VERSION ""

NS_ :

BS_:

BU_: VCM SCIM IC CCM

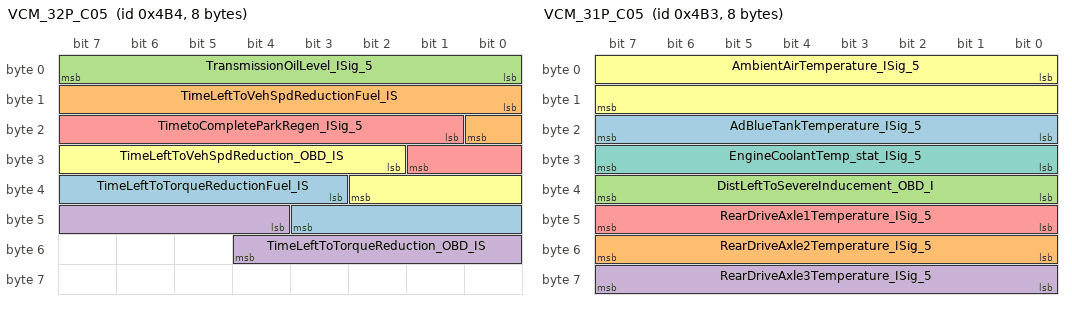
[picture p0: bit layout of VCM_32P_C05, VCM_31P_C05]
BO_ 1204 VCM_32P_C05: 8 VCM
 SG_ TimeLeftToTorqueReductionFuel_IS : 35|9@1+ (12,0) [0|6132] "min"  IC
 SG_ TimeLeftToVehSpdReductionFuel_IS : 8|9@1+ (15,0) [0|7665] "min"  IC
 SG_ TransmissionOilLevel_ISig_5 : 0|8@1+ (0.4,0) [0|102] "Percent"  IC
 SG_ TimeLeftToTorqueReduction_OBD_IS : 44|9@1+ (12,0) [0|6132] "min"  IC
 SG_ TimetoCompleteParkRegen_ISig_5 : 17|9@1+ (15,0) [0|7665] "min"  IC
 SG_ TimeLeftToVehSpdReduction_OBD_IS : 26|9@1+ (15,0) [0|7665] "min"  IC

BO_ 1203 VCM_31P_C05: 8 VCM
 SG_ AdBlueTankTemperature_ISig_5 : 16|8@1+ (1,-50) [-50|205] "DegreeC"  IC
 SG_ RearDriveAxle2Temperature_ISig_5 : 48|8@1+ (1,0) [0|255] "DegreeC"  IC
 SG_ DistLeftToSevereInducement_OBD_I : 32|8@1+ (5,0) [0|1275] "km"  IC
 SG_ RearDriveAxle3Temperature_ISig_5 : 56|8@1+ (1,0) [0|255] "DegreeC"  IC
 SG_ RearDriveAxle1Temperature_ISig_5 : 40|8@1+ (1,0) [0|255] "DegreeC"  IC
 SG_ AmbientAirTemperature_ISig_5 : 0|16@1+ (0.03125,-273) [-273|1774.96875] "DegreeC"  CCM,IC
 SG_ EngineCoolantTemp_stat_ISig_5 : 24|8@1+ (1,-40) [-40|215] "DegreeC"  CCM

BO_ 1202 VCM_30P_C05: 8 VCM
 SG_ FasUsrDefinedDampingSetting_ISig : 42|5@1+ (1,-10) [-10|21] ""  IC
 SG_ SCROperatorInducementSeverity_IS : 12|3@1+ (1,0) [0|0] ""  IC
 SG_ CatalystTankLevelLow_ISig_5 : 57|2@1+ (1,0) [0|0] ""  IC
 SG_ MIStatusExtEMS_ISig_5 : 61|2@1+ (1,0) [0|0] ""  IC
 SG_ FuelOperatorDeratingReason_ISig_ : 4|2@1+ (1,0) [0|0] ""  IC
 SG_ ActualFasPersSettingsButton_ISig : 18|3@1+ (1,0) [0|0] ""  IC
 SG_ BatteryEndOfCharge_ISig_5 : 0|2@1+ (1,0) [0|0] ""  IC
 SG_ FasUsrDefStiffStraightSetting_IS : 32|5@1+ (1,-10) [-10|21] ""  IC
 SG_ LiningWearWarning_ISig_5 : 2|2@1+ (1,0) [0|0] ""  IC
 SG_ TorqueReductionStatus_OBD_ISig_5 : 21|3@1+ (1,0) [0|0] ""  IC
 SG_ LoadCalibrationFeedback_ISig_5 : 9|3@1+ (1,0) [0|0] ""  IC
 SG_ FasUsrDefLowSpeedReturnSetting_I : 47|5@1+ (1,-10) [-10|21] ""  IC
 SG_ FuelOperatorDeratingSeverity_ISi : 6|3@1+ (1,0) [0|0] ""  IC
 SG_ FasUsrDefStiffnessCurveSetting_I : 37|5@1+ (1,-10) [-10|21] ""  IC
 SG_ SCROperatorInducementReason_ISig : 15|3@1+ (1,0) [0|0] ""  IC
 SG_ ActualFasManualOffsetSetting_ISi : 52|5@1+ (1,-10) [-10|21] ""  IC
 SG_ MIDistinctWarningExtEMS_ISig_5 : 24|4@1+ (1,0) [0|0] ""  IC
 SG_ FasDriver_ISig_5 : 28|4@1+ (1,0) [0|0] ""  IC
 SG_ MIDistinctWarning_ISig_5 : 59|2@1+ (1,0) [0|0] ""  IC

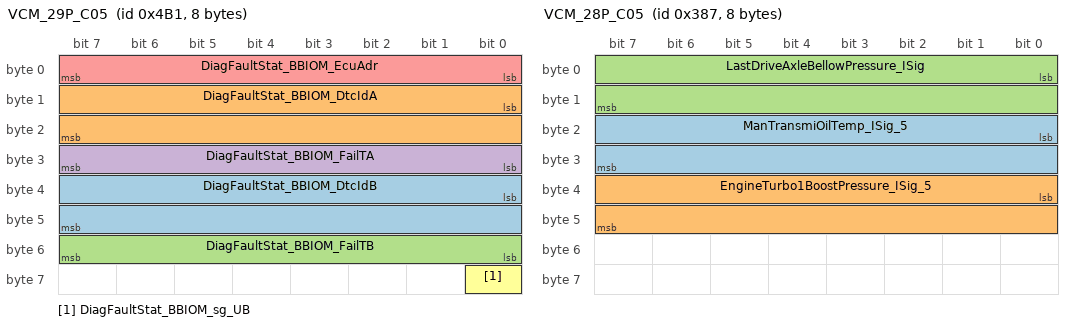
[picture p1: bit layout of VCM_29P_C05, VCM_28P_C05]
BO_ 1201 VCM_29P_C05: 8 VCM
 SG_ DiagFaultStat_BBIOM_DtcIdB : 32|16@1+ (1,0) [0|65535] ""  IC
 SG_ DiagFaultStat_BBIOM_DtcIdA : 8|16@1+ (1,0) [0|65535] ""  IC
 SG_ DiagFaultStat_BBIOM_FailTB : 48|8@1+ (1,0) [0|255] ""  IC
 SG_ DiagFaultStat_BBIOM_FailTA : 24|8@1+ (1,0) [0|255] ""  IC
 SG_ DiagFaultStat_BBIOM_EcuAdr : 0|8@1+ (1,0) [0|255] ""  IC
 SG_ DiagFaultStat_BBIOM_sg_UB : 56|1@1+ (1,0) [0|0] ""  IC

BO_ 903 VCM_28P_C05: 8 VCM
 SG_ ManTransmiOilTemp_ISig_5 : 16|16@1+ (0.03125,-273) [-273|1774.96875] "DegreeC"  IC
 SG_ EngineTurbo1BoostPressure_ISig_5 : 32|16@1+ (0.125,0) [0|8191.875] "kPa"  IC
 SG_ LastDriveAxleBellowPressure_ISig : 0|16@1+ (0.1,0) [0|6553.5] "kPa"  IC

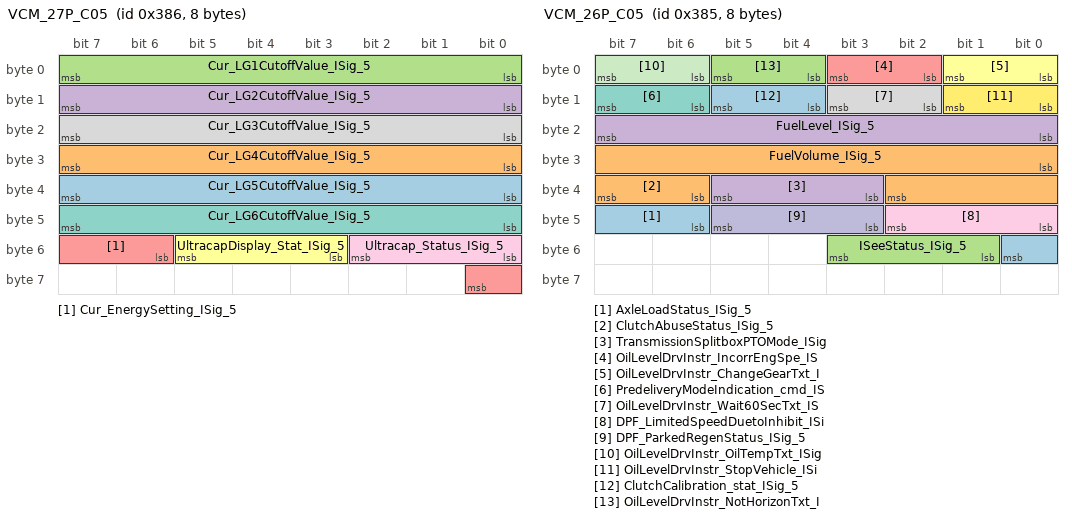
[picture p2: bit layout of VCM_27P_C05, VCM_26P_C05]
BO_ 902 VCM_27P_C05: 8 VCM
 SG_ Cur_LG5CutoffValue_ISig_5 : 32|8@1+ (1,0) [0|255] "Percent"  IC
 SG_ Cur_LG4CutoffValue_ISig_5 : 24|8@1+ (1,0) [0|255] "Percent"  IC
 SG_ Cur_LG1CutoffValue_ISig_5 : 0|8@1+ (1,0) [0|255] "Percent"  IC
 SG_ Cur_LG2CutoffValue_ISig_5 : 8|8@1+ (1,0) [0|255] "Percent"  IC
 SG_ Cur_EnergySetting_ISig_5 : 54|3@1+ (1,0) [0|0] ""  IC
 SG_ UltracapDisplay_Stat_ISig_5 : 51|3@1+ (1,0) [0|0] ""  IC
 SG_ Cur_LG6CutoffValue_ISig_5 : 40|8@1+ (1,0) [0|255] "Percent"  IC
 SG_ Cur_LG3CutoffValue_ISig_5 : 16|8@1+ (1,0) [0|255] "Percent"  IC
 SG_ Ultracap_Status_ISig_5 : 48|3@1+ (1,0) [0|0] ""  IC

BO_ 901 VCM_26P_C05: 8 VCM
 SG_ AxleLoadStatus_ISig_5 : 46|3@1+ (1,0) [0|0] ""  IC
 SG_ ClutchAbuseStatus_ISig_5 : 38|2@1+ (1,0) [0|0] ""  IC
 SG_ ISeeStatus_ISig_5 : 49|3@1+ (1,0) [0|0] ""  IC
 SG_ TransmissionSplitboxPTOMode_ISig : 35|3@1+ (1,0) [0|0] ""  IC
 SG_ OilLevelDrvInstr_IncorrEngSpe_IS : 2|2@1+ (1,0) [0|0] ""  IC
 SG_ OilLevelDrvInstr_ChangeGearTxt_I : 0|2@1+ (1,0) [0|0] ""  IC
 SG_ PredeliveryModeIndication_cmd_IS : 14|2@1+ (1,0) [0|0] ""  IC
 SG_ OilLevelDrvInstr_Wait60SecTxt_IS : 10|2@1+ (1,0) [0|0] ""  IC
 SG_ DPF_LimitedSpeedDuetoInhibit_ISi : 40|3@1+ (1,0) [0|0] ""  IC
 SG_ DPF_ParkedRegenStatus_ISig_5 : 43|3@1+ (1,0) [0|0] ""  IC
 SG_ OilLevelDrvInstr_OilTempTxt_ISig : 6|2@1+ (1,0) [0|0] ""  IC
 SG_ OilLevelDrvInstr_StopVehicle_ISi : 8|2@1+ (1,0) [0|0] ""  IC
 SG_ ClutchCalibration_stat_ISig_5 : 12|2@1+ (1,0) [0|0] ""  IC
 SG_ FuelVolume_ISig_5 : 24|11@1+ (1,0) [0|2047] "l"  CCM,IC
 SG_ OilLevelDrvInstr_NotHorizonTxt_I : 4|2@1+ (1,0) [0|0] ""  IC
 SG_ FuelLevel_ISig_5 : 16|8@1+ (0.4,0) [0|102] "Percent"  IC,CCM

BO_ 868 VCM_25P_C05: 8 VCM
 SG_ DrainPrimingStatus_ISig_5 : 60|3@1+ (1,0) [0|0] ""  IC
 SG_ FrontConspicLamp_stat_HiRight_IS : 0|3@1+ (1,0) [0|0] ""  IC
 SG_ FrontConspicLamp_stat_LoRight_IS : 3|3@1+ (1,0) [0|0] ""  IC
 SG_ CoolantTempHigh_ISig_5 : 54|3@1+ (1,0) [0|0] ""  IC
 SG_ AutoWheelBrakesStatus_ISig_5 : 32|3@1+ (1,0) [0|0] ""  IC
 SG_ OilLevelLow_ISig_5 : 51|3@1+ (1,0) [0|0] ""  IC
 SG_ InletAirHeaterStatus1_ISig_5 : 40|2@1+ (1,0) [0|0] ""  IC
 SG_ DeicingFunction_Stat_ISig_5 : 45|3@1+ (1,0) [0|0] ""  IC
 SG_ SelfStartAssist_stat_ISig_5 : 14|2@1+ (1,0) [0|0] ""  IC
 SG_ TrailerDirIndLeftOutputStat_ISig : 19|3@1+ (1,0) [0|0] ""  IC
 SG_ TrailerPosLightLeftOutputStat_IS : 24|3@1+ (1,0) [0|0] ""  IC
 SG_ TrailerBrakeLightOutputStat_ISig : 16|3@1+ (1,0) [0|0] ""  IC
 SG_ StartBatteryDisplay_stat_ISig_5 : 35|3@1+ (1,0) [0|0] ""  IC
 SG_ DeicingBulb_Stat_ISig_5 : 42|3@1+ (1,0) [0|0] ""  IC
 SG_ LivBatDisconnectDetectStat_ISig_ : 30|2@1+ (1,0) [0|0] ""  IC
 SG_ FrontConspicLamp_stat_LoLeft_ISi : 9|3@1+ (1,0) [0|0] ""  IC
 SG_ FuelFilterClogged_ISig_5 : 57|3@1+ (1,0) [0|0] ""  IC
 SG_ EngineFanOverspeed_ISig_5 : 22|2@1+ (1,0) [0|0] ""  IC
 SG_ JumpChargeInterface_stat_ISig_5 : 38|2@1+ (1,0) [0|0] ""  IC
 SG_ OilPressureLow_ISig_5 : 48|3@1+ (1,0) [0|0] ""  IC
 SG_ FrontConspicLamp_stat_HiLeft_ISi : 6|3@1+ (1,0) [0|0] ""  IC
 SG_ GChargerStatus_ISig_5 : 27|3@1+ (1,0) [0|0] ""  IC
 SG_ TrailerRevAndFogOutput_stat_ISig : 12|2@1+ (1,0) [0|0] ""  IC

BO_ 867 VCM_24P_C05: 8 VCM
 SG_ DirIndSideLamp_stat : 54|3@1+ (1,0) [0|0] ""  IC
 SG_ DirInd_Front_Status_ISig_5 : 27|3@1+ (1,0) [0|0] ""  IC
 SG_ FogLightFrontLamp_stat_ISig_5 : 3|3@1+ (1,0) [0|0] ""  IC
 SG_ MainBeamLEDStatusRight_ISig_5 : 33|3@1+ (1,0) [0|0] ""  IC
 SG_ RevLightLamp_stat_ISig_5 : 0|3@1+ (1,0) [0|0] ""  IC
 SG_ ExtraMainBeamLamp_stat_ISig_5 : 24|3@1+ (1,0) [0|0] ""  IC
 SG_ MainBeamLEDStatusLeft_ISig_5 : 18|3@1+ (1,0) [0|0] ""  IC
 SG_ PositionLightRearLamp_stat_ISig_ : 36|3@1+ (1,0) [0|0] ""  IC
 SG_ TrailerPosLightRightOutputStat_I : 12|3@1+ (1,0) [0|0] ""  IC
 SG_ DirIndRearLamp_Stat_ISig_5 : 51|3@1+ (1,0) [0|0] ""  IC
 SG_ FogLightRearLamp_stat_ISig_5 : 48|3@1+ (1,0) [0|0] ""  IC
 SG_ BrakeLightLamp_stat_ISig_5 : 45|3@1+ (1,0) [0|0] ""  IC
 SG_ DippedBeamLamp_stat_ISig_5 : 15|3@1+ (1,0) [0|0] ""  IC
 SG_ ChassiInstepLightsLamp_stat_ISig : 30|3@1+ (1,0) [0|0] ""  IC
 SG_ DRLLamp_stat_ISig_5 : 42|3@1+ (1,0) [0|0] ""  IC
 SG_ TrailerDirIndRightOutputStat_ISi : 6|3@1+ (1,0) [0|0] ""  IC
 SG_ HeadlampFan_stat_ISig_5 : 60|3@1+ (1,0) [0|0] ""  IC
 SG_ MainBeamLamp_stat_ISig_5 : 21|3@1+ (1,0) [0|0] ""  IC
 SG_ StaticCornerLightLamp_stat_ISig_ : 57|3@1+ (1,0) [0|0] ""  IC
 SG_ AuxFogLightLamp_stat_ISig_5 : 9|3@1+ (1,0) [0|0] ""  IC
 SG_ PositionLightLamp_stat_ISig_5 : 39|3@1+ (1,0) [0|0] ""  IC

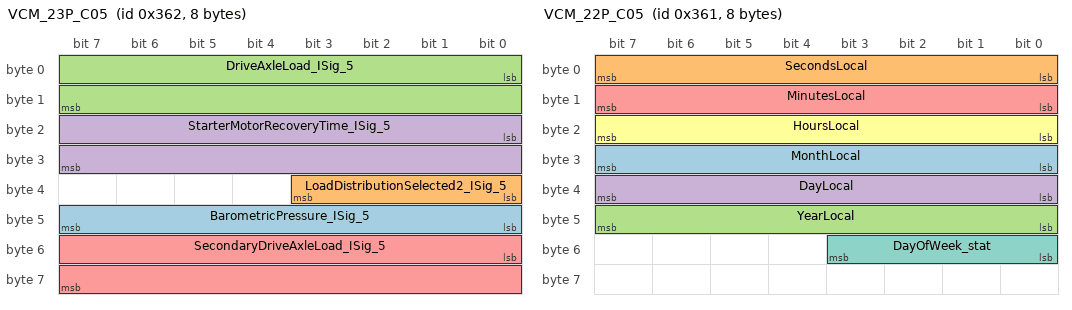
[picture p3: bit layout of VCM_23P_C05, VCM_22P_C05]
BO_ 866 VCM_23P_C05: 8 VCM
 SG_ BarometricPressure_ISig_5 : 40|8@1+ (0.5,0) [0|127.5] "kPa"  CCM
 SG_ LoadDistributionSelected2_ISig_5 : 32|4@1+ (1,0) [0|0] ""  IC
 SG_ DriveAxleLoad_ISig_5 : 0|16@1+ (0.5,0) [0|32767.5] "kg"  IC
 SG_ StarterMotorRecoveryTime_ISig_5 : 16|16@1+ (1,0) [0|65535] "s"  IC
 SG_ SecondaryDriveAxleLoad_ISig_5 : 48|16@1+ (0.5,0) [0|32767.5] "kg"  IC

BO_ 865 VCM_22P_C05: 8 VCM
 SG_ MonthLocal : 24|8@1+ (1,0) [0|255] "Months"  CCM
 SG_ SecondsLocal : 0|8@1+ (0.25,0) [0|63.75] "s"  CCM
 SG_ YearLocal : 40|8@1+ (1,1985) [1985|2240] "Years"  CCM
 SG_ DayLocal : 32|8@1+ (0.25,0) [0|63.75] "Days"  CCM
 SG_ MinutesLocal : 8|8@1+ (1,0) [0|255] "min"  CCM
 SG_ HoursLocal : 16|8@1+ (1,0) [0|255] "h"  CCM
 SG_ DayOfWeek_stat : 48|4@1+ (1,0) [0|0] ""  CCM,IC

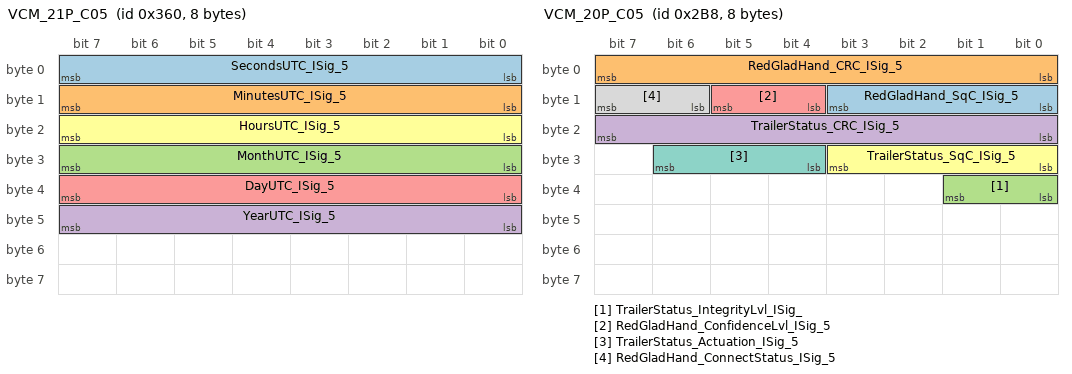
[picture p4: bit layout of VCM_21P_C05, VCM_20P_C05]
BO_ 864 VCM_21P_C05: 8 VCM
 SG_ SecondsUTC_ISig_5 : 0|8@1+ (0.25,0) [0|63.75] "s"  CCM
 SG_ MinutesUTC_ISig_5 : 8|8@1+ (1,0) [0|255] "min"  CCM
 SG_ MonthUTC_ISig_5 : 24|8@1+ (1,0) [0|255] "Months"  CCM
 SG_ YearUTC_ISig_5 : 40|8@1+ (1,1985) [1985|2240] "Years"  CCM
 SG_ DayUTC_ISig_5 : 32|8@1+ (0.25,0) [0|63.75] "Days"  CCM
 SG_ HoursUTC_ISig_5 : 16|8@1+ (1,0) [0|255] "h"  CCM

BO_ 696 VCM_20P_C05: 8 VCM
 SG_ RedGladHand_SqC_ISig_5 : 8|4@1+ (1,0) [0|14] "NotApplicable"  IC
 SG_ RedGladHand_CRC_ISig_5 : 0|8@1+ (1,0) [0|255] ""  IC
 SG_ TrailerStatus_IntegrityLvl_ISig_ : 32|2@1+ (1,0) [0|0] ""  IC
 SG_ TrailerStatus_CRC_ISig_5 : 16|8@1+ (1,0) [0|255] ""  IC
 SG_ RedGladHand_ConfidenceLvl_ISig_5 : 12|2@1+ (1,0) [0|0] ""  IC
 SG_ TrailerStatus_SqC_ISig_5 : 24|4@1+ (1,0) [0|14] "NotApplicable"  IC
 SG_ TrailerStatus_Actuation_ISig_5 : 28|3@1+ (1,0) [0|0] ""  IC
 SG_ RedGladHand_ConnectStatus_ISig_5 : 14|2@1+ (1,0) [0|0] ""  IC

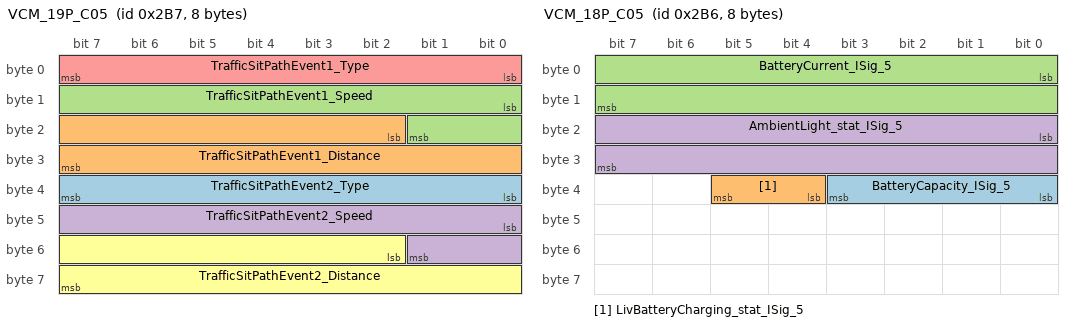
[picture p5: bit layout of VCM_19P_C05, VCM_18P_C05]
BO_ 695 VCM_19P_C05: 8 VCM
 SG_ TrafficSitPathEvent2_Type : 32|8@1+ (1,0) [0|0] ""  IC
 SG_ TrafficSitPathEvent1_Distance : 18|14@1+ (1,0) [0|16383] "m"  IC
 SG_ TrafficSitPathEvent1_Speed : 8|10@1+ (0.25,0) [0|255.75] "Km_per_h"  IC
 SG_ TrafficSitPathEvent2_Speed : 40|10@1+ (0.25,0) [0|255.75] "Km_per_h"  IC
 SG_ TrafficSitPathEvent1_Type : 0|8@1+ (1,0) [0|0] ""  IC
 SG_ TrafficSitPathEvent2_Distance : 50|14@1+ (1,0) [0|16383] "m"  IC

BO_ 694 VCM_18P_C05: 8 VCM
 SG_ BatteryCapacity_ISig_5 : 32|4@1+ (1,0) [0|0] ""  IC
 SG_ LivBatteryCharging_stat_ISig_5 : 36|2@1+ (1,0) [0|0] ""  CCM
 SG_ BatteryCurrent_ISig_5 : 0|16@1+ (0.05,-1600) [-1600|1676.75] "A"  IC
 SG_ AmbientLight_stat_ISig_5 : 16|16@1+ (1,0) [0|65535] "lx"  IC

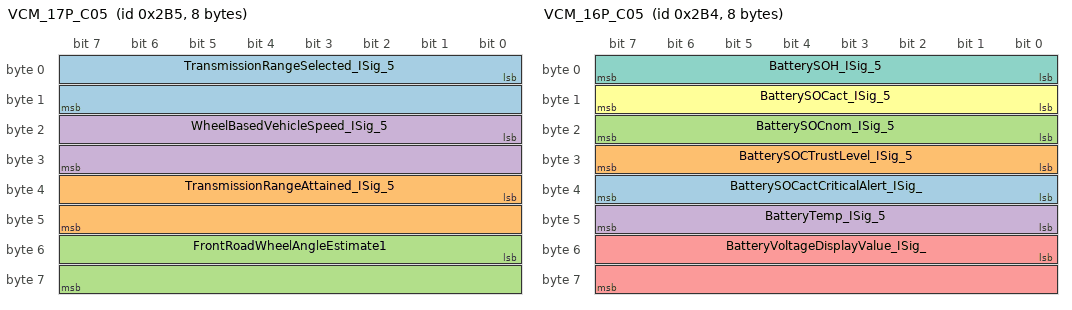
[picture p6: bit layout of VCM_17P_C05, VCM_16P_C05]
BO_ 693 VCM_17P_C05: 8 VCM
 SG_ TransmissionRangeSelected_ISig_5 : 0|16@1+ (1,0) [0|0] ""  IC
 SG_ TransmissionRangeAttained_ISig_5 : 32|16@1+ (1,0) [0|0] ""  IC
 SG_ FrontRoadWheelAngleEstimate1 : 48|16@1+ (5E-005,-1.6) [-1.6|1.67675] "rad"  IC
 SG_ WheelBasedVehicleSpeed_ISig_5 : 16|16@1+ (0.00390625,0) [0|255.99609375] "Km_per_h"  IC,CCM

BO_ 692 VCM_16P_C05: 8 VCM
 SG_ BatterySOCactCriticalAlert_ISig_ : 32|8@1+ (0.5,0) [0|127.5] "Percent"  IC
 SG_ BatterySOCTrustLevel_ISig_5 : 24|8@1+ (0.5,0) [0|127.5] "Percent"  IC
 SG_ BatterySOCnom_ISig_5 : 16|8@1+ (0.5,0) [0|127.5] "Percent"  IC
 SG_ BatteryTemp_ISig_5 : 40|8@1+ (1,-45) [-45|210] "DegreeC"  IC
 SG_ BatteryVoltageDisplayValue_ISig_ : 48|16@1+ (0.05,0) [0|3276.75] "V"  IC
 SG_ BatterySOCact_ISig_5 : 8|8@1+ (0.5,0) [0|127.5] "Percent"  IC
 SG_ BatterySOH_ISig_5 : 0|8@1+ (0.5,0) [0|127.5] "Percent"  IC

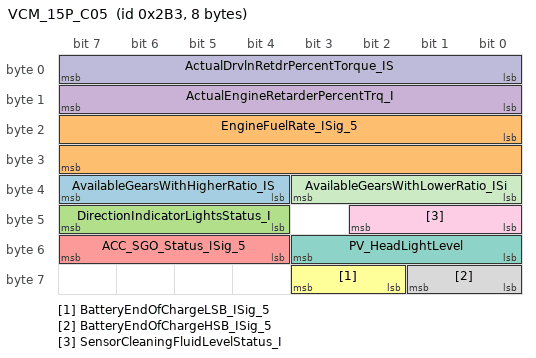
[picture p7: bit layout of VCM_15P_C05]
BO_ 691 VCM_15P_C05: 8 VCM
 SG_ AvailableGearsWithHigherRatio_IS : 36|4@1+ (1,0) [0|15] "Count"  IC
 SG_ EngineFuelRate_ISig_5 : 16|16@1+ (0.05,0) [0|3276.75] "l_per_h"  IC
 SG_ DirectionIndicatorLightsStatus_I : 44|4@1+ (1,0) [0|0] ""  IC
 SG_ ActualEngineRetarderPercentTrq_I : 8|8@1+ (1,-125) [-125|130] "Percent"  IC
 SG_ ACC_SGO_Status_ISig_5 : 52|4@1+ (1,0) [0|0] ""  IC
 SG_ BatteryEndOfChargeLSB_ISig_5 : 58|2@1+ (1,0) [0|0] ""  IC
 SG_ PV_HeadLightLevel : 48|4@1+ (1,-7) [-7|8] "NotApplicable"  IC
 SG_ BatteryEndOfChargeHSB_ISig_5 : 56|2@1+ (1,0) [0|0] ""  IC
 SG_ SensorCleaningFluidLevelStatus_I : 40|3@1+ (1,0) [0|0] ""  IC
 SG_ ActualDrvlnRetdrPercentTorque_IS : 0|8@1+ (1,-125) [-125|130] "Percent"  IC
 SG_ AvailableGearsWithLowerRatio_ISi : 32|4@1+ (1,0) [0|15] "Count"  IC

BO_ 690 VCM_14P_C05: 8 VCM
 SG_ SetHSAOperation_ISig_5 : 49|3@1+ (1,0) [0|0] ""  IC
 SG_ PS_FogLightFront : 12|2@1+ (1,0) [0|0] ""  IC
 SG_ CACCStatus_ISig_5 : 43|3@1+ (1,0) [0|0] ""  IC
 SG_ Cab12VSupplyStatus_ISig_5 : 6|2@1+ (1,0) [0|0] ""  IC
 SG_ TransmissionDrivingMode_ISig_5 : 22|3@1+ (1,0) [0|0] ""  IC,CCM
 SG_ LowAirPressureAlert_ISig_5 : 10|2@1+ (1,0) [0|0] ""  IC
 SG_ TemporaryRSLSwitchStatus : 4|2@1+ (1,0) [0|0] ""  IC
 SG_ BatterySOCAlertRawData_rqst_ISig : 37|3@1+ (1,0) [0|0] ""  IC,CCM
 SG_ BatteryTempAlertRawData_rqst_ISi : 25|3@1+ (1,0) [0|0] ""  IC
 SG_ BrakeTemperatureWarning_ISig_5 : 14|2@1+ (1,0) [0|0] ""  IC
 SG_ WheelSlipControllerMode_ISig_5 : 16|3@1+ (1,0) [0|0] ""  IC
 SG_ Rainsensor_Indication_ISig_5 : 0|2@1+ (1,0) [0|0] ""  IC
 SG_ ESCHealthStatus_ISig_5 : 2|2@1+ (1,0) [0|0] ""  IC
 SG_ TLInflationAcceptance_stat_ISig_ : 31|3@1+ (1,0) [0|0] ""  IC
 SG_ AutoLoadCutOffState_ISig_5 : 34|3@1+ (1,0) [0|0] ""  IC
 SG_ TransmissionOilTempHigh_ISig_5 : 55|3@1+ (1,0) [0|0] ""  IC
 SG_ ECSLimpHomeNotification_ISig_5 : 28|3@1+ (1,0) [0|0] ""  IC
 SG_ EqualizerUnbalance_ISig_5 : 19|3@1+ (1,0) [0|0] ""  IC
 SG_ AutGearSplitPosition_ISig_5 : 52|3@1+ (1,0) [0|0] ""  IC
 SG_ BatterySOCAlert_rqst_ISig_5 : 46|3@1+ (1,0) [0|0] ""  IC
 SG_ DriveModeSwitchUserOverride_ISig : 58|3@1+ (1,0) [0|0] ""  IC
 SG_ BatteryTempAlert_rqst_ISig_5 : 40|3@1+ (1,0) [0|0] ""  IC
 SG_ TrailerEBSFault_ISig_5 : 8|2@1+ (1,0) [0|0] ""  IC

BA_DEF_ BO_  "GenMsgStartDelayTime" INT 0 0;
BA_DEF_ BO_  "GenMsgDelayTime" INT 0 0;
BA_DEF_ BO_  "GenMsgCycleTime" INT 0 0;
BA_DEF_ BO_  "GenMsgSendType" ENUM  "Cyclic","NotUsed","NotUsed","NotUsed","NotUsed","NotUsed","NotUsed","IfActive","NoMsgSendType","NotUsed";
BA_DEF_ SG_  "GenSigStartValue" INT 0 0;
BA_DEF_ SG_  "GenSigCycleTimeActive" INT 0 0;
BA_DEF_ SG_  "GenSigCycleTime" INT 0 0;
BA_DEF_ SG_  "GenSigSendType" ENUM  "Cyclic","OnWrite","OnWriteWithRepetition","OnChange","OnChangeWithRepetition","IfActive","IfActiveWithRepetition","NoSigSendType","NotUsed","NotUsed","NotUsed","NotUsed","NotUsed";
BA_DEF_ BO_  "VFrameFormat" ENUM  "StandardCAN","ExtendedCAN","reserved","J1939PG","reserved","reserved","reserved","reserved","reserved","reserved","reserved","reserved","reserved","reserved","StandardCAN_FD","ExtendedCAN_FD";
BA_DEF_ SG_  "SigType" ENUM  "Default","Range","RangeSigned","ASCII","Discrete","Control","ReferencePGN","DTC","StringDelimiter","StringLength","StringLengthControl";
BA_DEF_ BO_  "NmAsrMessage" ENUM  "No","Yes";
BA_DEF_ SG_  "NeedsUpdateBit" ENUM  "No","Yes";
BA_DEF_ SG_  "MmAnSignal" ENUM  "No","Yes";
BA_DEF_ SG_  "GenSigMaxLatency" INT 0 65535;
BA_DEF_ SG_  "GenSigILSupport" ENUM  "Yes","No";
BA_DEF_ BO_  "GenMsgILSupport" ENUM  "No","Yes";
BA_DEF_ SG_  "E2EProfile" STRING ;
BA_DEF_ SG_  "E2EDataLength" INT 0 65535;
BA_DEF_ SG_  "E2EDataId" INT 0 65535;
BA_DEF_ BO_  "DiagUUDTResponse" ENUM  "No","Yes";
BA_DEF_ BO_  "DiagState" ENUM  "No","Yes";
BA_DEF_ BO_  "DiagResponse" ENUM  "No","Yes";
BA_DEF_ BO_  "DiagRequest" ENUM  "No","Yes";
BA_DEF_ BO_  "DiagConnection" HEX 0 65535;
BA_DEF_ BO_  "CanTpFcFrameId" HEX 0 2147483647;
BA_DEF_ BO_  "CanTpBs" INT 0 255;
BA_DEF_ SG_  "SystemSignalLongSymbol" STRING ;
BA_DEF_REL_ BU_SG_REL_  "GenSigTimeoutTime" INT 0 65535;
BA_DEF_REL_ BU_SG_REL_  "GenSigFirstTimeoutTime" INT 0 65535;
BA_DEF_DEF_  "GenMsgStartDelayTime" 0;
BA_DEF_DEF_  "GenMsgDelayTime" 0;
BA_DEF_DEF_  "GenMsgCycleTime" 0;
BA_DEF_DEF_  "GenMsgSendType" "Cyclic";
BA_DEF_DEF_  "GenSigStartValue" 0;
BA_DEF_DEF_  "GenSigCycleTimeActive" 0;
BA_DEF_DEF_  "GenSigCycleTime" 0;
BA_DEF_DEF_  "GenSigSendType" "Cyclic";
BA_DEF_DEF_  "VFrameFormat" "ExtendedCAN";
BA_DEF_DEF_  "SigType" "Default";
BA_DEF_DEF_  "NmAsrMessage" "No";
BA_DEF_DEF_  "NeedsUpdateBit" "No";
BA_DEF_DEF_  "MmAnSignal" "No";
BA_DEF_DEF_  "GenSigMaxLatency" 0;
BA_DEF_DEF_  "GenSigILSupport" "Yes";
BA_DEF_DEF_  "GenMsgILSupport" "Yes";
BA_DEF_DEF_  "E2EProfile" "none";
BA_DEF_DEF_  "E2EDataLength" 0;
BA_DEF_DEF_  "E2EDataId" 0;
BA_DEF_DEF_  "DiagUUDTResponse" "No";
BA_DEF_DEF_  "DiagState" "No";
BA_DEF_DEF_  "DiagResponse" "No";
BA_DEF_DEF_  "DiagRequest" "No";
BA_DEF_DEF_  "DiagConnection" 0;
BA_DEF_DEF_  "CanTpFcFrameId" 2147483647;
BA_DEF_DEF_  "CanTpBs" 255;
BA_DEF_DEF_REL_ "GenSigTimeoutTime" 0;
BA_DEF_DEF_REL_ "GenSigFirstTimeoutTime" 0;
BA_DEF_DEF_  "SystemSignalLongSymbol" "";
BA_ "VFrameFormat" BO_ 1204 0;
BA_ "GenMsgCycleTime" BO_ 1204 1000;
BA_ "GenMsgStartDelayTime" BO_ 1204 155;
BA_ "VFrameFormat" BO_ 1203 0;
BA_ "GenMsgCycleTime" BO_ 1203 1000;
BA_ "GenMsgStartDelayTime" BO_ 1203 110;
BA_ "VFrameFormat" BO_ 1202 0;
BA_ "GenMsgCycleTime" BO_ 1202 1000;
BA_ "GenMsgStartDelayTime" BO_ 1202 85;
BA_ "VFrameFormat" BO_ 1201 0;
BA_ "GenMsgCycleTime" BO_ 1201 1000;
BA_ "GenMsgStartDelayTime" BO_ 1201 30;
BA_ "VFrameFormat" BO_ 903 0;
BA_ "GenMsgCycleTime" BO_ 903 500;
BA_ "GenMsgStartDelayTime" BO_ 903 120;
BA_ "VFrameFormat" BO_ 902 0;
BA_ "GenMsgCycleTime" BO_ 902 500;
BA_ "GenMsgStartDelayTime" BO_ 902 75;
BA_ "VFrameFormat" BO_ 901 0;
BA_ "GenMsgCycleTime" BO_ 901 500;
BA_ "GenMsgStartDelayTime" BO_ 901 5;
BA_ "VFrameFormat" BO_ 868 0;
BA_ "GenMsgCycleTime" BO_ 868 250;
BA_ "GenMsgStartDelayTime" BO_ 868 120;
BA_ "VFrameFormat" BO_ 867 0;
BA_ "GenMsgCycleTime" BO_ 867 250;
BA_ "GenMsgStartDelayTime" BO_ 867 100;
BA_ "VFrameFormat" BO_ 866 0;
BA_ "GenMsgCycleTime" BO_ 866 250;
BA_ "GenMsgStartDelayTime" BO_ 866 75;
BA_ "VFrameFormat" BO_ 865 0;
BA_ "GenMsgCycleTime" BO_ 865 250;
BA_ "GenMsgStartDelayTime" BO_ 865 40;
BA_ "VFrameFormat" BO_ 864 0;
BA_ "GenMsgCycleTime" BO_ 864 250;
BA_ "GenMsgStartDelayTime" BO_ 864 15;
BA_ "VFrameFormat" BO_ 696 0;
BA_ "GenMsgCycleTime" BO_ 696 100;
BA_ "GenMsgStartDelayTime" BO_ 696 75;
BA_ "VFrameFormat" BO_ 695 0;
BA_ "GenMsgCycleTime" BO_ 695 100;
BA_ "GenMsgStartDelayTime" BO_ 695 60;
BA_ "VFrameFormat" BO_ 694 0;
BA_ "GenMsgCycleTime" BO_ 694 100;
BA_ "GenMsgStartDelayTime" BO_ 694 50;
BA_ "VFrameFormat" BO_ 693 0;
BA_ "GenMsgCycleTime" BO_ 693 100;
BA_ "GenMsgStartDelayTime" BO_ 693 45;
BA_ "VFrameFormat" BO_ 692 0;
BA_ "GenMsgCycleTime" BO_ 692 100;
BA_ "GenMsgStartDelayTime" BO_ 692 40;
BA_ "VFrameFormat" BO_ 691 0;
BA_ "GenMsgCycleTime" BO_ 691 100;
BA_ "GenMsgStartDelayTime" BO_ 691 30;
BA_ "VFrameFormat" BO_ 690 0;
BA_ "GenMsgCycleTime" BO_ 690 100;
BA_ "GenMsgStartDelayTime" BO_ 690 20;
BA_ "GenSigCycleTime" SG_ 1204 TimeLeftToTorqueReductionFuel_IS 100;
BA_ "GenSigCycleTimeActive" SG_ 1204 TimeLeftToTorqueReductionFuel_IS 100;
BA_ "GenSigStartValue" SG_ 1204 TimeLeftToTorqueReductionFuel_IS 511;
BA_ "GenSigMaxLatency" SG_ 1204 TimeLeftToTorqueReductionFuel_IS 1000;
BA_ "SystemSignalLongSymbol" SG_ 1204 TimeLeftToTorqueReductionFuel_IS "TimeLeftToTorqueReductionFuel_ISig_5";
BA_ "GenSigCycleTime" SG_ 1204 TimeLeftToVehSpdReductionFuel_IS 100;
BA_ "GenSigCycleTimeActive" SG_ 1204 TimeLeftToVehSpdReductionFuel_IS 100;
BA_ "GenSigStartValue" SG_ 1204 TimeLeftToVehSpdReductionFuel_IS 511;
BA_ "GenSigMaxLatency" SG_ 1204 TimeLeftToVehSpdReductionFuel_IS 1000;
BA_ "SystemSignalLongSymbol" SG_ 1204 TimeLeftToVehSpdReductionFuel_IS "TimeLeftToVehSpdReductionFuel_ISig_5";
BA_ "GenSigCycleTime" SG_ 1204 TransmissionOilLevel_ISig_5 100;
BA_ "GenSigCycleTimeActive" SG_ 1204 TransmissionOilLevel_ISig_5 100;
BA_ "GenSigStartValue" SG_ 1204 TransmissionOilLevel_ISig_5 255;
BA_ "GenSigMaxLatency" SG_ 1204 TransmissionOilLevel_ISig_5 1000;
BA_ "GenSigCycleTime" SG_ 1204 TimeLeftToTorqueReduction_OBD_IS 100;
BA_ "GenSigCycleTimeActive" SG_ 1204 TimeLeftToTorqueReduction_OBD_IS 100;
BA_ "GenSigStartValue" SG_ 1204 TimeLeftToTorqueReduction_OBD_IS 511;
BA_ "GenSigMaxLatency" SG_ 1204 TimeLeftToTorqueReduction_OBD_IS 1000;
BA_ "SystemSignalLongSymbol" SG_ 1204 TimeLeftToTorqueReduction_OBD_IS "TimeLeftToTorqueReduction_OBD_ISig_5";
BA_ "GenSigCycleTime" SG_ 1204 TimetoCompleteParkRegen_ISig_5 100;
BA_ "GenSigCycleTimeActive" SG_ 1204 TimetoCompleteParkRegen_ISig_5 100;
BA_ "GenSigStartValue" SG_ 1204 TimetoCompleteParkRegen_ISig_5 511;
BA_ "GenSigMaxLatency" SG_ 1204 TimetoCompleteParkRegen_ISig_5 1000;
BA_ "GenSigCycleTime" SG_ 1204 TimeLeftToVehSpdReduction_OBD_IS 100;
BA_ "GenSigCycleTimeActive" SG_ 1204 TimeLeftToVehSpdReduction_OBD_IS 100;
BA_ "GenSigStartValue" SG_ 1204 TimeLeftToVehSpdReduction_OBD_IS 511;
BA_ "GenSigMaxLatency" SG_ 1204 TimeLeftToVehSpdReduction_OBD_IS 1000;
BA_ "SystemSignalLongSymbol" SG_ 1204 TimeLeftToVehSpdReduction_OBD_IS "TimeLeftToVehSpdReduction_OBD_ISig_5";
BA_ "GenSigCycleTime" SG_ 1203 AdBlueTankTemperature_ISig_5 100;
BA_ "GenSigCycleTimeActive" SG_ 1203 AdBlueTankTemperature_ISig_5 100;
BA_ "GenSigStartValue" SG_ 1203 AdBlueTankTemperature_ISig_5 255;
BA_ "GenSigMaxLatency" SG_ 1203 AdBlueTankTemperature_ISig_5 1000;
BA_ "GenSigCycleTime" SG_ 1203 RearDriveAxle2Temperature_ISig_5 100;
BA_ "GenSigCycleTimeActive" SG_ 1203 RearDriveAxle2Temperature_ISig_5 100;
BA_ "GenSigStartValue" SG_ 1203 RearDriveAxle2Temperature_ISig_5 255;
BA_ "GenSigMaxLatency" SG_ 1203 RearDriveAxle2Temperature_ISig_5 1000;
BA_ "GenSigCycleTime" SG_ 1203 DistLeftToSevereInducement_OBD_I 100;
BA_ "GenSigCycleTimeActive" SG_ 1203 DistLeftToSevereInducement_OBD_I 100;
BA_ "GenSigStartValue" SG_ 1203 DistLeftToSevereInducement_OBD_I 255;
BA_ "GenSigMaxLatency" SG_ 1203 DistLeftToSevereInducement_OBD_I 1000;
BA_ "SystemSignalLongSymbol" SG_ 1203 DistLeftToSevereInducement_OBD_I "DistLeftToSevereInducement_OBD_ISig_5";
BA_ "GenSigCycleTime" SG_ 1203 RearDriveAxle3Temperature_ISig_5 100;
BA_ "GenSigCycleTimeActive" SG_ 1203 RearDriveAxle3Temperature_ISig_5 100;
BA_ "GenSigStartValue" SG_ 1203 RearDriveAxle3Temperature_ISig_5 255;
BA_ "GenSigMaxLatency" SG_ 1203 RearDriveAxle3Temperature_ISig_5 1000;
BA_ "GenSigCycleTime" SG_ 1203 RearDriveAxle1Temperature_ISig_5 100;
BA_ "GenSigCycleTimeActive" SG_ 1203 RearDriveAxle1Temperature_ISig_5 100;
BA_ "GenSigStartValue" SG_ 1203 RearDriveAxle1Temperature_ISig_5 255;
BA_ "GenSigMaxLatency" SG_ 1203 RearDriveAxle1Temperature_ISig_5 1000;
BA_ "GenSigCycleTime" SG_ 1203 AmbientAirTemperature_ISig_5 100;
BA_ "GenSigCycleTimeActive" SG_ 1203 AmbientAirTemperature_ISig_5 100;
BA_ "GenSigStartValue" SG_ 1203 AmbientAirTemperature_ISig_5 65535;
BA_ "GenSigMaxLatency" SG_ 1203 AmbientAirTemperature_ISig_5 1000;
BA_ "GenSigCycleTime" SG_ 1203 EngineCoolantTemp_stat_ISig_5 100;
BA_ "GenSigCycleTimeActive" SG_ 1203 EngineCoolantTemp_stat_ISig_5 100;
BA_ "GenSigStartValue" SG_ 1203 EngineCoolantTemp_stat_ISig_5 255;
BA_ "GenSigMaxLatency" SG_ 1203 EngineCoolantTemp_stat_ISig_5 1000;
BA_ "GenSigCycleTime" SG_ 1202 FasUsrDefinedDampingSetting_ISig 100;
BA_ "GenSigCycleTimeActive" SG_ 1202 FasUsrDefinedDampingSetting_ISig 100;
BA_ "GenSigStartValue" SG_ 1202 FasUsrDefinedDampingSetting_ISig 31;
BA_ "GenSigMaxLatency" SG_ 1202 FasUsrDefinedDampingSetting_ISig 1000;
BA_ "SystemSignalLongSymbol" SG_ 1202 FasUsrDefinedDampingSetting_ISig "FasUsrDefinedDampingSetting_ISig_5";
BA_ "GenSigCycleTime" SG_ 1202 SCROperatorInducementSeverity_IS 100;
BA_ "GenSigCycleTimeActive" SG_ 1202 SCROperatorInducementSeverity_IS 100;
BA_ "GenSigStartValue" SG_ 1202 SCROperatorInducementSeverity_IS 7;
BA_ "GenSigMaxLatency" SG_ 1202 SCROperatorInducementSeverity_IS 1000;
BA_ "SystemSignalLongSymbol" SG_ 1202 SCROperatorInducementSeverity_IS "SCROperatorInducementSeverity_ISig_5";
BA_ "GenSigCycleTime" SG_ 1202 CatalystTankLevelLow_ISig_5 100;
BA_ "GenSigCycleTimeActive" SG_ 1202 CatalystTankLevelLow_ISig_5 100;
BA_ "GenSigStartValue" SG_ 1202 CatalystTankLevelLow_ISig_5 3;
BA_ "GenSigMaxLatency" SG_ 1202 CatalystTankLevelLow_ISig_5 1000;
BA_ "GenSigCycleTime" SG_ 1202 MIStatusExtEMS_ISig_5 100;
BA_ "GenSigCycleTimeActive" SG_ 1202 MIStatusExtEMS_ISig_5 100;
BA_ "GenSigStartValue" SG_ 1202 MIStatusExtEMS_ISig_5 3;
BA_ "GenSigMaxLatency" SG_ 1202 MIStatusExtEMS_ISig_5 1000;
BA_ "GenSigCycleTime" SG_ 1202 FuelOperatorDeratingReason_ISig_ 100;
BA_ "GenSigCycleTimeActive" SG_ 1202 FuelOperatorDeratingReason_ISig_ 100;
BA_ "GenSigStartValue" SG_ 1202 FuelOperatorDeratingReason_ISig_ 3;
BA_ "GenSigMaxLatency" SG_ 1202 FuelOperatorDeratingReason_ISig_ 1000;
BA_ "SystemSignalLongSymbol" SG_ 1202 FuelOperatorDeratingReason_ISig_ "FuelOperatorDeratingReason_ISig_5";
BA_ "GenSigCycleTime" SG_ 1202 ActualFasPersSettingsButton_ISig 100;
BA_ "GenSigCycleTimeActive" SG_ 1202 ActualFasPersSettingsButton_ISig 100;
BA_ "GenSigStartValue" SG_ 1202 ActualFasPersSettingsButton_ISig 7;
BA_ "GenSigMaxLatency" SG_ 1202 ActualFasPersSettingsButton_ISig 1000;
BA_ "SystemSignalLongSymbol" SG_ 1202 ActualFasPersSettingsButton_ISig "ActualFasPersSettingsButton_ISig_5";
BA_ "GenSigCycleTime" SG_ 1202 BatteryEndOfCharge_ISig_5 100;
BA_ "GenSigCycleTimeActive" SG_ 1202 BatteryEndOfCharge_ISig_5 100;
BA_ "GenSigStartValue" SG_ 1202 BatteryEndOfCharge_ISig_5 3;
BA_ "GenSigMaxLatency" SG_ 1202 BatteryEndOfCharge_ISig_5 1000;
BA_ "GenSigCycleTime" SG_ 1202 FasUsrDefStiffStraightSetting_IS 100;
BA_ "GenSigCycleTimeActive" SG_ 1202 FasUsrDefStiffStraightSetting_IS 100;
BA_ "GenSigStartValue" SG_ 1202 FasUsrDefStiffStraightSetting_IS 31;
BA_ "GenSigMaxLatency" SG_ 1202 FasUsrDefStiffStraightSetting_IS 1000;
BA_ "SystemSignalLongSymbol" SG_ 1202 FasUsrDefStiffStraightSetting_IS "FasUsrDefStiffStraightSetting_ISig_5";
BA_ "GenSigCycleTime" SG_ 1202 LiningWearWarning_ISig_5 100;
BA_ "GenSigCycleTimeActive" SG_ 1202 LiningWearWarning_ISig_5 100;
BA_ "GenSigStartValue" SG_ 1202 LiningWearWarning_ISig_5 3;
BA_ "GenSigMaxLatency" SG_ 1202 LiningWearWarning_ISig_5 1000;
BA_ "GenSigCycleTime" SG_ 1202 TorqueReductionStatus_OBD_ISig_5 100;
BA_ "GenSigCycleTimeActive" SG_ 1202 TorqueReductionStatus_OBD_ISig_5 100;
BA_ "GenSigStartValue" SG_ 1202 TorqueReductionStatus_OBD_ISig_5 7;
BA_ "GenSigMaxLatency" SG_ 1202 TorqueReductionStatus_OBD_ISig_5 1000;
BA_ "GenSigCycleTime" SG_ 1202 LoadCalibrationFeedback_ISig_5 100;
BA_ "GenSigCycleTimeActive" SG_ 1202 LoadCalibrationFeedback_ISig_5 100;
BA_ "GenSigStartValue" SG_ 1202 LoadCalibrationFeedback_ISig_5 7;
BA_ "GenSigMaxLatency" SG_ 1202 LoadCalibrationFeedback_ISig_5 1000;
BA_ "GenSigCycleTime" SG_ 1202 FasUsrDefLowSpeedReturnSetting_I 100;
BA_ "GenSigCycleTimeActive" SG_ 1202 FasUsrDefLowSpeedReturnSetting_I 100;
BA_ "GenSigStartValue" SG_ 1202 FasUsrDefLowSpeedReturnSetting_I 31;
BA_ "GenSigMaxLatency" SG_ 1202 FasUsrDefLowSpeedReturnSetting_I 1000;
BA_ "SystemSignalLongSymbol" SG_ 1202 FasUsrDefLowSpeedReturnSetting_I "FasUsrDefLowSpeedReturnSetting_ISig_5";
BA_ "GenSigCycleTime" SG_ 1202 FuelOperatorDeratingSeverity_ISi 100;
BA_ "GenSigCycleTimeActive" SG_ 1202 FuelOperatorDeratingSeverity_ISi 100;
BA_ "GenSigStartValue" SG_ 1202 FuelOperatorDeratingSeverity_ISi 7;
BA_ "GenSigMaxLatency" SG_ 1202 FuelOperatorDeratingSeverity_ISi 1000;
BA_ "SystemSignalLongSymbol" SG_ 1202 FuelOperatorDeratingSeverity_ISi "FuelOperatorDeratingSeverity_ISig_5";
BA_ "GenSigCycleTime" SG_ 1202 FasUsrDefStiffnessCurveSetting_I 100;
BA_ "GenSigCycleTimeActive" SG_ 1202 FasUsrDefStiffnessCurveSetting_I 100;
BA_ "GenSigStartValue" SG_ 1202 FasUsrDefStiffnessCurveSetting_I 31;
BA_ "GenSigMaxLatency" SG_ 1202 FasUsrDefStiffnessCurveSetting_I 1000;
BA_ "SystemSignalLongSymbol" SG_ 1202 FasUsrDefStiffnessCurveSetting_I "FasUsrDefStiffnessCurveSetting_ISig_5";
BA_ "GenSigCycleTime" SG_ 1202 SCROperatorInducementReason_ISig 100;
BA_ "GenSigCycleTimeActive" SG_ 1202 SCROperatorInducementReason_ISig 100;
BA_ "GenSigStartValue" SG_ 1202 SCROperatorInducementReason_ISig 7;
BA_ "GenSigMaxLatency" SG_ 1202 SCROperatorInducementReason_ISig 1000;
BA_ "SystemSignalLongSymbol" SG_ 1202 SCROperatorInducementReason_ISig "SCROperatorInducementReason_ISig_5";
BA_ "GenSigCycleTime" SG_ 1202 ActualFasManualOffsetSetting_ISi 100;
BA_ "GenSigCycleTimeActive" SG_ 1202 ActualFasManualOffsetSetting_ISi 100;
BA_ "GenSigStartValue" SG_ 1202 ActualFasManualOffsetSetting_ISi 31;
BA_ "GenSigMaxLatency" SG_ 1202 ActualFasManualOffsetSetting_ISi 1000;
BA_ "SystemSignalLongSymbol" SG_ 1202 ActualFasManualOffsetSetting_ISi "ActualFasManualOffsetSetting_ISig_5";
BA_ "GenSigCycleTime" SG_ 1202 MIDistinctWarningExtEMS_ISig_5 100;
BA_ "GenSigCycleTimeActive" SG_ 1202 MIDistinctWarningExtEMS_ISig_5 100;
BA_ "GenSigStartValue" SG_ 1202 MIDistinctWarningExtEMS_ISig_5 15;
BA_ "GenSigMaxLatency" SG_ 1202 MIDistinctWarningExtEMS_ISig_5 1000;
BA_ "GenSigCycleTime" SG_ 1202 FasDriver_ISig_5 100;
BA_ "GenSigCycleTimeActive" SG_ 1202 FasDriver_ISig_5 100;
BA_ "GenSigStartValue" SG_ 1202 FasDriver_ISig_5 15;
BA_ "GenSigMaxLatency" SG_ 1202 FasDriver_ISig_5 1000;
BA_ "GenSigCycleTime" SG_ 1202 MIDistinctWarning_ISig_5 100;
BA_ "GenSigCycleTimeActive" SG_ 1202 MIDistinctWarning_ISig_5 100;
BA_ "GenSigStartValue" SG_ 1202 MIDistinctWarning_ISig_5 3;
BA_ "GenSigMaxLatency" SG_ 1202 MIDistinctWarning_ISig_5 1000;
BA_ "GenSigCycleTime" SG_ 1201 DiagFaultStat_BBIOM_DtcIdB 100;
BA_ "GenSigCycleTimeActive" SG_ 1201 DiagFaultStat_BBIOM_DtcIdB 100;
BA_ "GenSigStartValue" SG_ 1201 DiagFaultStat_BBIOM_DtcIdB 65535;
BA_ "GenSigMaxLatency" SG_ 1201 DiagFaultStat_BBIOM_DtcIdB 1000;
BA_ "NeedsUpdateBit" SG_ 1201 DiagFaultStat_BBIOM_DtcIdB 1;
BA_ "GenSigCycleTime" SG_ 1201 DiagFaultStat_BBIOM_DtcIdA 100;
BA_ "GenSigCycleTimeActive" SG_ 1201 DiagFaultStat_BBIOM_DtcIdA 100;
BA_ "GenSigStartValue" SG_ 1201 DiagFaultStat_BBIOM_DtcIdA 65535;
BA_ "GenSigMaxLatency" SG_ 1201 DiagFaultStat_BBIOM_DtcIdA 1000;
BA_ "NeedsUpdateBit" SG_ 1201 DiagFaultStat_BBIOM_DtcIdA 1;
BA_ "GenSigCycleTime" SG_ 1201 DiagFaultStat_BBIOM_FailTB 100;
BA_ "GenSigCycleTimeActive" SG_ 1201 DiagFaultStat_BBIOM_FailTB 100;
BA_ "GenSigStartValue" SG_ 1201 DiagFaultStat_BBIOM_FailTB 255;
BA_ "GenSigMaxLatency" SG_ 1201 DiagFaultStat_BBIOM_FailTB 1000;
BA_ "NeedsUpdateBit" SG_ 1201 DiagFaultStat_BBIOM_FailTB 1;
BA_ "GenSigCycleTime" SG_ 1201 DiagFaultStat_BBIOM_FailTA 100;
BA_ "GenSigCycleTimeActive" SG_ 1201 DiagFaultStat_BBIOM_FailTA 100;
BA_ "GenSigStartValue" SG_ 1201 DiagFaultStat_BBIOM_FailTA 255;
BA_ "GenSigMaxLatency" SG_ 1201 DiagFaultStat_BBIOM_FailTA 1000;
BA_ "NeedsUpdateBit" SG_ 1201 DiagFaultStat_BBIOM_FailTA 1;
BA_ "GenSigCycleTime" SG_ 1201 DiagFaultStat_BBIOM_EcuAdr 100;
BA_ "GenSigCycleTimeActive" SG_ 1201 DiagFaultStat_BBIOM_EcuAdr 100;
BA_ "GenSigStartValue" SG_ 1201 DiagFaultStat_BBIOM_EcuAdr 255;
BA_ "GenSigMaxLatency" SG_ 1201 DiagFaultStat_BBIOM_EcuAdr 1000;
BA_ "NeedsUpdateBit" SG_ 1201 DiagFaultStat_BBIOM_EcuAdr 1;
BA_ "GenSigSendType" SG_ 1201 DiagFaultStat_BBIOM_sg_UB 7;
BA_ "GenSigCycleTime" SG_ 903 ManTransmiOilTemp_ISig_5 100;
BA_ "GenSigCycleTimeActive" SG_ 903 ManTransmiOilTemp_ISig_5 100;
BA_ "GenSigStartValue" SG_ 903 ManTransmiOilTemp_ISig_5 65535;
BA_ "GenSigMaxLatency" SG_ 903 ManTransmiOilTemp_ISig_5 500;
BA_ "GenSigCycleTime" SG_ 903 EngineTurbo1BoostPressure_ISig_5 100;
BA_ "GenSigCycleTimeActive" SG_ 903 EngineTurbo1BoostPressure_ISig_5 100;
BA_ "GenSigStartValue" SG_ 903 EngineTurbo1BoostPressure_ISig_5 65535;
BA_ "GenSigMaxLatency" SG_ 903 EngineTurbo1BoostPressure_ISig_5 500;
BA_ "GenSigCycleTime" SG_ 903 LastDriveAxleBellowPressure_ISig 100;
BA_ "GenSigCycleTimeActive" SG_ 903 LastDriveAxleBellowPressure_ISig 100;
BA_ "GenSigStartValue" SG_ 903 LastDriveAxleBellowPressure_ISig 65535;
BA_ "GenSigMaxLatency" SG_ 903 LastDriveAxleBellowPressure_ISig 500;
BA_ "SystemSignalLongSymbol" SG_ 903 LastDriveAxleBellowPressure_ISig "LastDriveAxleBellowPressure_ISig_5";
BA_ "GenSigCycleTime" SG_ 902 Cur_LG5CutoffValue_ISig_5 100;
BA_ "GenSigCycleTimeActive" SG_ 902 Cur_LG5CutoffValue_ISig_5 100;
BA_ "GenSigStartValue" SG_ 902 Cur_LG5CutoffValue_ISig_5 255;
BA_ "GenSigMaxLatency" SG_ 902 Cur_LG5CutoffValue_ISig_5 500;
BA_ "GenSigCycleTime" SG_ 902 Cur_LG4CutoffValue_ISig_5 100;
BA_ "GenSigCycleTimeActive" SG_ 902 Cur_LG4CutoffValue_ISig_5 100;
BA_ "GenSigStartValue" SG_ 902 Cur_LG4CutoffValue_ISig_5 255;
BA_ "GenSigMaxLatency" SG_ 902 Cur_LG4CutoffValue_ISig_5 500;
BA_ "GenSigCycleTime" SG_ 902 Cur_LG1CutoffValue_ISig_5 100;
BA_ "GenSigCycleTimeActive" SG_ 902 Cur_LG1CutoffValue_ISig_5 100;
BA_ "GenSigStartValue" SG_ 902 Cur_LG1CutoffValue_ISig_5 255;
BA_ "GenSigMaxLatency" SG_ 902 Cur_LG1CutoffValue_ISig_5 500;
BA_ "GenSigCycleTime" SG_ 902 Cur_LG2CutoffValue_ISig_5 100;
BA_ "GenSigCycleTimeActive" SG_ 902 Cur_LG2CutoffValue_ISig_5 100;
BA_ "GenSigStartValue" SG_ 902 Cur_LG2CutoffValue_ISig_5 255;
BA_ "GenSigMaxLatency" SG_ 902 Cur_LG2CutoffValue_ISig_5 500;
BA_ "GenSigCycleTime" SG_ 902 Cur_EnergySetting_ISig_5 100;
BA_ "GenSigCycleTimeActive" SG_ 902 Cur_EnergySetting_ISig_5 100;
BA_ "GenSigStartValue" SG_ 902 Cur_EnergySetting_ISig_5 7;
BA_ "GenSigMaxLatency" SG_ 902 Cur_EnergySetting_ISig_5 500;
BA_ "GenSigCycleTime" SG_ 902 UltracapDisplay_Stat_ISig_5 100;
BA_ "GenSigCycleTimeActive" SG_ 902 UltracapDisplay_Stat_ISig_5 100;
BA_ "GenSigStartValue" SG_ 902 UltracapDisplay_Stat_ISig_5 7;
BA_ "GenSigMaxLatency" SG_ 902 UltracapDisplay_Stat_ISig_5 500;
BA_ "GenSigCycleTime" SG_ 902 Cur_LG6CutoffValue_ISig_5 100;
BA_ "GenSigCycleTimeActive" SG_ 902 Cur_LG6CutoffValue_ISig_5 100;
BA_ "GenSigStartValue" SG_ 902 Cur_LG6CutoffValue_ISig_5 255;
BA_ "GenSigMaxLatency" SG_ 902 Cur_LG6CutoffValue_ISig_5 500;
BA_ "GenSigCycleTime" SG_ 902 Cur_LG3CutoffValue_ISig_5 100;
BA_ "GenSigCycleTimeActive" SG_ 902 Cur_LG3CutoffValue_ISig_5 100;
BA_ "GenSigStartValue" SG_ 902 Cur_LG3CutoffValue_ISig_5 255;
BA_ "GenSigMaxLatency" SG_ 902 Cur_LG3CutoffValue_ISig_5 500;
BA_ "GenSigCycleTime" SG_ 902 Ultracap_Status_ISig_5 100;
BA_ "GenSigCycleTimeActive" SG_ 902 Ultracap_Status_ISig_5 100;
BA_ "GenSigStartValue" SG_ 902 Ultracap_Status_ISig_5 7;
BA_ "GenSigMaxLatency" SG_ 902 Ultracap_Status_ISig_5 500;
BA_ "GenSigCycleTime" SG_ 901 AxleLoadStatus_ISig_5 100;
BA_ "GenSigCycleTimeActive" SG_ 901 AxleLoadStatus_ISig_5 100;
BA_ "GenSigStartValue" SG_ 901 AxleLoadStatus_ISig_5 7;
BA_ "GenSigMaxLatency" SG_ 901 AxleLoadStatus_ISig_5 500;
BA_ "GenSigCycleTime" SG_ 901 ClutchAbuseStatus_ISig_5 100;
BA_ "GenSigCycleTimeActive" SG_ 901 ClutchAbuseStatus_ISig_5 100;
BA_ "GenSigStartValue" SG_ 901 ClutchAbuseStatus_ISig_5 3;
BA_ "GenSigMaxLatency" SG_ 901 ClutchAbuseStatus_ISig_5 500;
BA_ "GenSigCycleTime" SG_ 901 ISeeStatus_ISig_5 100;
BA_ "GenSigCycleTimeActive" SG_ 901 ISeeStatus_ISig_5 100;
BA_ "GenSigStartValue" SG_ 901 ISeeStatus_ISig_5 7;
BA_ "GenSigMaxLatency" SG_ 901 ISeeStatus_ISig_5 500;
BA_ "GenSigCycleTime" SG_ 901 TransmissionSplitboxPTOMode_ISig 100;
BA_ "GenSigCycleTimeActive" SG_ 901 TransmissionSplitboxPTOMode_ISig 100;
BA_ "GenSigStartValue" SG_ 901 TransmissionSplitboxPTOMode_ISig 7;
BA_ "GenSigMaxLatency" SG_ 901 TransmissionSplitboxPTOMode_ISig 500;
BA_ "SystemSignalLongSymbol" SG_ 901 TransmissionSplitboxPTOMode_ISig "TransmissionSplitboxPTOMode_ISig_5";
BA_ "GenSigCycleTime" SG_ 901 OilLevelDrvInstr_IncorrEngSpe_IS 100;
BA_ "GenSigCycleTimeActive" SG_ 901 OilLevelDrvInstr_IncorrEngSpe_IS 100;
BA_ "GenSigStartValue" SG_ 901 OilLevelDrvInstr_IncorrEngSpe_IS 3;
BA_ "GenSigMaxLatency" SG_ 901 OilLevelDrvInstr_IncorrEngSpe_IS 500;
BA_ "SystemSignalLongSymbol" SG_ 901 OilLevelDrvInstr_IncorrEngSpe_IS "OilLevelDrvInstr_IncorrEngSpe_ISig_5";
BA_ "GenSigCycleTime" SG_ 901 OilLevelDrvInstr_ChangeGearTxt_I 100;
BA_ "GenSigCycleTimeActive" SG_ 901 OilLevelDrvInstr_ChangeGearTxt_I 100;
BA_ "GenSigStartValue" SG_ 901 OilLevelDrvInstr_ChangeGearTxt_I 3;
BA_ "GenSigMaxLatency" SG_ 901 OilLevelDrvInstr_ChangeGearTxt_I 500;
BA_ "SystemSignalLongSymbol" SG_ 901 OilLevelDrvInstr_ChangeGearTxt_I "OilLevelDrvInstr_ChangeGearTxt_ISig_5";
BA_ "GenSigCycleTime" SG_ 901 PredeliveryModeIndication_cmd_IS 100;
BA_ "GenSigCycleTimeActive" SG_ 901 PredeliveryModeIndication_cmd_IS 100;
BA_ "GenSigStartValue" SG_ 901 PredeliveryModeIndication_cmd_IS 3;
BA_ "GenSigMaxLatency" SG_ 901 PredeliveryModeIndication_cmd_IS 500;
BA_ "SystemSignalLongSymbol" SG_ 901 PredeliveryModeIndication_cmd_IS "PredeliveryModeIndication_cmd_ISig_5";
BA_ "GenSigCycleTime" SG_ 901 OilLevelDrvInstr_Wait60SecTxt_IS 100;
BA_ "GenSigCycleTimeActive" SG_ 901 OilLevelDrvInstr_Wait60SecTxt_IS 100;
BA_ "GenSigStartValue" SG_ 901 OilLevelDrvInstr_Wait60SecTxt_IS 3;
BA_ "GenSigMaxLatency" SG_ 901 OilLevelDrvInstr_Wait60SecTxt_IS 500;
BA_ "SystemSignalLongSymbol" SG_ 901 OilLevelDrvInstr_Wait60SecTxt_IS "OilLevelDrvInstr_Wait60SecTxt_ISig_5";
BA_ "GenSigCycleTime" SG_ 901 DPF_LimitedSpeedDuetoInhibit_ISi 100;
BA_ "GenSigCycleTimeActive" SG_ 901 DPF_LimitedSpeedDuetoInhibit_ISi 100;
BA_ "GenSigStartValue" SG_ 901 DPF_LimitedSpeedDuetoInhibit_ISi 7;
BA_ "GenSigMaxLatency" SG_ 901 DPF_LimitedSpeedDuetoInhibit_ISi 500;
BA_ "SystemSignalLongSymbol" SG_ 901 DPF_LimitedSpeedDuetoInhibit_ISi "DPF_LimitedSpeedDuetoInhibit_ISig_5";
BA_ "GenSigCycleTime" SG_ 901 DPF_ParkedRegenStatus_ISig_5 100;
BA_ "GenSigCycleTimeActive" SG_ 901 DPF_ParkedRegenStatus_ISig_5 100;
BA_ "GenSigStartValue" SG_ 901 DPF_ParkedRegenStatus_ISig_5 7;
BA_ "GenSigMaxLatency" SG_ 901 DPF_ParkedRegenStatus_ISig_5 500;
BA_ "GenSigCycleTime" SG_ 901 OilLevelDrvInstr_OilTempTxt_ISig 100;
BA_ "GenSigCycleTimeActive" SG_ 901 OilLevelDrvInstr_OilTempTxt_ISig 100;
BA_ "GenSigStartValue" SG_ 901 OilLevelDrvInstr_OilTempTxt_ISig 3;
BA_ "GenSigMaxLatency" SG_ 901 OilLevelDrvInstr_OilTempTxt_ISig 500;
BA_ "SystemSignalLongSymbol" SG_ 901 OilLevelDrvInstr_OilTempTxt_ISig "OilLevelDrvInstr_OilTempTxt_ISig_5";
BA_ "GenSigCycleTime" SG_ 901 OilLevelDrvInstr_StopVehicle_ISi 100;
BA_ "GenSigCycleTimeActive" SG_ 901 OilLevelDrvInstr_StopVehicle_ISi 100;
BA_ "GenSigStartValue" SG_ 901 OilLevelDrvInstr_StopVehicle_ISi 3;
BA_ "GenSigMaxLatency" SG_ 901 OilLevelDrvInstr_StopVehicle_ISi 500;
BA_ "SystemSignalLongSymbol" SG_ 901 OilLevelDrvInstr_StopVehicle_ISi "OilLevelDrvInstr_StopVehicle_ISig_5";
BA_ "GenSigCycleTime" SG_ 901 ClutchCalibration_stat_ISig_5 100;
BA_ "GenSigCycleTimeActive" SG_ 901 ClutchCalibration_stat_ISig_5 100;
BA_ "GenSigStartValue" SG_ 901 ClutchCalibration_stat_ISig_5 3;
BA_ "GenSigMaxLatency" SG_ 901 ClutchCalibration_stat_ISig_5 500;
BA_ "GenSigCycleTime" SG_ 901 FuelVolume_ISig_5 100;
BA_ "GenSigCycleTimeActive" SG_ 901 FuelVolume_ISig_5 100;
BA_ "GenSigStartValue" SG_ 901 FuelVolume_ISig_5 2047;
BA_ "GenSigMaxLatency" SG_ 901 FuelVolume_ISig_5 500;
BA_ "GenSigCycleTime" SG_ 901 OilLevelDrvInstr_NotHorizonTxt_I 100;
BA_ "GenSigCycleTimeActive" SG_ 901 OilLevelDrvInstr_NotHorizonTxt_I 100;
BA_ "GenSigStartValue" SG_ 901 OilLevelDrvInstr_NotHorizonTxt_I 3;
BA_ "GenSigMaxLatency" SG_ 901 OilLevelDrvInstr_NotHorizonTxt_I 500;
BA_ "SystemSignalLongSymbol" SG_ 901 OilLevelDrvInstr_NotHorizonTxt_I "OilLevelDrvInstr_NotHorizonTxt_ISig_5";
BA_ "GenSigCycleTime" SG_ 901 FuelLevel_ISig_5 100;
BA_ "GenSigCycleTimeActive" SG_ 901 FuelLevel_ISig_5 100;
BA_ "GenSigStartValue" SG_ 901 FuelLevel_ISig_5 255;
BA_ "GenSigMaxLatency" SG_ 901 FuelLevel_ISig_5 500;
BA_ "GenSigCycleTime" SG_ 868 DrainPrimingStatus_ISig_5 100;
BA_ "GenSigCycleTimeActive" SG_ 868 DrainPrimingStatus_ISig_5 100;
BA_ "GenSigStartValue" SG_ 868 DrainPrimingStatus_ISig_5 7;
BA_ "GenSigMaxLatency" SG_ 868 DrainPrimingStatus_ISig_5 250;
BA_ "GenSigCycleTime" SG_ 868 FrontConspicLamp_stat_HiRight_IS 100;
BA_ "GenSigCycleTimeActive" SG_ 868 FrontConspicLamp_stat_HiRight_IS 100;
BA_ "GenSigStartValue" SG_ 868 FrontConspicLamp_stat_HiRight_IS 7;
BA_ "GenSigMaxLatency" SG_ 868 FrontConspicLamp_stat_HiRight_IS 250;
BA_ "SystemSignalLongSymbol" SG_ 868 FrontConspicLamp_stat_HiRight_IS "FrontConspicLamp_stat_HiRight_ISig_5";
BA_ "GenSigCycleTime" SG_ 868 FrontConspicLamp_stat_LoRight_IS 100;
BA_ "GenSigCycleTimeActive" SG_ 868 FrontConspicLamp_stat_LoRight_IS 100;
BA_ "GenSigStartValue" SG_ 868 FrontConspicLamp_stat_LoRight_IS 7;
BA_ "GenSigMaxLatency" SG_ 868 FrontConspicLamp_stat_LoRight_IS 250;
BA_ "SystemSignalLongSymbol" SG_ 868 FrontConspicLamp_stat_LoRight_IS "FrontConspicLamp_stat_LoRight_ISig_5";
BA_ "GenSigCycleTime" SG_ 868 CoolantTempHigh_ISig_5 100;
BA_ "GenSigCycleTimeActive" SG_ 868 CoolantTempHigh_ISig_5 100;
BA_ "GenSigStartValue" SG_ 868 CoolantTempHigh_ISig_5 7;
BA_ "GenSigMaxLatency" SG_ 868 CoolantTempHigh_ISig_5 250;
BA_ "GenSigCycleTime" SG_ 868 AutoWheelBrakesStatus_ISig_5 100;
BA_ "GenSigCycleTimeActive" SG_ 868 AutoWheelBrakesStatus_ISig_5 100;
BA_ "GenSigStartValue" SG_ 868 AutoWheelBrakesStatus_ISig_5 7;
BA_ "GenSigMaxLatency" SG_ 868 AutoWheelBrakesStatus_ISig_5 250;
BA_ "GenSigCycleTime" SG_ 868 OilLevelLow_ISig_5 100;
BA_ "GenSigCycleTimeActive" SG_ 868 OilLevelLow_ISig_5 100;
BA_ "GenSigStartValue" SG_ 868 OilLevelLow_ISig_5 7;
BA_ "GenSigMaxLatency" SG_ 868 OilLevelLow_ISig_5 250;
BA_ "GenSigCycleTime" SG_ 868 InletAirHeaterStatus1_ISig_5 100;
BA_ "GenSigCycleTimeActive" SG_ 868 InletAirHeaterStatus1_ISig_5 100;
BA_ "GenSigStartValue" SG_ 868 InletAirHeaterStatus1_ISig_5 3;
BA_ "GenSigMaxLatency" SG_ 868 InletAirHeaterStatus1_ISig_5 250;
BA_ "GenSigCycleTime" SG_ 868 DeicingFunction_Stat_ISig_5 100;
BA_ "GenSigCycleTimeActive" SG_ 868 DeicingFunction_Stat_ISig_5 100;
BA_ "GenSigStartValue" SG_ 868 DeicingFunction_Stat_ISig_5 7;
BA_ "GenSigMaxLatency" SG_ 868 DeicingFunction_Stat_ISig_5 250;
BA_ "GenSigCycleTime" SG_ 868 SelfStartAssist_stat_ISig_5 100;
BA_ "GenSigCycleTimeActive" SG_ 868 SelfStartAssist_stat_ISig_5 100;
BA_ "GenSigStartValue" SG_ 868 SelfStartAssist_stat_ISig_5 3;
BA_ "GenSigMaxLatency" SG_ 868 SelfStartAssist_stat_ISig_5 250;
BA_ "GenSigCycleTime" SG_ 868 TrailerDirIndLeftOutputStat_ISig 100;
BA_ "GenSigCycleTimeActive" SG_ 868 TrailerDirIndLeftOutputStat_ISig 100;
BA_ "GenSigStartValue" SG_ 868 TrailerDirIndLeftOutputStat_ISig 7;
BA_ "GenSigMaxLatency" SG_ 868 TrailerDirIndLeftOutputStat_ISig 250;
BA_ "SystemSignalLongSymbol" SG_ 868 TrailerDirIndLeftOutputStat_ISig "TrailerDirIndLeftOutputStat_ISig_5";
BA_ "GenSigCycleTime" SG_ 868 TrailerPosLightLeftOutputStat_IS 100;
BA_ "GenSigCycleTimeActive" SG_ 868 TrailerPosLightLeftOutputStat_IS 100;
BA_ "GenSigStartValue" SG_ 868 TrailerPosLightLeftOutputStat_IS 7;
BA_ "GenSigMaxLatency" SG_ 868 TrailerPosLightLeftOutputStat_IS 250;
BA_ "SystemSignalLongSymbol" SG_ 868 TrailerPosLightLeftOutputStat_IS "TrailerPosLightLeftOutputStat_ISig_5";
BA_ "GenSigCycleTime" SG_ 868 TrailerBrakeLightOutputStat_ISig 100;
BA_ "GenSigCycleTimeActive" SG_ 868 TrailerBrakeLightOutputStat_ISig 100;
BA_ "GenSigStartValue" SG_ 868 TrailerBrakeLightOutputStat_ISig 7;
BA_ "GenSigMaxLatency" SG_ 868 TrailerBrakeLightOutputStat_ISig 250;
BA_ "SystemSignalLongSymbol" SG_ 868 TrailerBrakeLightOutputStat_ISig "TrailerBrakeLightOutputStat_ISig_5";
BA_ "GenSigCycleTime" SG_ 868 StartBatteryDisplay_stat_ISig_5 100;
BA_ "GenSigCycleTimeActive" SG_ 868 StartBatteryDisplay_stat_ISig_5 100;
BA_ "GenSigStartValue" SG_ 868 StartBatteryDisplay_stat_ISig_5 7;
BA_ "GenSigMaxLatency" SG_ 868 StartBatteryDisplay_stat_ISig_5 250;
BA_ "GenSigCycleTime" SG_ 868 DeicingBulb_Stat_ISig_5 100;
BA_ "GenSigCycleTimeActive" SG_ 868 DeicingBulb_Stat_ISig_5 100;
BA_ "GenSigStartValue" SG_ 868 DeicingBulb_Stat_ISig_5 7;
BA_ "GenSigMaxLatency" SG_ 868 DeicingBulb_Stat_ISig_5 250;
BA_ "GenSigCycleTime" SG_ 868 LivBatDisconnectDetectStat_ISig_ 100;
BA_ "GenSigCycleTimeActive" SG_ 868 LivBatDisconnectDetectStat_ISig_ 100;
BA_ "GenSigStartValue" SG_ 868 LivBatDisconnectDetectStat_ISig_ 3;
BA_ "GenSigMaxLatency" SG_ 868 LivBatDisconnectDetectStat_ISig_ 250;
BA_ "SystemSignalLongSymbol" SG_ 868 LivBatDisconnectDetectStat_ISig_ "LivBatDisconnectDetectStat_ISig_5";
BA_ "GenSigCycleTime" SG_ 868 FrontConspicLamp_stat_LoLeft_ISi 100;
BA_ "GenSigCycleTimeActive" SG_ 868 FrontConspicLamp_stat_LoLeft_ISi 100;
BA_ "GenSigStartValue" SG_ 868 FrontConspicLamp_stat_LoLeft_ISi 7;
BA_ "GenSigMaxLatency" SG_ 868 FrontConspicLamp_stat_LoLeft_ISi 250;
BA_ "SystemSignalLongSymbol" SG_ 868 FrontConspicLamp_stat_LoLeft_ISi "FrontConspicLamp_stat_LoLeft_ISig_5";
BA_ "GenSigCycleTime" SG_ 868 FuelFilterClogged_ISig_5 100;
BA_ "GenSigCycleTimeActive" SG_ 868 FuelFilterClogged_ISig_5 100;
BA_ "GenSigStartValue" SG_ 868 FuelFilterClogged_ISig_5 7;
BA_ "GenSigMaxLatency" SG_ 868 FuelFilterClogged_ISig_5 250;
BA_ "GenSigCycleTime" SG_ 868 EngineFanOverspeed_ISig_5 100;
BA_ "GenSigCycleTimeActive" SG_ 868 EngineFanOverspeed_ISig_5 100;
BA_ "GenSigStartValue" SG_ 868 EngineFanOverspeed_ISig_5 3;
BA_ "GenSigMaxLatency" SG_ 868 EngineFanOverspeed_ISig_5 250;
BA_ "GenSigCycleTime" SG_ 868 JumpChargeInterface_stat_ISig_5 100;
BA_ "GenSigCycleTimeActive" SG_ 868 JumpChargeInterface_stat_ISig_5 100;
BA_ "GenSigStartValue" SG_ 868 JumpChargeInterface_stat_ISig_5 3;
BA_ "GenSigMaxLatency" SG_ 868 JumpChargeInterface_stat_ISig_5 250;
BA_ "GenSigCycleTime" SG_ 868 OilPressureLow_ISig_5 100;
BA_ "GenSigCycleTimeActive" SG_ 868 OilPressureLow_ISig_5 100;
BA_ "GenSigStartValue" SG_ 868 OilPressureLow_ISig_5 7;
BA_ "GenSigMaxLatency" SG_ 868 OilPressureLow_ISig_5 250;
BA_ "GenSigCycleTime" SG_ 868 FrontConspicLamp_stat_HiLeft_ISi 100;
BA_ "GenSigCycleTimeActive" SG_ 868 FrontConspicLamp_stat_HiLeft_ISi 100;
BA_ "GenSigStartValue" SG_ 868 FrontConspicLamp_stat_HiLeft_ISi 7;
BA_ "GenSigMaxLatency" SG_ 868 FrontConspicLamp_stat_HiLeft_ISi 250;
BA_ "SystemSignalLongSymbol" SG_ 868 FrontConspicLamp_stat_HiLeft_ISi "FrontConspicLamp_stat_HiLeft_ISig_5";
BA_ "GenSigCycleTime" SG_ 868 GChargerStatus_ISig_5 100;
BA_ "GenSigCycleTimeActive" SG_ 868 GChargerStatus_ISig_5 100;
BA_ "GenSigStartValue" SG_ 868 GChargerStatus_ISig_5 7;
BA_ "GenSigMaxLatency" SG_ 868 GChargerStatus_ISig_5 250;
BA_ "GenSigCycleTime" SG_ 868 TrailerRevAndFogOutput_stat_ISig 100;
BA_ "GenSigCycleTimeActive" SG_ 868 TrailerRevAndFogOutput_stat_ISig 100;
BA_ "GenSigStartValue" SG_ 868 TrailerRevAndFogOutput_stat_ISig 3;
BA_ "GenSigMaxLatency" SG_ 868 TrailerRevAndFogOutput_stat_ISig 250;
BA_ "SystemSignalLongSymbol" SG_ 868 TrailerRevAndFogOutput_stat_ISig "TrailerRevAndFogOutput_stat_ISig_5";
BA_ "GenSigCycleTime" SG_ 867 DirIndSideLamp_stat 100;
BA_ "GenSigCycleTimeActive" SG_ 867 DirIndSideLamp_stat 100;
BA_ "GenSigStartValue" SG_ 867 DirIndSideLamp_stat 7;
BA_ "GenSigMaxLatency" SG_ 867 DirIndSideLamp_stat 250;
BA_ "GenSigCycleTime" SG_ 867 DirInd_Front_Status_ISig_5 100;
BA_ "GenSigCycleTimeActive" SG_ 867 DirInd_Front_Status_ISig_5 100;
BA_ "GenSigStartValue" SG_ 867 DirInd_Front_Status_ISig_5 7;
BA_ "GenSigMaxLatency" SG_ 867 DirInd_Front_Status_ISig_5 250;
BA_ "GenSigCycleTime" SG_ 867 FogLightFrontLamp_stat_ISig_5 100;
BA_ "GenSigCycleTimeActive" SG_ 867 FogLightFrontLamp_stat_ISig_5 100;
BA_ "GenSigStartValue" SG_ 867 FogLightFrontLamp_stat_ISig_5 7;
BA_ "GenSigMaxLatency" SG_ 867 FogLightFrontLamp_stat_ISig_5 250;
BA_ "GenSigCycleTime" SG_ 867 MainBeamLEDStatusRight_ISig_5 100;
BA_ "GenSigCycleTimeActive" SG_ 867 MainBeamLEDStatusRight_ISig_5 100;
BA_ "GenSigStartValue" SG_ 867 MainBeamLEDStatusRight_ISig_5 7;
BA_ "GenSigMaxLatency" SG_ 867 MainBeamLEDStatusRight_ISig_5 250;
BA_ "GenSigCycleTime" SG_ 867 RevLightLamp_stat_ISig_5 100;
BA_ "GenSigCycleTimeActive" SG_ 867 RevLightLamp_stat_ISig_5 100;
BA_ "GenSigStartValue" SG_ 867 RevLightLamp_stat_ISig_5 7;
BA_ "GenSigMaxLatency" SG_ 867 RevLightLamp_stat_ISig_5 250;
BA_ "GenSigCycleTime" SG_ 867 ExtraMainBeamLamp_stat_ISig_5 100;
BA_ "GenSigCycleTimeActive" SG_ 867 ExtraMainBeamLamp_stat_ISig_5 100;
BA_ "GenSigStartValue" SG_ 867 ExtraMainBeamLamp_stat_ISig_5 7;
BA_ "GenSigMaxLatency" SG_ 867 ExtraMainBeamLamp_stat_ISig_5 250;
BA_ "GenSigCycleTime" SG_ 867 MainBeamLEDStatusLeft_ISig_5 100;
BA_ "GenSigCycleTimeActive" SG_ 867 MainBeamLEDStatusLeft_ISig_5 100;
BA_ "GenSigStartValue" SG_ 867 MainBeamLEDStatusLeft_ISig_5 7;
BA_ "GenSigMaxLatency" SG_ 867 MainBeamLEDStatusLeft_ISig_5 250;
BA_ "GenSigCycleTime" SG_ 867 PositionLightRearLamp_stat_ISig_ 100;
BA_ "GenSigCycleTimeActive" SG_ 867 PositionLightRearLamp_stat_ISig_ 100;
BA_ "GenSigStartValue" SG_ 867 PositionLightRearLamp_stat_ISig_ 7;
BA_ "GenSigMaxLatency" SG_ 867 PositionLightRearLamp_stat_ISig_ 250;
BA_ "SystemSignalLongSymbol" SG_ 867 PositionLightRearLamp_stat_ISig_ "PositionLightRearLamp_stat_ISig_5";
BA_ "GenSigCycleTime" SG_ 867 TrailerPosLightRightOutputStat_I 100;
BA_ "GenSigCycleTimeActive" SG_ 867 TrailerPosLightRightOutputStat_I 100;
BA_ "GenSigStartValue" SG_ 867 TrailerPosLightRightOutputStat_I 7;
BA_ "GenSigMaxLatency" SG_ 867 TrailerPosLightRightOutputStat_I 250;
BA_ "SystemSignalLongSymbol" SG_ 867 TrailerPosLightRightOutputStat_I "TrailerPosLightRightOutputStat_ISig_5";
BA_ "GenSigCycleTime" SG_ 867 DirIndRearLamp_Stat_ISig_5 100;
BA_ "GenSigCycleTimeActive" SG_ 867 DirIndRearLamp_Stat_ISig_5 100;
BA_ "GenSigStartValue" SG_ 867 DirIndRearLamp_Stat_ISig_5 7;
BA_ "GenSigMaxLatency" SG_ 867 DirIndRearLamp_Stat_ISig_5 250;
BA_ "GenSigCycleTime" SG_ 867 FogLightRearLamp_stat_ISig_5 100;
BA_ "GenSigCycleTimeActive" SG_ 867 FogLightRearLamp_stat_ISig_5 100;
BA_ "GenSigStartValue" SG_ 867 FogLightRearLamp_stat_ISig_5 7;
BA_ "GenSigMaxLatency" SG_ 867 FogLightRearLamp_stat_ISig_5 250;
BA_ "GenSigCycleTime" SG_ 867 BrakeLightLamp_stat_ISig_5 100;
BA_ "GenSigCycleTimeActive" SG_ 867 BrakeLightLamp_stat_ISig_5 100;
BA_ "GenSigStartValue" SG_ 867 BrakeLightLamp_stat_ISig_5 7;
BA_ "GenSigMaxLatency" SG_ 867 BrakeLightLamp_stat_ISig_5 250;
BA_ "GenSigCycleTime" SG_ 867 DippedBeamLamp_stat_ISig_5 100;
BA_ "GenSigCycleTimeActive" SG_ 867 DippedBeamLamp_stat_ISig_5 100;
BA_ "GenSigStartValue" SG_ 867 DippedBeamLamp_stat_ISig_5 7;
BA_ "GenSigMaxLatency" SG_ 867 DippedBeamLamp_stat_ISig_5 250;
BA_ "GenSigCycleTime" SG_ 867 ChassiInstepLightsLamp_stat_ISig 100;
BA_ "GenSigCycleTimeActive" SG_ 867 ChassiInstepLightsLamp_stat_ISig 100;
BA_ "GenSigStartValue" SG_ 867 ChassiInstepLightsLamp_stat_ISig 7;
BA_ "GenSigMaxLatency" SG_ 867 ChassiInstepLightsLamp_stat_ISig 250;
BA_ "SystemSignalLongSymbol" SG_ 867 ChassiInstepLightsLamp_stat_ISig "ChassiInstepLightsLamp_stat_ISig_5";
BA_ "GenSigCycleTime" SG_ 867 DRLLamp_stat_ISig_5 100;
BA_ "GenSigCycleTimeActive" SG_ 867 DRLLamp_stat_ISig_5 100;
BA_ "GenSigStartValue" SG_ 867 DRLLamp_stat_ISig_5 7;
BA_ "GenSigMaxLatency" SG_ 867 DRLLamp_stat_ISig_5 250;
BA_ "GenSigCycleTime" SG_ 867 TrailerDirIndRightOutputStat_ISi 100;
BA_ "GenSigCycleTimeActive" SG_ 867 TrailerDirIndRightOutputStat_ISi 100;
BA_ "GenSigStartValue" SG_ 867 TrailerDirIndRightOutputStat_ISi 7;
BA_ "GenSigMaxLatency" SG_ 867 TrailerDirIndRightOutputStat_ISi 250;
BA_ "SystemSignalLongSymbol" SG_ 867 TrailerDirIndRightOutputStat_ISi "TrailerDirIndRightOutputStat_ISig_5";
BA_ "GenSigCycleTime" SG_ 867 HeadlampFan_stat_ISig_5 100;
BA_ "GenSigCycleTimeActive" SG_ 867 HeadlampFan_stat_ISig_5 100;
BA_ "GenSigStartValue" SG_ 867 HeadlampFan_stat_ISig_5 7;
BA_ "GenSigMaxLatency" SG_ 867 HeadlampFan_stat_ISig_5 250;
BA_ "GenSigCycleTime" SG_ 867 MainBeamLamp_stat_ISig_5 100;
BA_ "GenSigCycleTimeActive" SG_ 867 MainBeamLamp_stat_ISig_5 100;
BA_ "GenSigStartValue" SG_ 867 MainBeamLamp_stat_ISig_5 7;
BA_ "GenSigMaxLatency" SG_ 867 MainBeamLamp_stat_ISig_5 250;
BA_ "GenSigCycleTime" SG_ 867 StaticCornerLightLamp_stat_ISig_ 100;
BA_ "GenSigCycleTimeActive" SG_ 867 StaticCornerLightLamp_stat_ISig_ 100;
BA_ "GenSigStartValue" SG_ 867 StaticCornerLightLamp_stat_ISig_ 7;
BA_ "GenSigMaxLatency" SG_ 867 StaticCornerLightLamp_stat_ISig_ 250;
BA_ "SystemSignalLongSymbol" SG_ 867 StaticCornerLightLamp_stat_ISig_ "StaticCornerLightLamp_stat_ISig_5";
BA_ "GenSigCycleTime" SG_ 867 AuxFogLightLamp_stat_ISig_5 100;
BA_ "GenSigCycleTimeActive" SG_ 867 AuxFogLightLamp_stat_ISig_5 100;
BA_ "GenSigStartValue" SG_ 867 AuxFogLightLamp_stat_ISig_5 7;
BA_ "GenSigMaxLatency" SG_ 867 AuxFogLightLamp_stat_ISig_5 250;
BA_ "GenSigCycleTime" SG_ 867 PositionLightLamp_stat_ISig_5 100;
BA_ "GenSigCycleTimeActive" SG_ 867 PositionLightLamp_stat_ISig_5 100;
BA_ "GenSigStartValue" SG_ 867 PositionLightLamp_stat_ISig_5 7;
BA_ "GenSigMaxLatency" SG_ 867 PositionLightLamp_stat_ISig_5 250;
BA_ "GenSigCycleTime" SG_ 866 BarometricPressure_ISig_5 100;
BA_ "GenSigCycleTimeActive" SG_ 866 BarometricPressure_ISig_5 100;
BA_ "GenSigStartValue" SG_ 866 BarometricPressure_ISig_5 255;
BA_ "GenSigMaxLatency" SG_ 866 BarometricPressure_ISig_5 250;
BA_ "GenSigCycleTime" SG_ 866 LoadDistributionSelected2_ISig_5 100;
BA_ "GenSigCycleTimeActive" SG_ 866 LoadDistributionSelected2_ISig_5 100;
BA_ "GenSigStartValue" SG_ 866 LoadDistributionSelected2_ISig_5 15;
BA_ "GenSigMaxLatency" SG_ 866 LoadDistributionSelected2_ISig_5 260;
BA_ "GenSigCycleTime" SG_ 866 DriveAxleLoad_ISig_5 100;
BA_ "GenSigCycleTimeActive" SG_ 866 DriveAxleLoad_ISig_5 100;
BA_ "GenSigStartValue" SG_ 866 DriveAxleLoad_ISig_5 65535;
BA_ "GenSigMaxLatency" SG_ 866 DriveAxleLoad_ISig_5 250;
BA_ "GenSigCycleTime" SG_ 866 StarterMotorRecoveryTime_ISig_5 100;
BA_ "GenSigCycleTimeActive" SG_ 866 StarterMotorRecoveryTime_ISig_5 100;
BA_ "GenSigStartValue" SG_ 866 StarterMotorRecoveryTime_ISig_5 65535;
BA_ "GenSigMaxLatency" SG_ 866 StarterMotorRecoveryTime_ISig_5 250;
BA_ "GenSigCycleTime" SG_ 866 SecondaryDriveAxleLoad_ISig_5 100;
BA_ "GenSigCycleTimeActive" SG_ 866 SecondaryDriveAxleLoad_ISig_5 100;
BA_ "GenSigStartValue" SG_ 866 SecondaryDriveAxleLoad_ISig_5 65535;
BA_ "GenSigMaxLatency" SG_ 866 SecondaryDriveAxleLoad_ISig_5 250;
BA_ "GenSigCycleTime" SG_ 865 MonthLocal 100;
BA_ "GenSigCycleTimeActive" SG_ 865 MonthLocal 100;
BA_ "GenSigStartValue" SG_ 865 MonthLocal 255;
BA_ "GenSigMaxLatency" SG_ 865 MonthLocal 250;
BA_ "GenSigCycleTime" SG_ 865 SecondsLocal 100;
BA_ "GenSigCycleTimeActive" SG_ 865 SecondsLocal 100;
BA_ "GenSigStartValue" SG_ 865 SecondsLocal 255;
BA_ "GenSigMaxLatency" SG_ 865 SecondsLocal 250;
BA_ "GenSigCycleTime" SG_ 865 YearLocal 100;
BA_ "GenSigCycleTimeActive" SG_ 865 YearLocal 100;
BA_ "GenSigStartValue" SG_ 865 YearLocal 255;
BA_ "GenSigMaxLatency" SG_ 865 YearLocal 250;
BA_ "GenSigCycleTime" SG_ 865 DayLocal 100;
BA_ "GenSigCycleTimeActive" SG_ 865 DayLocal 100;
BA_ "GenSigStartValue" SG_ 865 DayLocal 255;
BA_ "GenSigMaxLatency" SG_ 865 DayLocal 250;
BA_ "GenSigCycleTime" SG_ 865 MinutesLocal 100;
BA_ "GenSigCycleTimeActive" SG_ 865 MinutesLocal 100;
BA_ "GenSigStartValue" SG_ 865 MinutesLocal 255;
BA_ "GenSigMaxLatency" SG_ 865 MinutesLocal 250;
BA_ "GenSigCycleTime" SG_ 865 HoursLocal 100;
BA_ "GenSigCycleTimeActive" SG_ 865 HoursLocal 100;
BA_ "GenSigStartValue" SG_ 865 HoursLocal 255;
BA_ "GenSigMaxLatency" SG_ 865 HoursLocal 250;
BA_ "GenSigCycleTime" SG_ 865 DayOfWeek_stat 100;
BA_ "GenSigCycleTimeActive" SG_ 865 DayOfWeek_stat 100;
BA_ "GenSigStartValue" SG_ 865 DayOfWeek_stat 15;
BA_ "GenSigMaxLatency" SG_ 865 DayOfWeek_stat 250;
BA_ "GenSigCycleTime" SG_ 864 SecondsUTC_ISig_5 100;
BA_ "GenSigCycleTimeActive" SG_ 864 SecondsUTC_ISig_5 100;
BA_ "GenSigStartValue" SG_ 864 SecondsUTC_ISig_5 255;
BA_ "GenSigMaxLatency" SG_ 864 SecondsUTC_ISig_5 255;
BA_ "GenSigCycleTime" SG_ 864 MinutesUTC_ISig_5 100;
BA_ "GenSigCycleTimeActive" SG_ 864 MinutesUTC_ISig_5 100;
BA_ "GenSigStartValue" SG_ 864 MinutesUTC_ISig_5 255;
BA_ "GenSigMaxLatency" SG_ 864 MinutesUTC_ISig_5 255;
BA_ "GenSigCycleTime" SG_ 864 MonthUTC_ISig_5 100;
BA_ "GenSigCycleTimeActive" SG_ 864 MonthUTC_ISig_5 100;
BA_ "GenSigStartValue" SG_ 864 MonthUTC_ISig_5 255;
BA_ "GenSigMaxLatency" SG_ 864 MonthUTC_ISig_5 255;
BA_ "GenSigCycleTime" SG_ 864 YearUTC_ISig_5 100;
BA_ "GenSigCycleTimeActive" SG_ 864 YearUTC_ISig_5 100;
BA_ "GenSigStartValue" SG_ 864 YearUTC_ISig_5 255;
BA_ "GenSigMaxLatency" SG_ 864 YearUTC_ISig_5 255;
BA_ "GenSigCycleTime" SG_ 864 DayUTC_ISig_5 100;
BA_ "GenSigCycleTimeActive" SG_ 864 DayUTC_ISig_5 100;
BA_ "GenSigStartValue" SG_ 864 DayUTC_ISig_5 255;
BA_ "GenSigMaxLatency" SG_ 864 DayUTC_ISig_5 255;
BA_ "GenSigCycleTime" SG_ 864 HoursUTC_ISig_5 100;
BA_ "GenSigCycleTimeActive" SG_ 864 HoursUTC_ISig_5 100;
BA_ "GenSigStartValue" SG_ 864 HoursUTC_ISig_5 255;
BA_ "GenSigMaxLatency" SG_ 864 HoursUTC_ISig_5 255;
BA_ "GenSigCycleTime" SG_ 696 RedGladHand_SqC_ISig_5 100;
BA_ "GenSigCycleTimeActive" SG_ 696 RedGladHand_SqC_ISig_5 100;
BA_ "GenSigStartValue" SG_ 696 RedGladHand_SqC_ISig_5 14;
BA_ "GenSigMaxLatency" SG_ 696 RedGladHand_SqC_ISig_5 110;
BA_ "GenSigCycleTime" SG_ 696 RedGladHand_CRC_ISig_5 100;
BA_ "GenSigCycleTimeActive" SG_ 696 RedGladHand_CRC_ISig_5 100;
BA_ "GenSigStartValue" SG_ 696 RedGladHand_CRC_ISig_5 255;
BA_ "GenSigMaxLatency" SG_ 696 RedGladHand_CRC_ISig_5 110;
BA_ "E2EDataId" SG_ 696 RedGladHand_CRC_ISig_5 146;
BA_ "E2EDataLength" SG_ 696 RedGladHand_CRC_ISig_5 16;
BA_ "E2EProfile" SG_ 696 RedGladHand_CRC_ISig_5 "P01";
BA_ "GenSigCycleTime" SG_ 696 TrailerStatus_IntegrityLvl_ISig_ 100;
BA_ "GenSigCycleTimeActive" SG_ 696 TrailerStatus_IntegrityLvl_ISig_ 100;
BA_ "GenSigStartValue" SG_ 696 TrailerStatus_IntegrityLvl_ISig_ 3;
BA_ "GenSigMaxLatency" SG_ 696 TrailerStatus_IntegrityLvl_ISig_ 110;
BA_ "SystemSignalLongSymbol" SG_ 696 TrailerStatus_IntegrityLvl_ISig_ "TrailerStatus_IntegrityLvl_ISig_5";
BA_ "GenSigCycleTime" SG_ 696 TrailerStatus_CRC_ISig_5 100;
BA_ "GenSigCycleTimeActive" SG_ 696 TrailerStatus_CRC_ISig_5 100;
BA_ "GenSigStartValue" SG_ 696 TrailerStatus_CRC_ISig_5 255;
BA_ "GenSigMaxLatency" SG_ 696 TrailerStatus_CRC_ISig_5 110;
BA_ "E2EDataId" SG_ 696 TrailerStatus_CRC_ISig_5 116;
BA_ "E2EDataLength" SG_ 696 TrailerStatus_CRC_ISig_5 24;
BA_ "E2EProfile" SG_ 696 TrailerStatus_CRC_ISig_5 "P01";
BA_ "GenSigCycleTime" SG_ 696 RedGladHand_ConfidenceLvl_ISig_5 100;
BA_ "GenSigCycleTimeActive" SG_ 696 RedGladHand_ConfidenceLvl_ISig_5 100;
BA_ "GenSigStartValue" SG_ 696 RedGladHand_ConfidenceLvl_ISig_5 3;
BA_ "GenSigMaxLatency" SG_ 696 RedGladHand_ConfidenceLvl_ISig_5 110;
BA_ "GenSigCycleTime" SG_ 696 TrailerStatus_SqC_ISig_5 100;
BA_ "GenSigCycleTimeActive" SG_ 696 TrailerStatus_SqC_ISig_5 100;
BA_ "GenSigStartValue" SG_ 696 TrailerStatus_SqC_ISig_5 14;
BA_ "GenSigMaxLatency" SG_ 696 TrailerStatus_SqC_ISig_5 110;
BA_ "GenSigCycleTime" SG_ 696 TrailerStatus_Actuation_ISig_5 100;
BA_ "GenSigCycleTimeActive" SG_ 696 TrailerStatus_Actuation_ISig_5 100;
BA_ "GenSigStartValue" SG_ 696 TrailerStatus_Actuation_ISig_5 7;
BA_ "GenSigMaxLatency" SG_ 696 TrailerStatus_Actuation_ISig_5 110;
BA_ "GenSigCycleTime" SG_ 696 RedGladHand_ConnectStatus_ISig_5 100;
BA_ "GenSigCycleTimeActive" SG_ 696 RedGladHand_ConnectStatus_ISig_5 100;
BA_ "GenSigStartValue" SG_ 696 RedGladHand_ConnectStatus_ISig_5 3;
BA_ "GenSigMaxLatency" SG_ 696 RedGladHand_ConnectStatus_ISig_5 110;
BA_ "GenSigCycleTime" SG_ 695 TrafficSitPathEvent2_Type 100;
BA_ "GenSigCycleTimeActive" SG_ 695 TrafficSitPathEvent2_Type 100;
BA_ "GenSigStartValue" SG_ 695 TrafficSitPathEvent2_Type 255;
BA_ "GenSigMaxLatency" SG_ 695 TrafficSitPathEvent2_Type 105;
BA_ "GenSigCycleTime" SG_ 695 TrafficSitPathEvent1_Distance 100;
BA_ "GenSigCycleTimeActive" SG_ 695 TrafficSitPathEvent1_Distance 100;
BA_ "GenSigStartValue" SG_ 695 TrafficSitPathEvent1_Distance 16383;
BA_ "GenSigMaxLatency" SG_ 695 TrafficSitPathEvent1_Distance 105;
BA_ "GenSigCycleTime" SG_ 695 TrafficSitPathEvent1_Speed 100;
BA_ "GenSigCycleTimeActive" SG_ 695 TrafficSitPathEvent1_Speed 100;
BA_ "GenSigStartValue" SG_ 695 TrafficSitPathEvent1_Speed 1023;
BA_ "GenSigMaxLatency" SG_ 695 TrafficSitPathEvent1_Speed 105;
BA_ "GenSigCycleTime" SG_ 695 TrafficSitPathEvent2_Speed 100;
BA_ "GenSigCycleTimeActive" SG_ 695 TrafficSitPathEvent2_Speed 100;
BA_ "GenSigStartValue" SG_ 695 TrafficSitPathEvent2_Speed 1023;
BA_ "GenSigMaxLatency" SG_ 695 TrafficSitPathEvent2_Speed 105;
BA_ "GenSigCycleTime" SG_ 695 TrafficSitPathEvent1_Type 100;
BA_ "GenSigCycleTimeActive" SG_ 695 TrafficSitPathEvent1_Type 100;
BA_ "GenSigStartValue" SG_ 695 TrafficSitPathEvent1_Type 255;
BA_ "GenSigMaxLatency" SG_ 695 TrafficSitPathEvent1_Type 105;
BA_ "GenSigCycleTime" SG_ 695 TrafficSitPathEvent2_Distance 100;
BA_ "GenSigCycleTimeActive" SG_ 695 TrafficSitPathEvent2_Distance 100;
BA_ "GenSigStartValue" SG_ 695 TrafficSitPathEvent2_Distance 16383;
BA_ "GenSigMaxLatency" SG_ 695 TrafficSitPathEvent2_Distance 105;
BA_ "GenSigCycleTime" SG_ 694 BatteryCapacity_ISig_5 100;
BA_ "GenSigCycleTimeActive" SG_ 694 BatteryCapacity_ISig_5 100;
BA_ "GenSigStartValue" SG_ 694 BatteryCapacity_ISig_5 15;
BA_ "GenSigMaxLatency" SG_ 694 BatteryCapacity_ISig_5 100;
BA_ "GenSigCycleTime" SG_ 694 LivBatteryCharging_stat_ISig_5 100;
BA_ "GenSigCycleTimeActive" SG_ 694 LivBatteryCharging_stat_ISig_5 100;
BA_ "GenSigStartValue" SG_ 694 LivBatteryCharging_stat_ISig_5 3;
BA_ "GenSigMaxLatency" SG_ 694 LivBatteryCharging_stat_ISig_5 100;
BA_ "GenSigCycleTime" SG_ 694 BatteryCurrent_ISig_5 100;
BA_ "GenSigCycleTimeActive" SG_ 694 BatteryCurrent_ISig_5 100;
BA_ "GenSigStartValue" SG_ 694 BatteryCurrent_ISig_5 65535;
BA_ "GenSigMaxLatency" SG_ 694 BatteryCurrent_ISig_5 100;
BA_ "GenSigCycleTime" SG_ 694 AmbientLight_stat_ISig_5 100;
BA_ "GenSigCycleTimeActive" SG_ 694 AmbientLight_stat_ISig_5 100;
BA_ "GenSigStartValue" SG_ 694 AmbientLight_stat_ISig_5 65535;
BA_ "GenSigMaxLatency" SG_ 694 AmbientLight_stat_ISig_5 100;
BA_ "GenSigCycleTime" SG_ 693 TransmissionRangeSelected_ISig_5 100;
BA_ "GenSigCycleTimeActive" SG_ 693 TransmissionRangeSelected_ISig_5 100;
BA_ "GenSigMaxLatency" SG_ 693 TransmissionRangeSelected_ISig_5 100;
BA_ "GenSigCycleTime" SG_ 693 TransmissionRangeAttained_ISig_5 100;
BA_ "GenSigCycleTimeActive" SG_ 693 TransmissionRangeAttained_ISig_5 100;
BA_ "GenSigMaxLatency" SG_ 693 TransmissionRangeAttained_ISig_5 100;
BA_ "GenSigCycleTime" SG_ 693 FrontRoadWheelAngleEstimate1 100;
BA_ "GenSigCycleTimeActive" SG_ 693 FrontRoadWheelAngleEstimate1 100;
BA_ "GenSigStartValue" SG_ 693 FrontRoadWheelAngleEstimate1 65535;
BA_ "GenSigMaxLatency" SG_ 693 FrontRoadWheelAngleEstimate1 100;
BA_ "GenSigCycleTime" SG_ 693 WheelBasedVehicleSpeed_ISig_5 100;
BA_ "GenSigCycleTimeActive" SG_ 693 WheelBasedVehicleSpeed_ISig_5 100;
BA_ "GenSigStartValue" SG_ 693 WheelBasedVehicleSpeed_ISig_5 65535;
BA_ "GenSigMaxLatency" SG_ 693 WheelBasedVehicleSpeed_ISig_5 100;
BA_ "GenSigCycleTime" SG_ 692 BatterySOCactCriticalAlert_ISig_ 100;
BA_ "GenSigCycleTimeActive" SG_ 692 BatterySOCactCriticalAlert_ISig_ 100;
BA_ "GenSigStartValue" SG_ 692 BatterySOCactCriticalAlert_ISig_ 255;
BA_ "GenSigMaxLatency" SG_ 692 BatterySOCactCriticalAlert_ISig_ 100;
BA_ "SystemSignalLongSymbol" SG_ 692 BatterySOCactCriticalAlert_ISig_ "BatterySOCactCriticalAlert_ISig_5";
BA_ "GenSigCycleTime" SG_ 692 BatterySOCTrustLevel_ISig_5 100;
BA_ "GenSigCycleTimeActive" SG_ 692 BatterySOCTrustLevel_ISig_5 100;
BA_ "GenSigStartValue" SG_ 692 BatterySOCTrustLevel_ISig_5 255;
BA_ "GenSigMaxLatency" SG_ 692 BatterySOCTrustLevel_ISig_5 100;
BA_ "GenSigCycleTime" SG_ 692 BatterySOCnom_ISig_5 100;
BA_ "GenSigCycleTimeActive" SG_ 692 BatterySOCnom_ISig_5 100;
BA_ "GenSigStartValue" SG_ 692 BatterySOCnom_ISig_5 255;
BA_ "GenSigMaxLatency" SG_ 692 BatterySOCnom_ISig_5 100;
BA_ "GenSigCycleTime" SG_ 692 BatteryTemp_ISig_5 100;
BA_ "GenSigCycleTimeActive" SG_ 692 BatteryTemp_ISig_5 100;
BA_ "GenSigStartValue" SG_ 692 BatteryTemp_ISig_5 255;
BA_ "GenSigMaxLatency" SG_ 692 BatteryTemp_ISig_5 100;
BA_ "GenSigCycleTime" SG_ 692 BatteryVoltageDisplayValue_ISig_ 100;
BA_ "GenSigCycleTimeActive" SG_ 692 BatteryVoltageDisplayValue_ISig_ 100;
BA_ "GenSigStartValue" SG_ 692 BatteryVoltageDisplayValue_ISig_ 65535;
BA_ "GenSigMaxLatency" SG_ 692 BatteryVoltageDisplayValue_ISig_ 100;
BA_ "SystemSignalLongSymbol" SG_ 692 BatteryVoltageDisplayValue_ISig_ "BatteryVoltageDisplayValue_ISig_5";
BA_ "GenSigCycleTime" SG_ 692 BatterySOCact_ISig_5 100;
BA_ "GenSigCycleTimeActive" SG_ 692 BatterySOCact_ISig_5 100;
BA_ "GenSigStartValue" SG_ 692 BatterySOCact_ISig_5 255;
BA_ "GenSigMaxLatency" SG_ 692 BatterySOCact_ISig_5 100;
BA_ "GenSigCycleTime" SG_ 692 BatterySOH_ISig_5 100;
BA_ "GenSigCycleTimeActive" SG_ 692 BatterySOH_ISig_5 100;
BA_ "GenSigStartValue" SG_ 692 BatterySOH_ISig_5 255;
BA_ "GenSigMaxLatency" SG_ 692 BatterySOH_ISig_5 100;
BA_ "GenSigCycleTime" SG_ 691 AvailableGearsWithHigherRatio_IS 100;
BA_ "GenSigCycleTimeActive" SG_ 691 AvailableGearsWithHigherRatio_IS 100;
BA_ "GenSigStartValue" SG_ 691 AvailableGearsWithHigherRatio_IS 15;
BA_ "GenSigMaxLatency" SG_ 691 AvailableGearsWithHigherRatio_IS 100;
BA_ "SystemSignalLongSymbol" SG_ 691 AvailableGearsWithHigherRatio_IS "AvailableGearsWithHigherRatio_ISig_5";
BA_ "GenSigCycleTime" SG_ 691 EngineFuelRate_ISig_5 100;
BA_ "GenSigCycleTimeActive" SG_ 691 EngineFuelRate_ISig_5 100;
BA_ "GenSigStartValue" SG_ 691 EngineFuelRate_ISig_5 65535;
BA_ "GenSigMaxLatency" SG_ 691 EngineFuelRate_ISig_5 100;
BA_ "GenSigCycleTime" SG_ 691 DirectionIndicatorLightsStatus_I 100;
BA_ "GenSigCycleTimeActive" SG_ 691 DirectionIndicatorLightsStatus_I 100;
BA_ "GenSigStartValue" SG_ 691 DirectionIndicatorLightsStatus_I 15;
BA_ "GenSigMaxLatency" SG_ 691 DirectionIndicatorLightsStatus_I 100;
BA_ "SystemSignalLongSymbol" SG_ 691 DirectionIndicatorLightsStatus_I "DirectionIndicatorLightsStatus_ISig_5";
BA_ "GenSigCycleTime" SG_ 691 ActualEngineRetarderPercentTrq_I 100;
BA_ "GenSigCycleTimeActive" SG_ 691 ActualEngineRetarderPercentTrq_I 100;
BA_ "GenSigStartValue" SG_ 691 ActualEngineRetarderPercentTrq_I 255;
BA_ "GenSigMaxLatency" SG_ 691 ActualEngineRetarderPercentTrq_I 100;
BA_ "SystemSignalLongSymbol" SG_ 691 ActualEngineRetarderPercentTrq_I "ActualEngineRetarderPercentTrq_ISig_5";
BA_ "GenSigCycleTime" SG_ 691 ACC_SGO_Status_ISig_5 100;
BA_ "GenSigCycleTimeActive" SG_ 691 ACC_SGO_Status_ISig_5 100;
BA_ "GenSigStartValue" SG_ 691 ACC_SGO_Status_ISig_5 15;
BA_ "GenSigMaxLatency" SG_ 691 ACC_SGO_Status_ISig_5 100;
BA_ "GenSigCycleTime" SG_ 691 BatteryEndOfChargeLSB_ISig_5 100;
BA_ "GenSigCycleTimeActive" SG_ 691 BatteryEndOfChargeLSB_ISig_5 100;
BA_ "GenSigStartValue" SG_ 691 BatteryEndOfChargeLSB_ISig_5 3;
BA_ "GenSigCycleTime" SG_ 691 PV_HeadLightLevel 100;
BA_ "GenSigCycleTimeActive" SG_ 691 PV_HeadLightLevel 100;
BA_ "GenSigStartValue" SG_ 691 PV_HeadLightLevel 15;
BA_ "GenSigMaxLatency" SG_ 691 PV_HeadLightLevel 100;
BA_ "GenSigCycleTime" SG_ 691 BatteryEndOfChargeHSB_ISig_5 100;
BA_ "GenSigCycleTimeActive" SG_ 691 BatteryEndOfChargeHSB_ISig_5 100;
BA_ "GenSigStartValue" SG_ 691 BatteryEndOfChargeHSB_ISig_5 3;
BA_ "GenSigCycleTime" SG_ 691 SensorCleaningFluidLevelStatus_I 100;
BA_ "GenSigCycleTimeActive" SG_ 691 SensorCleaningFluidLevelStatus_I 100;
BA_ "GenSigStartValue" SG_ 691 SensorCleaningFluidLevelStatus_I 7;
BA_ "SystemSignalLongSymbol" SG_ 691 SensorCleaningFluidLevelStatus_I "SensorCleaningFluidLevelStatus_ISig_5";
BA_ "GenSigCycleTime" SG_ 691 ActualDrvlnRetdrPercentTorque_IS 100;
BA_ "GenSigCycleTimeActive" SG_ 691 ActualDrvlnRetdrPercentTorque_IS 100;
BA_ "GenSigStartValue" SG_ 691 ActualDrvlnRetdrPercentTorque_IS 255;
BA_ "GenSigMaxLatency" SG_ 691 ActualDrvlnRetdrPercentTorque_IS 100;
BA_ "SystemSignalLongSymbol" SG_ 691 ActualDrvlnRetdrPercentTorque_IS "ActualDrvlnRetdrPercentTorque_ISig_5";
BA_ "GenSigCycleTime" SG_ 691 AvailableGearsWithLowerRatio_ISi 100;
BA_ "GenSigCycleTimeActive" SG_ 691 AvailableGearsWithLowerRatio_ISi 100;
BA_ "GenSigStartValue" SG_ 691 AvailableGearsWithLowerRatio_ISi 15;
BA_ "GenSigMaxLatency" SG_ 691 AvailableGearsWithLowerRatio_ISi 100;
BA_ "SystemSignalLongSymbol" SG_ 691 AvailableGearsWithLowerRatio_ISi "AvailableGearsWithLowerRatio_ISig_5";
BA_ "GenSigCycleTime" SG_ 690 SetHSAOperation_ISig_5 100;
BA_ "GenSigCycleTimeActive" SG_ 690 SetHSAOperation_ISig_5 100;
BA_ "GenSigStartValue" SG_ 690 SetHSAOperation_ISig_5 7;
BA_ "GenSigMaxLatency" SG_ 690 SetHSAOperation_ISig_5 100;
BA_ "GenSigCycleTime" SG_ 690 PS_FogLightFront 100;
BA_ "GenSigCycleTimeActive" SG_ 690 PS_FogLightFront 100;
BA_ "GenSigStartValue" SG_ 690 PS_FogLightFront 3;
BA_ "GenSigMaxLatency" SG_ 690 PS_FogLightFront 100;
BA_ "GenSigCycleTime" SG_ 690 CACCStatus_ISig_5 100;
BA_ "GenSigCycleTimeActive" SG_ 690 CACCStatus_ISig_5 100;
BA_ "GenSigStartValue" SG_ 690 CACCStatus_ISig_5 7;
BA_ "GenSigMaxLatency" SG_ 690 CACCStatus_ISig_5 100;
BA_ "GenSigCycleTime" SG_ 690 Cab12VSupplyStatus_ISig_5 100;
BA_ "GenSigCycleTimeActive" SG_ 690 Cab12VSupplyStatus_ISig_5 100;
BA_ "GenSigStartValue" SG_ 690 Cab12VSupplyStatus_ISig_5 3;
BA_ "GenSigMaxLatency" SG_ 690 Cab12VSupplyStatus_ISig_5 100;
BA_ "GenSigCycleTime" SG_ 690 TransmissionDrivingMode_ISig_5 100;
BA_ "GenSigCycleTimeActive" SG_ 690 TransmissionDrivingMode_ISig_5 100;
BA_ "GenSigStartValue" SG_ 690 TransmissionDrivingMode_ISig_5 7;
BA_ "GenSigMaxLatency" SG_ 690 TransmissionDrivingMode_ISig_5 100;
BA_ "GenSigCycleTime" SG_ 690 LowAirPressureAlert_ISig_5 100;
BA_ "GenSigCycleTimeActive" SG_ 690 LowAirPressureAlert_ISig_5 100;
BA_ "GenSigStartValue" SG_ 690 LowAirPressureAlert_ISig_5 3;
BA_ "GenSigMaxLatency" SG_ 690 LowAirPressureAlert_ISig_5 100;
BA_ "GenSigCycleTime" SG_ 690 TemporaryRSLSwitchStatus 100;
BA_ "GenSigCycleTimeActive" SG_ 690 TemporaryRSLSwitchStatus 100;
BA_ "GenSigStartValue" SG_ 690 TemporaryRSLSwitchStatus 3;
BA_ "GenSigMaxLatency" SG_ 690 TemporaryRSLSwitchStatus 100;
BA_ "GenSigCycleTime" SG_ 690 BatterySOCAlertRawData_rqst_ISig 100;
BA_ "GenSigCycleTimeActive" SG_ 690 BatterySOCAlertRawData_rqst_ISig 100;
BA_ "GenSigStartValue" SG_ 690 BatterySOCAlertRawData_rqst_ISig 7;
BA_ "GenSigMaxLatency" SG_ 690 BatterySOCAlertRawData_rqst_ISig 100;
BA_ "SystemSignalLongSymbol" SG_ 690 BatterySOCAlertRawData_rqst_ISig "BatterySOCAlertRawData_rqst_ISig_5";
BA_ "GenSigCycleTime" SG_ 690 BatteryTempAlertRawData_rqst_ISi 100;
BA_ "GenSigCycleTimeActive" SG_ 690 BatteryTempAlertRawData_rqst_ISi 100;
BA_ "GenSigStartValue" SG_ 690 BatteryTempAlertRawData_rqst_ISi 7;
BA_ "GenSigMaxLatency" SG_ 690 BatteryTempAlertRawData_rqst_ISi 100;
BA_ "SystemSignalLongSymbol" SG_ 690 BatteryTempAlertRawData_rqst_ISi "BatteryTempAlertRawData_rqst_ISig_5";
BA_ "GenSigCycleTime" SG_ 690 BrakeTemperatureWarning_ISig_5 100;
BA_ "GenSigCycleTimeActive" SG_ 690 BrakeTemperatureWarning_ISig_5 100;
BA_ "GenSigStartValue" SG_ 690 BrakeTemperatureWarning_ISig_5 3;
BA_ "GenSigMaxLatency" SG_ 690 BrakeTemperatureWarning_ISig_5 100;
BA_ "GenSigCycleTime" SG_ 690 WheelSlipControllerMode_ISig_5 100;
BA_ "GenSigCycleTimeActive" SG_ 690 WheelSlipControllerMode_ISig_5 100;
BA_ "GenSigStartValue" SG_ 690 WheelSlipControllerMode_ISig_5 7;
BA_ "GenSigMaxLatency" SG_ 690 WheelSlipControllerMode_ISig_5 100;
BA_ "GenSigCycleTime" SG_ 690 Rainsensor_Indication_ISig_5 100;
BA_ "GenSigCycleTimeActive" SG_ 690 Rainsensor_Indication_ISig_5 100;
BA_ "GenSigStartValue" SG_ 690 Rainsensor_Indication_ISig_5 3;
BA_ "GenSigMaxLatency" SG_ 690 Rainsensor_Indication_ISig_5 100;
BA_ "GenSigCycleTime" SG_ 690 ESCHealthStatus_ISig_5 100;
BA_ "GenSigCycleTimeActive" SG_ 690 ESCHealthStatus_ISig_5 100;
BA_ "GenSigStartValue" SG_ 690 ESCHealthStatus_ISig_5 3;
BA_ "GenSigMaxLatency" SG_ 690 ESCHealthStatus_ISig_5 100;
BA_ "GenSigCycleTime" SG_ 690 TLInflationAcceptance_stat_ISig_ 100;
BA_ "GenSigCycleTimeActive" SG_ 690 TLInflationAcceptance_stat_ISig_ 100;
BA_ "GenSigStartValue" SG_ 690 TLInflationAcceptance_stat_ISig_ 7;
BA_ "GenSigMaxLatency" SG_ 690 TLInflationAcceptance_stat_ISig_ 100;
BA_ "SystemSignalLongSymbol" SG_ 690 TLInflationAcceptance_stat_ISig_ "TLInflationAcceptance_stat_ISig_5";
BA_ "GenSigCycleTime" SG_ 690 AutoLoadCutOffState_ISig_5 100;
BA_ "GenSigCycleTimeActive" SG_ 690 AutoLoadCutOffState_ISig_5 100;
BA_ "GenSigStartValue" SG_ 690 AutoLoadCutOffState_ISig_5 7;
BA_ "GenSigMaxLatency" SG_ 690 AutoLoadCutOffState_ISig_5 100;
BA_ "GenSigCycleTime" SG_ 690 TransmissionOilTempHigh_ISig_5 100;
BA_ "GenSigCycleTimeActive" SG_ 690 TransmissionOilTempHigh_ISig_5 100;
BA_ "GenSigStartValue" SG_ 690 TransmissionOilTempHigh_ISig_5 7;
BA_ "GenSigMaxLatency" SG_ 690 TransmissionOilTempHigh_ISig_5 100;
BA_ "GenSigCycleTime" SG_ 690 ECSLimpHomeNotification_ISig_5 100;
BA_ "GenSigCycleTimeActive" SG_ 690 ECSLimpHomeNotification_ISig_5 100;
BA_ "GenSigStartValue" SG_ 690 ECSLimpHomeNotification_ISig_5 7;
BA_ "GenSigMaxLatency" SG_ 690 ECSLimpHomeNotification_ISig_5 100;
BA_ "GenSigCycleTime" SG_ 690 EqualizerUnbalance_ISig_5 100;
BA_ "GenSigCycleTimeActive" SG_ 690 EqualizerUnbalance_ISig_5 100;
BA_ "GenSigStartValue" SG_ 690 EqualizerUnbalance_ISig_5 7;
BA_ "GenSigMaxLatency" SG_ 690 EqualizerUnbalance_ISig_5 100;
BA_ "GenSigCycleTime" SG_ 690 AutGearSplitPosition_ISig_5 100;
BA_ "GenSigCycleTimeActive" SG_ 690 AutGearSplitPosition_ISig_5 100;
BA_ "GenSigStartValue" SG_ 690 AutGearSplitPosition_ISig_5 7;
BA_ "GenSigMaxLatency" SG_ 690 AutGearSplitPosition_ISig_5 100;
BA_ "GenSigCycleTime" SG_ 690 BatterySOCAlert_rqst_ISig_5 100;
BA_ "GenSigCycleTimeActive" SG_ 690 BatterySOCAlert_rqst_ISig_5 100;
BA_ "GenSigStartValue" SG_ 690 BatterySOCAlert_rqst_ISig_5 7;
BA_ "GenSigMaxLatency" SG_ 690 BatterySOCAlert_rqst_ISig_5 100;
BA_ "GenSigCycleTime" SG_ 690 DriveModeSwitchUserOverride_ISig 100;
BA_ "GenSigCycleTimeActive" SG_ 690 DriveModeSwitchUserOverride_ISig 100;
BA_ "GenSigStartValue" SG_ 690 DriveModeSwitchUserOverride_ISig 7;
BA_ "GenSigMaxLatency" SG_ 690 DriveModeSwitchUserOverride_ISig 100;
BA_ "SystemSignalLongSymbol" SG_ 690 DriveModeSwitchUserOverride_ISig "DriveModeSwitchUserOverride_ISig_5";
BA_ "GenSigCycleTime" SG_ 690 BatteryTempAlert_rqst_ISig_5 100;
BA_ "GenSigCycleTimeActive" SG_ 690 BatteryTempAlert_rqst_ISig_5 100;
BA_ "GenSigStartValue" SG_ 690 BatteryTempAlert_rqst_ISig_5 7;
BA_ "GenSigMaxLatency" SG_ 690 BatteryTempAlert_rqst_ISig_5 100;
BA_ "GenSigCycleTime" SG_ 690 TrailerEBSFault_ISig_5 100;
BA_ "GenSigCycleTimeActive" SG_ 690 TrailerEBSFault_ISig_5 100;
BA_ "GenSigStartValue" SG_ 690 TrailerEBSFault_ISig_5 3;
BA_ "GenSigMaxLatency" SG_ 690 TrailerEBSFault_ISig_5 100;
BA_REL_ "GenSigFirstTimeoutTime" BU_SG_REL_ IC SG_ 1204 TimeLeftToTorqueReductionFuel_IS 24000;
BA_REL_ "GenSigTimeoutTime" BU_SG_REL_ IC SG_ 1204 TimeLeftToTorqueReductionFuel_IS 6000;
BA_REL_ "GenSigFirstTimeoutTime" BU_SG_REL_ IC SG_ 1204 TimeLeftToVehSpdReductionFuel_IS 24000;
BA_REL_ "GenSigTimeoutTime" BU_SG_REL_ IC SG_ 1204 TimeLeftToVehSpdReductionFuel_IS 6000;
BA_REL_ "GenSigFirstTimeoutTime" BU_SG_REL_ IC SG_ 1204 TransmissionOilLevel_ISig_5 24000;
BA_REL_ "GenSigTimeoutTime" BU_SG_REL_ IC SG_ 1204 TransmissionOilLevel_ISig_5 6000;
BA_REL_ "GenSigFirstTimeoutTime" BU_SG_REL_ IC SG_ 1204 TimeLeftToTorqueReduction_OBD_IS 24000;
BA_REL_ "GenSigTimeoutTime" BU_SG_REL_ IC SG_ 1204 TimeLeftToTorqueReduction_OBD_IS 6000;
BA_REL_ "GenSigFirstTimeoutTime" BU_SG_REL_ IC SG_ 1204 TimetoCompleteParkRegen_ISig_5 24000;
BA_REL_ "GenSigTimeoutTime" BU_SG_REL_ IC SG_ 1204 TimetoCompleteParkRegen_ISig_5 6000;
BA_REL_ "GenSigFirstTimeoutTime" BU_SG_REL_ IC SG_ 1204 TimeLeftToVehSpdReduction_OBD_IS 24000;
BA_REL_ "GenSigTimeoutTime" BU_SG_REL_ IC SG_ 1204 TimeLeftToVehSpdReduction_OBD_IS 6000;
BA_REL_ "GenSigFirstTimeoutTime" BU_SG_REL_ IC SG_ 1203 AdBlueTankTemperature_ISig_5 24000;
BA_REL_ "GenSigTimeoutTime" BU_SG_REL_ IC SG_ 1203 AdBlueTankTemperature_ISig_5 6000;
BA_REL_ "GenSigFirstTimeoutTime" BU_SG_REL_ IC SG_ 1203 RearDriveAxle2Temperature_ISig_5 24000;
BA_REL_ "GenSigTimeoutTime" BU_SG_REL_ IC SG_ 1203 RearDriveAxle2Temperature_ISig_5 6000;
BA_REL_ "GenSigFirstTimeoutTime" BU_SG_REL_ IC SG_ 1203 DistLeftToSevereInducement_OBD_I 24000;
BA_REL_ "GenSigTimeoutTime" BU_SG_REL_ IC SG_ 1203 DistLeftToSevereInducement_OBD_I 6000;
BA_REL_ "GenSigFirstTimeoutTime" BU_SG_REL_ IC SG_ 1203 RearDriveAxle3Temperature_ISig_5 24000;
BA_REL_ "GenSigTimeoutTime" BU_SG_REL_ IC SG_ 1203 RearDriveAxle3Temperature_ISig_5 6000;
BA_REL_ "GenSigFirstTimeoutTime" BU_SG_REL_ IC SG_ 1203 RearDriveAxle1Temperature_ISig_5 24000;
BA_REL_ "GenSigTimeoutTime" BU_SG_REL_ IC SG_ 1203 RearDriveAxle1Temperature_ISig_5 6000;
BA_REL_ "GenSigFirstTimeoutTime" BU_SG_REL_ CCM SG_ 1203 AmbientAirTemperature_ISig_5 24000;
BA_REL_ "GenSigTimeoutTime" BU_SG_REL_ CCM SG_ 1203 AmbientAirTemperature_ISig_5 6000;
BA_REL_ "GenSigFirstTimeoutTime" BU_SG_REL_ IC SG_ 1203 AmbientAirTemperature_ISig_5 24000;
BA_REL_ "GenSigTimeoutTime" BU_SG_REL_ IC SG_ 1203 AmbientAirTemperature_ISig_5 6000;
BA_REL_ "GenSigFirstTimeoutTime" BU_SG_REL_ CCM SG_ 1203 EngineCoolantTemp_stat_ISig_5 24000;
BA_REL_ "GenSigTimeoutTime" BU_SG_REL_ CCM SG_ 1203 EngineCoolantTemp_stat_ISig_5 6000;
BA_REL_ "GenSigFirstTimeoutTime" BU_SG_REL_ IC SG_ 1202 FasUsrDefinedDampingSetting_ISig 24000;
BA_REL_ "GenSigTimeoutTime" BU_SG_REL_ IC SG_ 1202 FasUsrDefinedDampingSetting_ISig 6000;
BA_REL_ "GenSigFirstTimeoutTime" BU_SG_REL_ IC SG_ 1202 SCROperatorInducementSeverity_IS 24000;
BA_REL_ "GenSigTimeoutTime" BU_SG_REL_ IC SG_ 1202 SCROperatorInducementSeverity_IS 6000;
BA_REL_ "GenSigFirstTimeoutTime" BU_SG_REL_ IC SG_ 1202 CatalystTankLevelLow_ISig_5 24000;
BA_REL_ "GenSigTimeoutTime" BU_SG_REL_ IC SG_ 1202 CatalystTankLevelLow_ISig_5 6000;
BA_REL_ "GenSigFirstTimeoutTime" BU_SG_REL_ IC SG_ 1202 MIStatusExtEMS_ISig_5 24000;
BA_REL_ "GenSigTimeoutTime" BU_SG_REL_ IC SG_ 1202 MIStatusExtEMS_ISig_5 6000;
BA_REL_ "GenSigFirstTimeoutTime" BU_SG_REL_ IC SG_ 1202 FuelOperatorDeratingReason_ISig_ 24000;
BA_REL_ "GenSigTimeoutTime" BU_SG_REL_ IC SG_ 1202 FuelOperatorDeratingReason_ISig_ 6000;
BA_REL_ "GenSigFirstTimeoutTime" BU_SG_REL_ IC SG_ 1202 ActualFasPersSettingsButton_ISig 24000;
BA_REL_ "GenSigTimeoutTime" BU_SG_REL_ IC SG_ 1202 ActualFasPersSettingsButton_ISig 6000;
BA_REL_ "GenSigFirstTimeoutTime" BU_SG_REL_ IC SG_ 1202 BatteryEndOfCharge_ISig_5 24000;
BA_REL_ "GenSigTimeoutTime" BU_SG_REL_ IC SG_ 1202 BatteryEndOfCharge_ISig_5 6000;
BA_REL_ "GenSigFirstTimeoutTime" BU_SG_REL_ IC SG_ 1202 FasUsrDefStiffStraightSetting_IS 24000;
BA_REL_ "GenSigTimeoutTime" BU_SG_REL_ IC SG_ 1202 FasUsrDefStiffStraightSetting_IS 6000;
BA_REL_ "GenSigFirstTimeoutTime" BU_SG_REL_ IC SG_ 1202 LiningWearWarning_ISig_5 24000;
BA_REL_ "GenSigTimeoutTime" BU_SG_REL_ IC SG_ 1202 LiningWearWarning_ISig_5 6000;
BA_REL_ "GenSigFirstTimeoutTime" BU_SG_REL_ IC SG_ 1202 TorqueReductionStatus_OBD_ISig_5 24000;
BA_REL_ "GenSigTimeoutTime" BU_SG_REL_ IC SG_ 1202 TorqueReductionStatus_OBD_ISig_5 6000;
BA_REL_ "GenSigFirstTimeoutTime" BU_SG_REL_ IC SG_ 1202 LoadCalibrationFeedback_ISig_5 24000;
BA_REL_ "GenSigTimeoutTime" BU_SG_REL_ IC SG_ 1202 LoadCalibrationFeedback_ISig_5 6000;
BA_REL_ "GenSigFirstTimeoutTime" BU_SG_REL_ IC SG_ 1202 FasUsrDefLowSpeedReturnSetting_I 24000;
BA_REL_ "GenSigTimeoutTime" BU_SG_REL_ IC SG_ 1202 FasUsrDefLowSpeedReturnSetting_I 6000;
BA_REL_ "GenSigFirstTimeoutTime" BU_SG_REL_ IC SG_ 1202 FuelOperatorDeratingSeverity_ISi 24000;
BA_REL_ "GenSigTimeoutTime" BU_SG_REL_ IC SG_ 1202 FuelOperatorDeratingSeverity_ISi 6000;
BA_REL_ "GenSigFirstTimeoutTime" BU_SG_REL_ IC SG_ 1202 FasUsrDefStiffnessCurveSetting_I 24000;
BA_REL_ "GenSigTimeoutTime" BU_SG_REL_ IC SG_ 1202 FasUsrDefStiffnessCurveSetting_I 6000;
BA_REL_ "GenSigFirstTimeoutTime" BU_SG_REL_ IC SG_ 1202 SCROperatorInducementReason_ISig 24000;
BA_REL_ "GenSigTimeoutTime" BU_SG_REL_ IC SG_ 1202 SCROperatorInducementReason_ISig 6000;
BA_REL_ "GenSigFirstTimeoutTime" BU_SG_REL_ IC SG_ 1202 ActualFasManualOffsetSetting_ISi 24000;
BA_REL_ "GenSigTimeoutTime" BU_SG_REL_ IC SG_ 1202 ActualFasManualOffsetSetting_ISi 6000;
BA_REL_ "GenSigFirstTimeoutTime" BU_SG_REL_ IC SG_ 1202 MIDistinctWarningExtEMS_ISig_5 24000;
BA_REL_ "GenSigTimeoutTime" BU_SG_REL_ IC SG_ 1202 MIDistinctWarningExtEMS_ISig_5 6000;
BA_REL_ "GenSigFirstTimeoutTime" BU_SG_REL_ IC SG_ 1202 FasDriver_ISig_5 24000;
BA_REL_ "GenSigTimeoutTime" BU_SG_REL_ IC SG_ 1202 FasDriver_ISig_5 6000;
BA_REL_ "GenSigFirstTimeoutTime" BU_SG_REL_ IC SG_ 1202 MIDistinctWarning_ISig_5 24000;
BA_REL_ "GenSigTimeoutTime" BU_SG_REL_ IC SG_ 1202 MIDistinctWarning_ISig_5 6000;
BA_REL_ "GenSigFirstTimeoutTime" BU_SG_REL_ IC SG_ 1201 DiagFaultStat_BBIOM_DtcIdB 24000;
BA_REL_ "GenSigTimeoutTime" BU_SG_REL_ IC SG_ 1201 DiagFaultStat_BBIOM_DtcIdB 6000;
BA_REL_ "GenSigFirstTimeoutTime" BU_SG_REL_ IC SG_ 1201 DiagFaultStat_BBIOM_DtcIdA 24000;
BA_REL_ "GenSigTimeoutTime" BU_SG_REL_ IC SG_ 1201 DiagFaultStat_BBIOM_DtcIdA 6000;
BA_REL_ "GenSigFirstTimeoutTime" BU_SG_REL_ IC SG_ 1201 DiagFaultStat_BBIOM_FailTB 24000;
BA_REL_ "GenSigTimeoutTime" BU_SG_REL_ IC SG_ 1201 DiagFaultStat_BBIOM_FailTB 6000;
BA_REL_ "GenSigFirstTimeoutTime" BU_SG_REL_ IC SG_ 1201 DiagFaultStat_BBIOM_FailTA 24000;
BA_REL_ "GenSigTimeoutTime" BU_SG_REL_ IC SG_ 1201 DiagFaultStat_BBIOM_FailTA 6000;
BA_REL_ "GenSigFirstTimeoutTime" BU_SG_REL_ IC SG_ 1201 DiagFaultStat_BBIOM_EcuAdr 24000;
BA_REL_ "GenSigTimeoutTime" BU_SG_REL_ IC SG_ 1201 DiagFaultStat_BBIOM_EcuAdr 6000;
BA_REL_ "GenSigFirstTimeoutTime" BU_SG_REL_ IC SG_ 903 ManTransmiOilTemp_ISig_5 12000;
BA_REL_ "GenSigTimeoutTime" BU_SG_REL_ IC SG_ 903 ManTransmiOilTemp_ISig_5 3000;
BA_REL_ "GenSigFirstTimeoutTime" BU_SG_REL_ IC SG_ 903 EngineTurbo1BoostPressure_ISig_5 12000;
BA_REL_ "GenSigTimeoutTime" BU_SG_REL_ IC SG_ 903 EngineTurbo1BoostPressure_ISig_5 3000;
BA_REL_ "GenSigFirstTimeoutTime" BU_SG_REL_ IC SG_ 903 LastDriveAxleBellowPressure_ISig 12000;
BA_REL_ "GenSigTimeoutTime" BU_SG_REL_ IC SG_ 903 LastDriveAxleBellowPressure_ISig 3000;
BA_REL_ "GenSigFirstTimeoutTime" BU_SG_REL_ IC SG_ 902 Cur_LG5CutoffValue_ISig_5 12000;
BA_REL_ "GenSigTimeoutTime" BU_SG_REL_ IC SG_ 902 Cur_LG5CutoffValue_ISig_5 3000;
BA_REL_ "GenSigFirstTimeoutTime" BU_SG_REL_ IC SG_ 902 Cur_LG4CutoffValue_ISig_5 12000;
BA_REL_ "GenSigTimeoutTime" BU_SG_REL_ IC SG_ 902 Cur_LG4CutoffValue_ISig_5 3000;
BA_REL_ "GenSigFirstTimeoutTime" BU_SG_REL_ IC SG_ 902 Cur_LG1CutoffValue_ISig_5 12000;
BA_REL_ "GenSigTimeoutTime" BU_SG_REL_ IC SG_ 902 Cur_LG1CutoffValue_ISig_5 3000;
BA_REL_ "GenSigFirstTimeoutTime" BU_SG_REL_ IC SG_ 902 Cur_LG2CutoffValue_ISig_5 12000;
BA_REL_ "GenSigTimeoutTime" BU_SG_REL_ IC SG_ 902 Cur_LG2CutoffValue_ISig_5 3000;
BA_REL_ "GenSigFirstTimeoutTime" BU_SG_REL_ IC SG_ 902 Cur_EnergySetting_ISig_5 12000;
BA_REL_ "GenSigTimeoutTime" BU_SG_REL_ IC SG_ 902 Cur_EnergySetting_ISig_5 3000;
BA_REL_ "GenSigFirstTimeoutTime" BU_SG_REL_ IC SG_ 902 UltracapDisplay_Stat_ISig_5 12000;
BA_REL_ "GenSigTimeoutTime" BU_SG_REL_ IC SG_ 902 UltracapDisplay_Stat_ISig_5 3000;
BA_REL_ "GenSigFirstTimeoutTime" BU_SG_REL_ IC SG_ 902 Cur_LG6CutoffValue_ISig_5 12000;
BA_REL_ "GenSigTimeoutTime" BU_SG_REL_ IC SG_ 902 Cur_LG6CutoffValue_ISig_5 3000;
BA_REL_ "GenSigFirstTimeoutTime" BU_SG_REL_ IC SG_ 902 Cur_LG3CutoffValue_ISig_5 12000;
BA_REL_ "GenSigTimeoutTime" BU_SG_REL_ IC SG_ 902 Cur_LG3CutoffValue_ISig_5 3000;
BA_REL_ "GenSigFirstTimeoutTime" BU_SG_REL_ IC SG_ 902 Ultracap_Status_ISig_5 12000;
BA_REL_ "GenSigTimeoutTime" BU_SG_REL_ IC SG_ 902 Ultracap_Status_ISig_5 3000;
BA_REL_ "GenSigFirstTimeoutTime" BU_SG_REL_ IC SG_ 901 AxleLoadStatus_ISig_5 12000;
BA_REL_ "GenSigTimeoutTime" BU_SG_REL_ IC SG_ 901 AxleLoadStatus_ISig_5 3000;
BA_REL_ "GenSigFirstTimeoutTime" BU_SG_REL_ IC SG_ 901 ClutchAbuseStatus_ISig_5 12000;
BA_REL_ "GenSigTimeoutTime" BU_SG_REL_ IC SG_ 901 ClutchAbuseStatus_ISig_5 3000;
BA_REL_ "GenSigFirstTimeoutTime" BU_SG_REL_ IC SG_ 901 ISeeStatus_ISig_5 12000;
BA_REL_ "GenSigTimeoutTime" BU_SG_REL_ IC SG_ 901 ISeeStatus_ISig_5 3000;
BA_REL_ "GenSigFirstTimeoutTime" BU_SG_REL_ IC SG_ 901 TransmissionSplitboxPTOMode_ISig 12000;
BA_REL_ "GenSigTimeoutTime" BU_SG_REL_ IC SG_ 901 TransmissionSplitboxPTOMode_ISig 3000;
BA_REL_ "GenSigFirstTimeoutTime" BU_SG_REL_ IC SG_ 901 OilLevelDrvInstr_IncorrEngSpe_IS 12000;
BA_REL_ "GenSigTimeoutTime" BU_SG_REL_ IC SG_ 901 OilLevelDrvInstr_IncorrEngSpe_IS 3000;
BA_REL_ "GenSigFirstTimeoutTime" BU_SG_REL_ IC SG_ 901 OilLevelDrvInstr_ChangeGearTxt_I 12000;
BA_REL_ "GenSigTimeoutTime" BU_SG_REL_ IC SG_ 901 OilLevelDrvInstr_ChangeGearTxt_I 3000;
BA_REL_ "GenSigFirstTimeoutTime" BU_SG_REL_ IC SG_ 901 PredeliveryModeIndication_cmd_IS 12000;
BA_REL_ "GenSigTimeoutTime" BU_SG_REL_ IC SG_ 901 PredeliveryModeIndication_cmd_IS 3000;
BA_REL_ "GenSigFirstTimeoutTime" BU_SG_REL_ IC SG_ 901 OilLevelDrvInstr_Wait60SecTxt_IS 12000;
BA_REL_ "GenSigTimeoutTime" BU_SG_REL_ IC SG_ 901 OilLevelDrvInstr_Wait60SecTxt_IS 3000;
BA_REL_ "GenSigFirstTimeoutTime" BU_SG_REL_ IC SG_ 901 DPF_LimitedSpeedDuetoInhibit_ISi 12000;
BA_REL_ "GenSigTimeoutTime" BU_SG_REL_ IC SG_ 901 DPF_LimitedSpeedDuetoInhibit_ISi 3000;
BA_REL_ "GenSigFirstTimeoutTime" BU_SG_REL_ IC SG_ 901 DPF_ParkedRegenStatus_ISig_5 12000;
BA_REL_ "GenSigTimeoutTime" BU_SG_REL_ IC SG_ 901 DPF_ParkedRegenStatus_ISig_5 3000;
BA_REL_ "GenSigFirstTimeoutTime" BU_SG_REL_ IC SG_ 901 OilLevelDrvInstr_OilTempTxt_ISig 12000;
BA_REL_ "GenSigTimeoutTime" BU_SG_REL_ IC SG_ 901 OilLevelDrvInstr_OilTempTxt_ISig 3000;
BA_REL_ "GenSigFirstTimeoutTime" BU_SG_REL_ IC SG_ 901 OilLevelDrvInstr_StopVehicle_ISi 12000;
BA_REL_ "GenSigTimeoutTime" BU_SG_REL_ IC SG_ 901 OilLevelDrvInstr_StopVehicle_ISi 3000;
BA_REL_ "GenSigFirstTimeoutTime" BU_SG_REL_ IC SG_ 901 ClutchCalibration_stat_ISig_5 12000;
BA_REL_ "GenSigTimeoutTime" BU_SG_REL_ IC SG_ 901 ClutchCalibration_stat_ISig_5 3000;
BA_REL_ "GenSigFirstTimeoutTime" BU_SG_REL_ CCM SG_ 901 FuelVolume_ISig_5 12000;
BA_REL_ "GenSigTimeoutTime" BU_SG_REL_ CCM SG_ 901 FuelVolume_ISig_5 3000;
BA_REL_ "GenSigFirstTimeoutTime" BU_SG_REL_ IC SG_ 901 FuelVolume_ISig_5 12000;
BA_REL_ "GenSigTimeoutTime" BU_SG_REL_ IC SG_ 901 FuelVolume_ISig_5 3000;
BA_REL_ "GenSigFirstTimeoutTime" BU_SG_REL_ IC SG_ 901 OilLevelDrvInstr_NotHorizonTxt_I 12000;
BA_REL_ "GenSigTimeoutTime" BU_SG_REL_ IC SG_ 901 OilLevelDrvInstr_NotHorizonTxt_I 3000;
BA_REL_ "GenSigFirstTimeoutTime" BU_SG_REL_ IC SG_ 901 FuelLevel_ISig_5 12000;
BA_REL_ "GenSigTimeoutTime" BU_SG_REL_ IC SG_ 901 FuelLevel_ISig_5 3000;
BA_REL_ "GenSigFirstTimeoutTime" BU_SG_REL_ CCM SG_ 901 FuelLevel_ISig_5 12000;
BA_REL_ "GenSigTimeoutTime" BU_SG_REL_ CCM SG_ 901 FuelLevel_ISig_5 3000;
BA_REL_ "GenSigFirstTimeoutTime" BU_SG_REL_ IC SG_ 868 DrainPrimingStatus_ISig_5 6000;
BA_REL_ "GenSigTimeoutTime" BU_SG_REL_ IC SG_ 868 DrainPrimingStatus_ISig_5 1500;
BA_REL_ "GenSigFirstTimeoutTime" BU_SG_REL_ IC SG_ 868 FrontConspicLamp_stat_HiRight_IS 6000;
BA_REL_ "GenSigTimeoutTime" BU_SG_REL_ IC SG_ 868 FrontConspicLamp_stat_HiRight_IS 1500;
BA_REL_ "GenSigFirstTimeoutTime" BU_SG_REL_ IC SG_ 868 FrontConspicLamp_stat_LoRight_IS 6000;
BA_REL_ "GenSigTimeoutTime" BU_SG_REL_ IC SG_ 868 FrontConspicLamp_stat_LoRight_IS 1500;
BA_REL_ "GenSigFirstTimeoutTime" BU_SG_REL_ IC SG_ 868 CoolantTempHigh_ISig_5 6000;
BA_REL_ "GenSigTimeoutTime" BU_SG_REL_ IC SG_ 868 CoolantTempHigh_ISig_5 1500;
BA_REL_ "GenSigFirstTimeoutTime" BU_SG_REL_ IC SG_ 868 AutoWheelBrakesStatus_ISig_5 6000;
BA_REL_ "GenSigTimeoutTime" BU_SG_REL_ IC SG_ 868 AutoWheelBrakesStatus_ISig_5 1500;
BA_REL_ "GenSigFirstTimeoutTime" BU_SG_REL_ IC SG_ 868 OilLevelLow_ISig_5 6000;
BA_REL_ "GenSigTimeoutTime" BU_SG_REL_ IC SG_ 868 OilLevelLow_ISig_5 1500;
BA_REL_ "GenSigFirstTimeoutTime" BU_SG_REL_ IC SG_ 868 InletAirHeaterStatus1_ISig_5 6000;
BA_REL_ "GenSigTimeoutTime" BU_SG_REL_ IC SG_ 868 InletAirHeaterStatus1_ISig_5 1500;
BA_REL_ "GenSigFirstTimeoutTime" BU_SG_REL_ IC SG_ 868 DeicingFunction_Stat_ISig_5 6000;
BA_REL_ "GenSigTimeoutTime" BU_SG_REL_ IC SG_ 868 DeicingFunction_Stat_ISig_5 1500;
BA_REL_ "GenSigFirstTimeoutTime" BU_SG_REL_ IC SG_ 868 SelfStartAssist_stat_ISig_5 6000;
BA_REL_ "GenSigTimeoutTime" BU_SG_REL_ IC SG_ 868 SelfStartAssist_stat_ISig_5 1500;
BA_REL_ "GenSigFirstTimeoutTime" BU_SG_REL_ IC SG_ 868 TrailerDirIndLeftOutputStat_ISig 6000;
BA_REL_ "GenSigTimeoutTime" BU_SG_REL_ IC SG_ 868 TrailerDirIndLeftOutputStat_ISig 1500;
BA_REL_ "GenSigFirstTimeoutTime" BU_SG_REL_ IC SG_ 868 TrailerPosLightLeftOutputStat_IS 6000;
BA_REL_ "GenSigTimeoutTime" BU_SG_REL_ IC SG_ 868 TrailerPosLightLeftOutputStat_IS 1500;
BA_REL_ "GenSigFirstTimeoutTime" BU_SG_REL_ IC SG_ 868 TrailerBrakeLightOutputStat_ISig 6000;
BA_REL_ "GenSigTimeoutTime" BU_SG_REL_ IC SG_ 868 TrailerBrakeLightOutputStat_ISig 1500;
BA_REL_ "GenSigFirstTimeoutTime" BU_SG_REL_ IC SG_ 868 StartBatteryDisplay_stat_ISig_5 6000;
BA_REL_ "GenSigTimeoutTime" BU_SG_REL_ IC SG_ 868 StartBatteryDisplay_stat_ISig_5 1500;
BA_REL_ "GenSigFirstTimeoutTime" BU_SG_REL_ IC SG_ 868 DeicingBulb_Stat_ISig_5 6000;
BA_REL_ "GenSigTimeoutTime" BU_SG_REL_ IC SG_ 868 DeicingBulb_Stat_ISig_5 1500;
BA_REL_ "GenSigFirstTimeoutTime" BU_SG_REL_ IC SG_ 868 LivBatDisconnectDetectStat_ISig_ 6000;
BA_REL_ "GenSigTimeoutTime" BU_SG_REL_ IC SG_ 868 LivBatDisconnectDetectStat_ISig_ 1500;
BA_REL_ "GenSigFirstTimeoutTime" BU_SG_REL_ IC SG_ 868 FrontConspicLamp_stat_LoLeft_ISi 6000;
BA_REL_ "GenSigTimeoutTime" BU_SG_REL_ IC SG_ 868 FrontConspicLamp_stat_LoLeft_ISi 1500;
BA_REL_ "GenSigFirstTimeoutTime" BU_SG_REL_ IC SG_ 868 FuelFilterClogged_ISig_5 6000;
BA_REL_ "GenSigTimeoutTime" BU_SG_REL_ IC SG_ 868 FuelFilterClogged_ISig_5 1500;
BA_REL_ "GenSigFirstTimeoutTime" BU_SG_REL_ IC SG_ 868 EngineFanOverspeed_ISig_5 6000;
BA_REL_ "GenSigTimeoutTime" BU_SG_REL_ IC SG_ 868 EngineFanOverspeed_ISig_5 1500;
BA_REL_ "GenSigFirstTimeoutTime" BU_SG_REL_ IC SG_ 868 JumpChargeInterface_stat_ISig_5 6000;
BA_REL_ "GenSigTimeoutTime" BU_SG_REL_ IC SG_ 868 JumpChargeInterface_stat_ISig_5 1500;
BA_REL_ "GenSigFirstTimeoutTime" BU_SG_REL_ IC SG_ 868 OilPressureLow_ISig_5 6000;
BA_REL_ "GenSigTimeoutTime" BU_SG_REL_ IC SG_ 868 OilPressureLow_ISig_5 1500;
BA_REL_ "GenSigFirstTimeoutTime" BU_SG_REL_ IC SG_ 868 FrontConspicLamp_stat_HiLeft_ISi 6000;
BA_REL_ "GenSigTimeoutTime" BU_SG_REL_ IC SG_ 868 FrontConspicLamp_stat_HiLeft_ISi 1500;
BA_REL_ "GenSigFirstTimeoutTime" BU_SG_REL_ IC SG_ 868 GChargerStatus_ISig_5 6000;
BA_REL_ "GenSigTimeoutTime" BU_SG_REL_ IC SG_ 868 GChargerStatus_ISig_5 1500;
BA_REL_ "GenSigFirstTimeoutTime" BU_SG_REL_ IC SG_ 868 TrailerRevAndFogOutput_stat_ISig 6000;
BA_REL_ "GenSigTimeoutTime" BU_SG_REL_ IC SG_ 868 TrailerRevAndFogOutput_stat_ISig 1500;
BA_REL_ "GenSigFirstTimeoutTime" BU_SG_REL_ IC SG_ 867 DirIndSideLamp_stat 6000;
BA_REL_ "GenSigTimeoutTime" BU_SG_REL_ IC SG_ 867 DirIndSideLamp_stat 1500;
BA_REL_ "GenSigFirstTimeoutTime" BU_SG_REL_ IC SG_ 867 DirInd_Front_Status_ISig_5 6000;
BA_REL_ "GenSigTimeoutTime" BU_SG_REL_ IC SG_ 867 DirInd_Front_Status_ISig_5 1500;
BA_REL_ "GenSigFirstTimeoutTime" BU_SG_REL_ IC SG_ 867 FogLightFrontLamp_stat_ISig_5 6000;
BA_REL_ "GenSigTimeoutTime" BU_SG_REL_ IC SG_ 867 FogLightFrontLamp_stat_ISig_5 1500;
BA_REL_ "GenSigFirstTimeoutTime" BU_SG_REL_ IC SG_ 867 MainBeamLEDStatusRight_ISig_5 6000;
BA_REL_ "GenSigTimeoutTime" BU_SG_REL_ IC SG_ 867 MainBeamLEDStatusRight_ISig_5 1500;
BA_REL_ "GenSigFirstTimeoutTime" BU_SG_REL_ IC SG_ 867 RevLightLamp_stat_ISig_5 6000;
BA_REL_ "GenSigTimeoutTime" BU_SG_REL_ IC SG_ 867 RevLightLamp_stat_ISig_5 1500;
BA_REL_ "GenSigFirstTimeoutTime" BU_SG_REL_ IC SG_ 867 ExtraMainBeamLamp_stat_ISig_5 6000;
BA_REL_ "GenSigTimeoutTime" BU_SG_REL_ IC SG_ 867 ExtraMainBeamLamp_stat_ISig_5 1500;
BA_REL_ "GenSigFirstTimeoutTime" BU_SG_REL_ IC SG_ 867 MainBeamLEDStatusLeft_ISig_5 6000;
BA_REL_ "GenSigTimeoutTime" BU_SG_REL_ IC SG_ 867 MainBeamLEDStatusLeft_ISig_5 1500;
BA_REL_ "GenSigFirstTimeoutTime" BU_SG_REL_ IC SG_ 867 PositionLightRearLamp_stat_ISig_ 6000;
BA_REL_ "GenSigTimeoutTime" BU_SG_REL_ IC SG_ 867 PositionLightRearLamp_stat_ISig_ 1500;
BA_REL_ "GenSigFirstTimeoutTime" BU_SG_REL_ IC SG_ 867 TrailerPosLightRightOutputStat_I 6000;
BA_REL_ "GenSigTimeoutTime" BU_SG_REL_ IC SG_ 867 TrailerPosLightRightOutputStat_I 1500;
BA_REL_ "GenSigFirstTimeoutTime" BU_SG_REL_ IC SG_ 867 DirIndRearLamp_Stat_ISig_5 6000;
BA_REL_ "GenSigTimeoutTime" BU_SG_REL_ IC SG_ 867 DirIndRearLamp_Stat_ISig_5 1500;
BA_REL_ "GenSigFirstTimeoutTime" BU_SG_REL_ IC SG_ 867 FogLightRearLamp_stat_ISig_5 6000;
BA_REL_ "GenSigTimeoutTime" BU_SG_REL_ IC SG_ 867 FogLightRearLamp_stat_ISig_5 1500;
BA_REL_ "GenSigFirstTimeoutTime" BU_SG_REL_ IC SG_ 867 BrakeLightLamp_stat_ISig_5 6000;
BA_REL_ "GenSigTimeoutTime" BU_SG_REL_ IC SG_ 867 BrakeLightLamp_stat_ISig_5 1500;
BA_REL_ "GenSigFirstTimeoutTime" BU_SG_REL_ IC SG_ 867 DippedBeamLamp_stat_ISig_5 6000;
BA_REL_ "GenSigTimeoutTime" BU_SG_REL_ IC SG_ 867 DippedBeamLamp_stat_ISig_5 1500;
BA_REL_ "GenSigFirstTimeoutTime" BU_SG_REL_ IC SG_ 867 ChassiInstepLightsLamp_stat_ISig 6000;
BA_REL_ "GenSigTimeoutTime" BU_SG_REL_ IC SG_ 867 ChassiInstepLightsLamp_stat_ISig 1500;
BA_REL_ "GenSigFirstTimeoutTime" BU_SG_REL_ IC SG_ 867 DRLLamp_stat_ISig_5 6000;
BA_REL_ "GenSigTimeoutTime" BU_SG_REL_ IC SG_ 867 DRLLamp_stat_ISig_5 1500;
BA_REL_ "GenSigFirstTimeoutTime" BU_SG_REL_ IC SG_ 867 TrailerDirIndRightOutputStat_ISi 6000;
BA_REL_ "GenSigTimeoutTime" BU_SG_REL_ IC SG_ 867 TrailerDirIndRightOutputStat_ISi 1500;
BA_REL_ "GenSigFirstTimeoutTime" BU_SG_REL_ IC SG_ 867 HeadlampFan_stat_ISig_5 6000;
BA_REL_ "GenSigTimeoutTime" BU_SG_REL_ IC SG_ 867 HeadlampFan_stat_ISig_5 1500;
BA_REL_ "GenSigFirstTimeoutTime" BU_SG_REL_ IC SG_ 867 MainBeamLamp_stat_ISig_5 6000;
BA_REL_ "GenSigTimeoutTime" BU_SG_REL_ IC SG_ 867 MainBeamLamp_stat_ISig_5 1500;
BA_REL_ "GenSigFirstTimeoutTime" BU_SG_REL_ IC SG_ 867 StaticCornerLightLamp_stat_ISig_ 6000;
BA_REL_ "GenSigTimeoutTime" BU_SG_REL_ IC SG_ 867 StaticCornerLightLamp_stat_ISig_ 1500;
BA_REL_ "GenSigFirstTimeoutTime" BU_SG_REL_ IC SG_ 867 AuxFogLightLamp_stat_ISig_5 6000;
BA_REL_ "GenSigTimeoutTime" BU_SG_REL_ IC SG_ 867 AuxFogLightLamp_stat_ISig_5 1500;
BA_REL_ "GenSigFirstTimeoutTime" BU_SG_REL_ IC SG_ 867 PositionLightLamp_stat_ISig_5 6000;
BA_REL_ "GenSigTimeoutTime" BU_SG_REL_ IC SG_ 867 PositionLightLamp_stat_ISig_5 1500;
BA_REL_ "GenSigFirstTimeoutTime" BU_SG_REL_ CCM SG_ 866 BarometricPressure_ISig_5 6000;
BA_REL_ "GenSigTimeoutTime" BU_SG_REL_ CCM SG_ 866 BarometricPressure_ISig_5 1500;
BA_REL_ "GenSigFirstTimeoutTime" BU_SG_REL_ IC SG_ 866 LoadDistributionSelected2_ISig_5 6000;
BA_REL_ "GenSigTimeoutTime" BU_SG_REL_ IC SG_ 866 LoadDistributionSelected2_ISig_5 1500;
BA_REL_ "GenSigFirstTimeoutTime" BU_SG_REL_ IC SG_ 866 DriveAxleLoad_ISig_5 6000;
BA_REL_ "GenSigTimeoutTime" BU_SG_REL_ IC SG_ 866 DriveAxleLoad_ISig_5 1500;
BA_REL_ "GenSigFirstTimeoutTime" BU_SG_REL_ IC SG_ 866 StarterMotorRecoveryTime_ISig_5 6000;
BA_REL_ "GenSigTimeoutTime" BU_SG_REL_ IC SG_ 866 StarterMotorRecoveryTime_ISig_5 1500;
BA_REL_ "GenSigFirstTimeoutTime" BU_SG_REL_ IC SG_ 866 SecondaryDriveAxleLoad_ISig_5 6000;
BA_REL_ "GenSigTimeoutTime" BU_SG_REL_ IC SG_ 866 SecondaryDriveAxleLoad_ISig_5 1500;
BA_REL_ "GenSigFirstTimeoutTime" BU_SG_REL_ CCM SG_ 865 MonthLocal 6000;
BA_REL_ "GenSigTimeoutTime" BU_SG_REL_ CCM SG_ 865 MonthLocal 1500;
BA_REL_ "GenSigFirstTimeoutTime" BU_SG_REL_ CCM SG_ 865 SecondsLocal 6000;
BA_REL_ "GenSigTimeoutTime" BU_SG_REL_ CCM SG_ 865 SecondsLocal 1500;
BA_REL_ "GenSigFirstTimeoutTime" BU_SG_REL_ CCM SG_ 865 YearLocal 6000;
BA_REL_ "GenSigTimeoutTime" BU_SG_REL_ CCM SG_ 865 YearLocal 1500;
BA_REL_ "GenSigFirstTimeoutTime" BU_SG_REL_ CCM SG_ 865 DayLocal 6000;
BA_REL_ "GenSigTimeoutTime" BU_SG_REL_ CCM SG_ 865 DayLocal 1500;
BA_REL_ "GenSigFirstTimeoutTime" BU_SG_REL_ CCM SG_ 865 MinutesLocal 6000;
BA_REL_ "GenSigTimeoutTime" BU_SG_REL_ CCM SG_ 865 MinutesLocal 1500;
BA_REL_ "GenSigFirstTimeoutTime" BU_SG_REL_ CCM SG_ 865 HoursLocal 6000;
BA_REL_ "GenSigTimeoutTime" BU_SG_REL_ CCM SG_ 865 HoursLocal 1500;
BA_REL_ "GenSigFirstTimeoutTime" BU_SG_REL_ CCM SG_ 865 DayOfWeek_stat 6000;
BA_REL_ "GenSigTimeoutTime" BU_SG_REL_ CCM SG_ 865 DayOfWeek_stat 1500;
BA_REL_ "GenSigFirstTimeoutTime" BU_SG_REL_ IC SG_ 865 DayOfWeek_stat 6000;
BA_REL_ "GenSigTimeoutTime" BU_SG_REL_ IC SG_ 865 DayOfWeek_stat 1500;
BA_REL_ "GenSigFirstTimeoutTime" BU_SG_REL_ CCM SG_ 864 SecondsUTC_ISig_5 6000;
BA_REL_ "GenSigTimeoutTime" BU_SG_REL_ CCM SG_ 864 SecondsUTC_ISig_5 1500;
BA_REL_ "GenSigFirstTimeoutTime" BU_SG_REL_ CCM SG_ 864 MinutesUTC_ISig_5 6000;
BA_REL_ "GenSigTimeoutTime" BU_SG_REL_ CCM SG_ 864 MinutesUTC_ISig_5 1500;
BA_REL_ "GenSigFirstTimeoutTime" BU_SG_REL_ CCM SG_ 864 MonthUTC_ISig_5 6000;
BA_REL_ "GenSigTimeoutTime" BU_SG_REL_ CCM SG_ 864 MonthUTC_ISig_5 1500;
BA_REL_ "GenSigFirstTimeoutTime" BU_SG_REL_ CCM SG_ 864 YearUTC_ISig_5 6000;
BA_REL_ "GenSigTimeoutTime" BU_SG_REL_ CCM SG_ 864 YearUTC_ISig_5 1500;
BA_REL_ "GenSigFirstTimeoutTime" BU_SG_REL_ CCM SG_ 864 DayUTC_ISig_5 6000;
BA_REL_ "GenSigTimeoutTime" BU_SG_REL_ CCM SG_ 864 DayUTC_ISig_5 1500;
BA_REL_ "GenSigFirstTimeoutTime" BU_SG_REL_ CCM SG_ 864 HoursUTC_ISig_5 6000;
BA_REL_ "GenSigTimeoutTime" BU_SG_REL_ CCM SG_ 864 HoursUTC_ISig_5 1500;
BA_REL_ "GenSigFirstTimeoutTime" BU_SG_REL_ IC SG_ 696 RedGladHand_SqC_ISig_5 3000;
BA_REL_ "GenSigTimeoutTime" BU_SG_REL_ IC SG_ 696 RedGladHand_SqC_ISig_5 600;
BA_REL_ "GenSigFirstTimeoutTime" BU_SG_REL_ IC SG_ 696 RedGladHand_CRC_ISig_5 3000;
BA_REL_ "GenSigTimeoutTime" BU_SG_REL_ IC SG_ 696 RedGladHand_CRC_ISig_5 600;
BA_REL_ "GenSigFirstTimeoutTime" BU_SG_REL_ IC SG_ 696 TrailerStatus_IntegrityLvl_ISig_ 3000;
BA_REL_ "GenSigTimeoutTime" BU_SG_REL_ IC SG_ 696 TrailerStatus_IntegrityLvl_ISig_ 600;
BA_REL_ "GenSigFirstTimeoutTime" BU_SG_REL_ IC SG_ 696 TrailerStatus_CRC_ISig_5 3000;
BA_REL_ "GenSigTimeoutTime" BU_SG_REL_ IC SG_ 696 TrailerStatus_CRC_ISig_5 600;
BA_REL_ "GenSigFirstTimeoutTime" BU_SG_REL_ IC SG_ 696 RedGladHand_ConfidenceLvl_ISig_5 3000;
BA_REL_ "GenSigTimeoutTime" BU_SG_REL_ IC SG_ 696 RedGladHand_ConfidenceLvl_ISig_5 600;
BA_REL_ "GenSigFirstTimeoutTime" BU_SG_REL_ IC SG_ 696 TrailerStatus_SqC_ISig_5 3000;
BA_REL_ "GenSigTimeoutTime" BU_SG_REL_ IC SG_ 696 TrailerStatus_SqC_ISig_5 600;
BA_REL_ "GenSigFirstTimeoutTime" BU_SG_REL_ IC SG_ 696 TrailerStatus_Actuation_ISig_5 3000;
BA_REL_ "GenSigTimeoutTime" BU_SG_REL_ IC SG_ 696 TrailerStatus_Actuation_ISig_5 600;
BA_REL_ "GenSigFirstTimeoutTime" BU_SG_REL_ IC SG_ 696 RedGladHand_ConnectStatus_ISig_5 3000;
BA_REL_ "GenSigTimeoutTime" BU_SG_REL_ IC SG_ 696 RedGladHand_ConnectStatus_ISig_5 600;
BA_REL_ "GenSigFirstTimeoutTime" BU_SG_REL_ IC SG_ 695 TrafficSitPathEvent2_Type 3000;
BA_REL_ "GenSigTimeoutTime" BU_SG_REL_ IC SG_ 695 TrafficSitPathEvent2_Type 600;
BA_REL_ "GenSigFirstTimeoutTime" BU_SG_REL_ IC SG_ 695 TrafficSitPathEvent1_Distance 3000;
BA_REL_ "GenSigTimeoutTime" BU_SG_REL_ IC SG_ 695 TrafficSitPathEvent1_Distance 600;
BA_REL_ "GenSigFirstTimeoutTime" BU_SG_REL_ IC SG_ 695 TrafficSitPathEvent1_Speed 3000;
BA_REL_ "GenSigTimeoutTime" BU_SG_REL_ IC SG_ 695 TrafficSitPathEvent1_Speed 600;
BA_REL_ "GenSigFirstTimeoutTime" BU_SG_REL_ IC SG_ 695 TrafficSitPathEvent2_Speed 3000;
BA_REL_ "GenSigTimeoutTime" BU_SG_REL_ IC SG_ 695 TrafficSitPathEvent2_Speed 600;
BA_REL_ "GenSigFirstTimeoutTime" BU_SG_REL_ IC SG_ 695 TrafficSitPathEvent1_Type 3000;
BA_REL_ "GenSigTimeoutTime" BU_SG_REL_ IC SG_ 695 TrafficSitPathEvent1_Type 600;
BA_REL_ "GenSigFirstTimeoutTime" BU_SG_REL_ IC SG_ 695 TrafficSitPathEvent2_Distance 3000;
BA_REL_ "GenSigTimeoutTime" BU_SG_REL_ IC SG_ 695 TrafficSitPathEvent2_Distance 600;
BA_REL_ "GenSigFirstTimeoutTime" BU_SG_REL_ IC SG_ 694 BatteryCapacity_ISig_5 3000;
BA_REL_ "GenSigTimeoutTime" BU_SG_REL_ IC SG_ 694 BatteryCapacity_ISig_5 600;
BA_REL_ "GenSigFirstTimeoutTime" BU_SG_REL_ CCM SG_ 694 LivBatteryCharging_stat_ISig_5 3000;
BA_REL_ "GenSigTimeoutTime" BU_SG_REL_ CCM SG_ 694 LivBatteryCharging_stat_ISig_5 600;
BA_REL_ "GenSigFirstTimeoutTime" BU_SG_REL_ IC SG_ 694 BatteryCurrent_ISig_5 3000;
BA_REL_ "GenSigTimeoutTime" BU_SG_REL_ IC SG_ 694 BatteryCurrent_ISig_5 600;
BA_REL_ "GenSigFirstTimeoutTime" BU_SG_REL_ IC SG_ 694 AmbientLight_stat_ISig_5 3000;
BA_REL_ "GenSigTimeoutTime" BU_SG_REL_ IC SG_ 694 AmbientLight_stat_ISig_5 600;
BA_REL_ "GenSigFirstTimeoutTime" BU_SG_REL_ IC SG_ 693 TransmissionRangeSelected_ISig_5 3000;
BA_REL_ "GenSigTimeoutTime" BU_SG_REL_ IC SG_ 693 TransmissionRangeSelected_ISig_5 600;
BA_REL_ "GenSigFirstTimeoutTime" BU_SG_REL_ IC SG_ 693 TransmissionRangeAttained_ISig_5 3000;
BA_REL_ "GenSigTimeoutTime" BU_SG_REL_ IC SG_ 693 TransmissionRangeAttained_ISig_5 600;
BA_REL_ "GenSigFirstTimeoutTime" BU_SG_REL_ IC SG_ 693 FrontRoadWheelAngleEstimate1 3000;
BA_REL_ "GenSigTimeoutTime" BU_SG_REL_ IC SG_ 693 FrontRoadWheelAngleEstimate1 600;
BA_REL_ "GenSigFirstTimeoutTime" BU_SG_REL_ IC SG_ 693 WheelBasedVehicleSpeed_ISig_5 3000;
BA_REL_ "GenSigTimeoutTime" BU_SG_REL_ IC SG_ 693 WheelBasedVehicleSpeed_ISig_5 600;
BA_REL_ "GenSigFirstTimeoutTime" BU_SG_REL_ CCM SG_ 693 WheelBasedVehicleSpeed_ISig_5 3000;
BA_REL_ "GenSigTimeoutTime" BU_SG_REL_ CCM SG_ 693 WheelBasedVehicleSpeed_ISig_5 600;
BA_REL_ "GenSigFirstTimeoutTime" BU_SG_REL_ IC SG_ 692 BatterySOCactCriticalAlert_ISig_ 3000;
BA_REL_ "GenSigTimeoutTime" BU_SG_REL_ IC SG_ 692 BatterySOCactCriticalAlert_ISig_ 600;
BA_REL_ "GenSigFirstTimeoutTime" BU_SG_REL_ IC SG_ 692 BatterySOCTrustLevel_ISig_5 3000;
BA_REL_ "GenSigTimeoutTime" BU_SG_REL_ IC SG_ 692 BatterySOCTrustLevel_ISig_5 600;
BA_REL_ "GenSigFirstTimeoutTime" BU_SG_REL_ IC SG_ 692 BatterySOCnom_ISig_5 3000;
BA_REL_ "GenSigTimeoutTime" BU_SG_REL_ IC SG_ 692 BatterySOCnom_ISig_5 600;
BA_REL_ "GenSigFirstTimeoutTime" BU_SG_REL_ IC SG_ 692 BatteryTemp_ISig_5 3000;
BA_REL_ "GenSigTimeoutTime" BU_SG_REL_ IC SG_ 692 BatteryTemp_ISig_5 600;
BA_REL_ "GenSigFirstTimeoutTime" BU_SG_REL_ IC SG_ 692 BatteryVoltageDisplayValue_ISig_ 3000;
BA_REL_ "GenSigTimeoutTime" BU_SG_REL_ IC SG_ 692 BatteryVoltageDisplayValue_ISig_ 600;
BA_REL_ "GenSigFirstTimeoutTime" BU_SG_REL_ IC SG_ 692 BatterySOCact_ISig_5 3000;
BA_REL_ "GenSigTimeoutTime" BU_SG_REL_ IC SG_ 692 BatterySOCact_ISig_5 600;
BA_REL_ "GenSigFirstTimeoutTime" BU_SG_REL_ IC SG_ 692 BatterySOH_ISig_5 3000;
BA_REL_ "GenSigTimeoutTime" BU_SG_REL_ IC SG_ 692 BatterySOH_ISig_5 600;
BA_REL_ "GenSigFirstTimeoutTime" BU_SG_REL_ IC SG_ 691 AvailableGearsWithHigherRatio_IS 3000;
BA_REL_ "GenSigTimeoutTime" BU_SG_REL_ IC SG_ 691 AvailableGearsWithHigherRatio_IS 600;
BA_REL_ "GenSigFirstTimeoutTime" BU_SG_REL_ IC SG_ 691 EngineFuelRate_ISig_5 3000;
BA_REL_ "GenSigTimeoutTime" BU_SG_REL_ IC SG_ 691 EngineFuelRate_ISig_5 600;
BA_REL_ "GenSigFirstTimeoutTime" BU_SG_REL_ IC SG_ 691 DirectionIndicatorLightsStatus_I 3000;
BA_REL_ "GenSigTimeoutTime" BU_SG_REL_ IC SG_ 691 DirectionIndicatorLightsStatus_I 600;
BA_REL_ "GenSigFirstTimeoutTime" BU_SG_REL_ IC SG_ 691 ActualEngineRetarderPercentTrq_I 3000;
BA_REL_ "GenSigTimeoutTime" BU_SG_REL_ IC SG_ 691 ActualEngineRetarderPercentTrq_I 600;
BA_REL_ "GenSigFirstTimeoutTime" BU_SG_REL_ IC SG_ 691 ACC_SGO_Status_ISig_5 3000;
BA_REL_ "GenSigTimeoutTime" BU_SG_REL_ IC SG_ 691 ACC_SGO_Status_ISig_5 600;
BA_REL_ "GenSigFirstTimeoutTime" BU_SG_REL_ IC SG_ 691 BatteryEndOfChargeLSB_ISig_5 3000;
BA_REL_ "GenSigTimeoutTime" BU_SG_REL_ IC SG_ 691 BatteryEndOfChargeLSB_ISig_5 600;
BA_REL_ "GenSigFirstTimeoutTime" BU_SG_REL_ IC SG_ 691 PV_HeadLightLevel 3000;
BA_REL_ "GenSigTimeoutTime" BU_SG_REL_ IC SG_ 691 PV_HeadLightLevel 600;
BA_REL_ "GenSigFirstTimeoutTime" BU_SG_REL_ IC SG_ 691 BatteryEndOfChargeHSB_ISig_5 3000;
BA_REL_ "GenSigTimeoutTime" BU_SG_REL_ IC SG_ 691 BatteryEndOfChargeHSB_ISig_5 600;
BA_REL_ "GenSigFirstTimeoutTime" BU_SG_REL_ IC SG_ 691 SensorCleaningFluidLevelStatus_I 3000;
BA_REL_ "GenSigTimeoutTime" BU_SG_REL_ IC SG_ 691 SensorCleaningFluidLevelStatus_I 600;
BA_REL_ "GenSigFirstTimeoutTime" BU_SG_REL_ IC SG_ 691 ActualDrvlnRetdrPercentTorque_IS 3000;
BA_REL_ "GenSigTimeoutTime" BU_SG_REL_ IC SG_ 691 ActualDrvlnRetdrPercentTorque_IS 600;
BA_REL_ "GenSigFirstTimeoutTime" BU_SG_REL_ IC SG_ 691 AvailableGearsWithLowerRatio_ISi 3000;
BA_REL_ "GenSigTimeoutTime" BU_SG_REL_ IC SG_ 691 AvailableGearsWithLowerRatio_ISi 600;
BA_REL_ "GenSigFirstTimeoutTime" BU_SG_REL_ IC SG_ 690 SetHSAOperation_ISig_5 3000;
BA_REL_ "GenSigTimeoutTime" BU_SG_REL_ IC SG_ 690 SetHSAOperation_ISig_5 600;
BA_REL_ "GenSigFirstTimeoutTime" BU_SG_REL_ IC SG_ 690 PS_FogLightFront 3000;
BA_REL_ "GenSigTimeoutTime" BU_SG_REL_ IC SG_ 690 PS_FogLightFront 600;
BA_REL_ "GenSigFirstTimeoutTime" BU_SG_REL_ IC SG_ 690 CACCStatus_ISig_5 3000;
BA_REL_ "GenSigTimeoutTime" BU_SG_REL_ IC SG_ 690 CACCStatus_ISig_5 600;
BA_REL_ "GenSigFirstTimeoutTime" BU_SG_REL_ IC SG_ 690 Cab12VSupplyStatus_ISig_5 3000;
BA_REL_ "GenSigTimeoutTime" BU_SG_REL_ IC SG_ 690 Cab12VSupplyStatus_ISig_5 600;
BA_REL_ "GenSigFirstTimeoutTime" BU_SG_REL_ IC SG_ 690 TransmissionDrivingMode_ISig_5 3000;
BA_REL_ "GenSigTimeoutTime" BU_SG_REL_ IC SG_ 690 TransmissionDrivingMode_ISig_5 600;
BA_REL_ "GenSigFirstTimeoutTime" BU_SG_REL_ CCM SG_ 690 TransmissionDrivingMode_ISig_5 3000;
BA_REL_ "GenSigTimeoutTime" BU_SG_REL_ CCM SG_ 690 TransmissionDrivingMode_ISig_5 600;
BA_REL_ "GenSigFirstTimeoutTime" BU_SG_REL_ IC SG_ 690 LowAirPressureAlert_ISig_5 3000;
BA_REL_ "GenSigTimeoutTime" BU_SG_REL_ IC SG_ 690 LowAirPressureAlert_ISig_5 600;
BA_REL_ "GenSigFirstTimeoutTime" BU_SG_REL_ IC SG_ 690 TemporaryRSLSwitchStatus 3000;
BA_REL_ "GenSigTimeoutTime" BU_SG_REL_ IC SG_ 690 TemporaryRSLSwitchStatus 600;
BA_REL_ "GenSigFirstTimeoutTime" BU_SG_REL_ IC SG_ 690 BatterySOCAlertRawData_rqst_ISig 3000;
BA_REL_ "GenSigTimeoutTime" BU_SG_REL_ IC SG_ 690 BatterySOCAlertRawData_rqst_ISig 600;
BA_REL_ "GenSigFirstTimeoutTime" BU_SG_REL_ CCM SG_ 690 BatterySOCAlertRawData_rqst_ISig 3000;
BA_REL_ "GenSigTimeoutTime" BU_SG_REL_ CCM SG_ 690 BatterySOCAlertRawData_rqst_ISig 600;
BA_REL_ "GenSigFirstTimeoutTime" BU_SG_REL_ IC SG_ 690 BatteryTempAlertRawData_rqst_ISi 3000;
BA_REL_ "GenSigTimeoutTime" BU_SG_REL_ IC SG_ 690 BatteryTempAlertRawData_rqst_ISi 600;
BA_REL_ "GenSigFirstTimeoutTime" BU_SG_REL_ IC SG_ 690 BrakeTemperatureWarning_ISig_5 3000;
BA_REL_ "GenSigTimeoutTime" BU_SG_REL_ IC SG_ 690 BrakeTemperatureWarning_ISig_5 600;
BA_REL_ "GenSigFirstTimeoutTime" BU_SG_REL_ IC SG_ 690 WheelSlipControllerMode_ISig_5 3000;
BA_REL_ "GenSigTimeoutTime" BU_SG_REL_ IC SG_ 690 WheelSlipControllerMode_ISig_5 600;
BA_REL_ "GenSigFirstTimeoutTime" BU_SG_REL_ IC SG_ 690 Rainsensor_Indication_ISig_5 3000;
BA_REL_ "GenSigTimeoutTime" BU_SG_REL_ IC SG_ 690 Rainsensor_Indication_ISig_5 600;
BA_REL_ "GenSigFirstTimeoutTime" BU_SG_REL_ IC SG_ 690 ESCHealthStatus_ISig_5 3000;
BA_REL_ "GenSigTimeoutTime" BU_SG_REL_ IC SG_ 690 ESCHealthStatus_ISig_5 600;
BA_REL_ "GenSigFirstTimeoutTime" BU_SG_REL_ IC SG_ 690 TLInflationAcceptance_stat_ISig_ 3000;
BA_REL_ "GenSigTimeoutTime" BU_SG_REL_ IC SG_ 690 TLInflationAcceptance_stat_ISig_ 600;
BA_REL_ "GenSigFirstTimeoutTime" BU_SG_REL_ IC SG_ 690 AutoLoadCutOffState_ISig_5 3000;
BA_REL_ "GenSigTimeoutTime" BU_SG_REL_ IC SG_ 690 AutoLoadCutOffState_ISig_5 600;
BA_REL_ "GenSigFirstTimeoutTime" BU_SG_REL_ IC SG_ 690 TransmissionOilTempHigh_ISig_5 3000;
BA_REL_ "GenSigTimeoutTime" BU_SG_REL_ IC SG_ 690 TransmissionOilTempHigh_ISig_5 600;
BA_REL_ "GenSigFirstTimeoutTime" BU_SG_REL_ IC SG_ 690 ECSLimpHomeNotification_ISig_5 3000;
BA_REL_ "GenSigTimeoutTime" BU_SG_REL_ IC SG_ 690 ECSLimpHomeNotification_ISig_5 600;
BA_REL_ "GenSigFirstTimeoutTime" BU_SG_REL_ IC SG_ 690 EqualizerUnbalance_ISig_5 3000;
BA_REL_ "GenSigTimeoutTime" BU_SG_REL_ IC SG_ 690 EqualizerUnbalance_ISig_5 600;
BA_REL_ "GenSigFirstTimeoutTime" BU_SG_REL_ IC SG_ 690 AutGearSplitPosition_ISig_5 3000;
BA_REL_ "GenSigTimeoutTime" BU_SG_REL_ IC SG_ 690 AutGearSplitPosition_ISig_5 600;
BA_REL_ "GenSigFirstTimeoutTime" BU_SG_REL_ IC SG_ 690 BatterySOCAlert_rqst_ISig_5 3000;
BA_REL_ "GenSigTimeoutTime" BU_SG_REL_ IC SG_ 690 BatterySOCAlert_rqst_ISig_5 600;
BA_REL_ "GenSigFirstTimeoutTime" BU_SG_REL_ IC SG_ 690 DriveModeSwitchUserOverride_ISig 3000;
BA_REL_ "GenSigTimeoutTime" BU_SG_REL_ IC SG_ 690 DriveModeSwitchUserOverride_ISig 600;
BA_REL_ "GenSigFirstTimeoutTime" BU_SG_REL_ IC SG_ 690 BatteryTempAlert_rqst_ISig_5 3000;
BA_REL_ "GenSigTimeoutTime" BU_SG_REL_ IC SG_ 690 BatteryTempAlert_rqst_ISig_5 600;
BA_REL_ "GenSigFirstTimeoutTime" BU_SG_REL_ IC SG_ 690 TrailerEBSFault_ISig_5 3000;
BA_REL_ "GenSigTimeoutTime" BU_SG_REL_ IC SG_ 690 TrailerEBSFault_ISig_5 600;
VAL_ 1202 SCROperatorInducementSeverity_IS 7 "SCROperatorInducementSeverity_NotAvailable" 6 "SCROperatorInducementSeverity_Reserved" 5 "SCROperatorInducementSeverity_SevereInducementActive" 4 "SCROperatorInducementSeverity_SevereIndEnabledWaitActCondition" 3 "SCROperatorInducementSeverity_IndLevel3LowLevelInducementActive" 2 "SCROperatorInducementSeverity_IndLevel2IntensiveWarning" 1 "SCROperatorInducementSeverity_IndLevel1InitialWarning" 0 "SCROperatorInducementSeverity_NoInducementActive" ;
VAL_ 1202 CatalystTankLevelLow_ISig_5 3 "Warning_NotAvailable" 2 "Warning_Error" 1 "Warning_Warning" 0 "Warning_NoWarning" ;
VAL_ 1202 MIStatusExtEMS_ISig_5 3 "MIStatusExt_NotAvailable" 2 "MIStatusExt_Error" 1 "MIStatusExt_Ready" 0 "MIStatusExt_NotReady5Flash" ;
VAL_ 1202 FuelOperatorDeratingReason_ISig_ 3 "FuelOperatorDeratingReason_NotAvailable" 2 "FuelOperatorDeratingReason_IncorrectQuality" 1 "FuelOperatorDeratingReason_IncorrectFuelBlend" 0 "FuelOperatorDeratingReason_FuelBlendOK" ;
VAL_ 1202 ActualFasPersSettingsButton_ISig 7 "FasPersSettingsButton_NotAvailable" 6 "FasPersSettingsButton_Error" 5 "FasPersSettingsButton_Spare" 4 "FasPersSettingsButton_UserDefinedButton" 3 "FasPersSettingsButton_PresetButtonHeavy" 2 "FasPersSettingsButton_PresetButtonFirm" 1 "FasPersSettingsButton_PresetButtonLight" 0 "FasPersSettingsButton_PresetButtonDefault" ;
VAL_ 1202 BatteryEndOfCharge_ISig_5 3 "FalseTrue_NotAvaiable" 2 "FalseTrue_Error" 1 "FalseTrue_True" 0 "FalseTrue_False" ;
VAL_ 1202 LiningWearWarning_ISig_5 3 "Warning_NotAvailable" 2 "Warning_Error" 1 "Warning_Warning" 0 "Warning_NoWarning" ;
VAL_ 1202 TorqueReductionStatus_OBD_ISig_5 7 "TorqueReductionStatus_OBD_NotAvailable" 6 "TorqueReductionStatus_OBD_Error" 5 "TorqueReductionStatus_OBD_Spare_01" 4 "TorqueReductionStatus_OBD_Spare" 3 "TorqueReductionStatus_OBD_TorqueReductionActive" 2 "TorqueReductionStatus_OBD_TorqueReductionActiveNextStandstill" 1 "TorqueReductionStatus_OBD_Pending" 0 "TorqueReductionStatus_OBD_NotActive" ;
VAL_ 1202 LoadCalibrationFeedback_ISig_5 7 "LoadCalibrationFeedback_NotAvailable" 6 "LoadCalibrationFeedback_Spare3" 5 "LoadCalibrationFeedback_Spare2" 4 "LoadCalibrationFeedback_Spare1" 3 "LoadCalibrationFeedback_NOK" 2 "LoadCalibrationFeedback_OK" 1 "LoadCalibrationFeedback_InProgress" 0 "LoadCalibrationFeedback_NotRequested" ;
VAL_ 1202 FuelOperatorDeratingSeverity_ISi 7 "FuelOperatorDeratingSeverity_NotAvailable" 6 "FuelOperatorDeratingSeverity_TemporaryOverrideOfDerating" 5 "FuelOperatorDeratingSeverity_SevereDerate" 4 "FuelOperatorDeratingSeverity_SevereDeratePending" 3 "FuelOperatorDeratingSeverity_EngineDerate" 2 "FuelOperatorDeratingSeverity_EngineDeratePending" 1 "FuelOperatorDeratingSeverity_Warning" 0 "FuelOperatorDeratingSeverity_NoDeratingActive" ;
VAL_ 1202 SCROperatorInducementReason_ISig 7 "SCROperatorInducementReason_NotAvailable" 6 "SCROperatorInducementReason_Error" 5 "SCROperatorInducementReason_Spare" 4 "SCROperatorInducementReason_Tampering" 3 "SCROperatorInducementReason_IncorrectConsumption" 2 "SCROperatorInducementReason_IncorrectQuality" 1 "SCROperatorInducementReason_ReagentLevelLow" 0 "SCROperatorInducementReason_OK" ;
VAL_ 1202 MIDistinctWarningExtEMS_ISig_5 15 "MIDistinctWarningExt_NotAvailable" 14 "MIDistinctWarningExt_Error" 3 "MIDistinctWarningExt_ContinuousMISteady" 2 "MIDistinctWarningExt_ShortMI3Flash" 1 "MIDistinctWarningExt_OnDemandMI2Flash" 0 "MIDistinctWarningExt_Off1Flash" ;
VAL_ 1202 FasDriver_ISig_5 15 "FasDriver_NotAvailable" 14 "FasDriver_Error" 13 "FasDriver_Spare3" 12 "FasDriver_Spare2" 11 "FasDriver_Spare1" 10 "FasDriver_Driver10" 9 "FasDriver_Driver9" 8 "FasDriver_Driver8" 7 "FasDriver_Driver7" 6 "FasDriver_Driver6" 5 "FasDriver_Driver5" 4 "FasDriver_Driver4" 3 "FasDriver_Driver3" 2 "FasDriver_Driver2" 1 "FasDriver_Driver1" 0 "FasDriver_DefaultDriver" ;
VAL_ 1202 MIDistinctWarning_ISig_5 3 "OffOn_NotAvailable" 2 "OffOn_Error" 1 "OffOn_On" 0 "OffOn_Off" ;
VAL_ 902 Cur_EnergySetting_ISig_5 7 "EnergySetting_NotAvailable" 6 "EnergySetting_Error" 5 "EnergySetting_Spare2" 4 "EnergySetting_Spare1" 3 "EnergySetting_Customise" 2 "EnergySetting_PresetLevel2_HighEnergySaving" 1 "EnergySetting_PresetLevel1_EnergySaving" 0 "EnergySetting_OFF" ;
VAL_ 902 UltracapDisplay_Stat_ISig_5 7 "StartBatteryDisplay_NotAvailable" 6 "StartBatteryDisplay_Error" 5 "StartBatteryDisplay_StartBattery_ShortCircuit" 4 "StartBatteryDisplay_StartBattery_OverVoltage" 3 "StartBatteryDisplay_StartBattery_OpenCircuit" 2 "StartBatteryDisplay_StartBattery_Idle" 1 "StartBatteryDisplay_StartBattery_Charged" 0 "StartBatteryDisplay_StartBattery_Charging" ;
VAL_ 902 Ultracap_Status_ISig_5 7 "Ultracap_Status_NotAvailable" 6 "Ultracap_Status_Error" 5 "Ultracap_Status_Spare3" 4 "Ultracap_Status_Spare2" 3 "Ultracap_Status_Spare1" 2 "Ultracap_Status_Malfunction" 1 "Ultracap_Status_ForceCharging" 0 "Ultracap_Status_Healthy" ;
VAL_ 901 AxleLoadStatus_ISig_5 7 "AxleLoadStatus_NotAvailable" 6 "AxleLoadStatus_Error" 5 "AxleLoadStatus_Spare2" 4 "AxleLoadStatus_Spare1" 3 "AxleLoadStatus_Overload" 2 "AxleLoadStatus_HighLoad2" 1 "AxleLoadStatus_HighLoad1" 0 "AxleLoadStatus_NormalLoad" ;
VAL_ 901 ClutchAbuseStatus_ISig_5 3 "ClutchAbuseStatus_NotAvailable" 2 "ClutchAbuseStatus_Error" 1 "ClutchAbuseStatus_ClutchAbused" 0 "ClutchAbuseStatus_ClutchNotAbused" ;
VAL_ 901 ISeeStatus_ISig_5 7 "ISeeStatus_NotAvailable" 6 "ISeeStatus_Error" 5 "ISeeStatus_Spare2" 4 "ISeeStatus_Spare1" 3 "ISeeStatus_EnabledAndActive" 2 "ISeeStatus_EnabledButInactive" 1 "ISeeStatus_Disabled" 0 "ISeeStatus_Off" ;
VAL_ 901 TransmissionSplitboxPTOMode_ISig 7 "TransmissionSplitboxPTOMode_NotAvailable" 6 "TransmissionSplitboxPTOMode_Error" 5 "TransmissionSplitboxPTOMode_Spare3" 4 "TransmissionSplitboxPTOMode_Spare2" 3 "TransmissionSplitboxPTOMode_Spare1" 2 "TransmissionSplitboxPTOMode_Running" 1 "TransmissionSplitboxPTOMode_Standby" 0 "TransmissionSplitboxPTOMode_Inactive" ;
VAL_ 901 OilLevelDrvInstr_IncorrEngSpe_IS 3 "DisplayText_NotAvailable" 2 "DisplayText_Error" 1 "DisplayText_DisplayText" 0 "DisplayText_DoNotDisplayText" ;
VAL_ 901 OilLevelDrvInstr_ChangeGearTxt_I 3 "DisplayText_NotAvailable" 2 "DisplayText_Error" 1 "DisplayText_DisplayText" 0 "DisplayText_DoNotDisplayText" ;
VAL_ 901 PredeliveryModeIndication_cmd_IS 3 "DeactivateActivate_NotAvailable" 2 "DeactivateActivate_Error" 1 "DeactivateActivate_Activate" 0 "DeactivateActivate_Deactivate" ;
VAL_ 901 OilLevelDrvInstr_Wait60SecTxt_IS 3 "DisplayText_NotAvailable" 2 "DisplayText_Error" 1 "DisplayText_DisplayText" 0 "DisplayText_DoNotDisplayText" ;
VAL_ 901 DPF_LimitedSpeedDuetoInhibit_ISi 7 "LimitedSpeedInhibit_NotAvailable" 6 "LimitedSpeedInhibit_Error" 5 "LimitedSpeedInhibit_Spare2" 4 "LimitedSpeedInhibit_Spare1" 3 "LimitedSpeedInhibit_SpeedNotLimited_InhibitActive" 2 "LimitedSpeedInhibit_SpeedNotLimited_InhibitDenied" 1 "LimitedSpeedInhibit_SpeedLimited_InhibitionActive" 0 "LimitedSpeedInhibit_SpeedNotLimited_NoInhibitRequest" ;
VAL_ 901 DPF_ParkedRegenStatus_ISig_5 7 "ParkedRegenStatus_NotAvailable" 6 "ParkedRegenStatus_Error" 5 "ParkedRegenStatus_Spare2" 4 "ParkedRegenStatus_HCRegenOngoing" 3 "ParkedRegenStatus_ParkedRegenOngoing" 2 "ParkedRegenStatus_Aborted" 1 "ParkedRegenStatus_Completed" 0 "ParkedRegenStatus_NoInformation" ;
VAL_ 901 OilLevelDrvInstr_OilTempTxt_ISig 3 "DisplayText_NotAvailable" 2 "DisplayText_Error" 1 "DisplayText_DisplayText" 0 "DisplayText_DoNotDisplayText" ;
VAL_ 901 OilLevelDrvInstr_StopVehicle_ISi 3 "DisplayText_NotAvailable" 2 "DisplayText_Error" 1 "DisplayText_DisplayText" 0 "DisplayText_DoNotDisplayText" ;
VAL_ 901 ClutchCalibration_stat_ISig_5 3 "InactiveActive_NotAvailable" 2 "InactiveActive_Error" 1 "InactiveActive_Active" 0 "InactiveActive_Inactive" ;
VAL_ 901 OilLevelDrvInstr_NotHorizonTxt_I 3 "DisplayText_NotAvailable" 2 "DisplayText_Error" 1 "DisplayText_DisplayText" 0 "DisplayText_DoNotDisplayText" ;
VAL_ 868 DrainPrimingStatus_ISig_5 7 "DrainPrimingStatus_NotAvailable" 6 "DrainPrimingStatus_Error" 5 "DrainPrimingStatus_SpareValue_01" 4 "DrainPrimingStatus_SpareValue" 3 "DrainPrimingStatus_DrainingActive" 2 "DrainPrimingStatus_PrimingActive" 1 "DrainPrimingStatus_DrainingPrimingNotAllowed" 0 "DrainPrimingStatus_DrainingPrimingInactive" ;
VAL_ 868 FrontConspicLamp_stat_HiRight_IS 7 "LampCheck_stat_NotAvailable" 6 "LampCheck_stat_Error" 5 "LampCheck_stat_Spare_02" 4 "LampCheck_stat_Spare_01" 3 "LampCheck_stat_Spare" 2 "LampCheck_stat_TestedLampNOK" 1 "LampCheck_stat_TestedLampOK" 0 "LampCheck_stat_NotTested" ;
VAL_ 868 FrontConspicLamp_stat_LoRight_IS 7 "LampCheck_stat_NotAvailable" 6 "LampCheck_stat_Error" 5 "LampCheck_stat_Spare_02" 4 "LampCheck_stat_Spare_01" 3 "LampCheck_stat_Spare" 2 "LampCheck_stat_TestedLampNOK" 1 "LampCheck_stat_TestedLampOK" 0 "LampCheck_stat_NotTested" ;
VAL_ 868 CoolantTempHigh_ISig_5 7 "TempHigh3bit_NotAvailable" 6 "TempHigh3bit_Error" 5 "TempHigh3bit_HighLevel5" 4 "TempHigh3bit_HighLevel4" 3 "TempHigh3bit_HighLevel3" 2 "TempHigh3bit_HighLevel2" 1 "TempHigh3bit_HighLevel1" 0 "TempHigh3bit_OK" ;
VAL_ 868 AutoWheelBrakesStatus_ISig_5 7 "AutoWheelBrakesStatus_NotAvailable" 6 "AutoWheelBrakesStatus_Error" 5 "AutoWheelBrakesStatus_Spare3" 4 "AutoWheelBrakesStatus_Spare2" 3 "AutoWheelBrakesStatus_AWBActive" 2 "AutoWheelBrakesStatus_ReducedAutoBraking_WithoutSerBrkDemand" 1 "AutoWheelBrakesStatus_FullAutoBraking_withSerBrksDemand" 0 "AutoWheelBrakesStatus_NoAutoBrakingActive" ;
VAL_ 868 OilLevelLow_ISig_5 7 "LevelLow3bit_NotAvailable" 6 "LevelLow3bit_Error" 5 "LevelLow3bit_LowLevel5" 4 "LevelLow3bit_LowLevel4" 3 "LevelLow3bit_LowLevel3" 2 "LevelLow3bit_LowLevel2" 1 "LevelLow3bit_LowLevel1" 0 "LevelLow3bit_OK" ;
VAL_ 868 InletAirHeaterStatus1_ISig_5 3 "OffOn_NotAvailable" 2 "OffOn_Error" 1 "OffOn_On" 0 "OffOn_Off" ;
VAL_ 868 DeicingFunction_Stat_ISig_5 7 "DeicingFunction_Stat_NotAvailable" 6 "DeicingFunction_Stat_Spare2" 5 "DeicingFunction_Stat_Spare1" 4 "DeicingFunction_Stat_Fault" 3 "DeicingFunction_Stat_Deactivated" 2 "DeicingFunction_Stat_Ongoing" 1 "DeicingFunction_Stat_Activated" 0 "DeicingFunction_Stat_NotTested" ;
VAL_ 868 SelfStartAssist_stat_ISig_5 3 "SelfStartAssist_stat_NotAvailable" 2 "SelfStartAssist_stat_Requested_Initiated" 1 "SelfStartAssist_stat_Ready" 0 "SelfStartAssist_stat_NotRequested" ;
VAL_ 868 TrailerDirIndLeftOutputStat_ISig 7 "TrailerLightOutputStat_NotAvailable" 6 "TrailerLightOutputStat_Error" 5 "TrailerLightOutputStat_OutputActiveStatusUncertain" 4 "TrailerLightOutputStat_OutputActiveLightDetectedOnActivation" 3 "TrailerLightOutputStat_OutputActiveLightDetected" 2 "TrailerLightOutputStat_OutputActiveNoLightDetected" 1 "TrailerLightOutputStat_OutputActiveDetectionOngoing" 0 "TrailerLightOutputStat_OutputInactive" ;
VAL_ 868 TrailerPosLightLeftOutputStat_IS 7 "TrailerLightOutputStat_NotAvailable" 6 "TrailerLightOutputStat_Error" 5 "TrailerLightOutputStat_OutputActiveStatusUncertain" 4 "TrailerLightOutputStat_OutputActiveLightDetectedOnActivation" 3 "TrailerLightOutputStat_OutputActiveLightDetected" 2 "TrailerLightOutputStat_OutputActiveNoLightDetected" 1 "TrailerLightOutputStat_OutputActiveDetectionOngoing" 0 "TrailerLightOutputStat_OutputInactive" ;
VAL_ 868 TrailerBrakeLightOutputStat_ISig 7 "TrailerLightOutputStat_NotAvailable" 6 "TrailerLightOutputStat_Error" 5 "TrailerLightOutputStat_OutputActiveStatusUncertain" 4 "TrailerLightOutputStat_OutputActiveLightDetectedOnActivation" 3 "TrailerLightOutputStat_OutputActiveLightDetected" 2 "TrailerLightOutputStat_OutputActiveNoLightDetected" 1 "TrailerLightOutputStat_OutputActiveDetectionOngoing" 0 "TrailerLightOutputStat_OutputInactive" ;
VAL_ 868 StartBatteryDisplay_stat_ISig_5 7 "StartBatteryDisplay_NotAvailable" 6 "StartBatteryDisplay_Error" 5 "StartBatteryDisplay_StartBattery_ShortCircuit" 4 "StartBatteryDisplay_StartBattery_OverVoltage" 3 "StartBatteryDisplay_StartBattery_OpenCircuit" 2 "StartBatteryDisplay_StartBattery_Idle" 1 "StartBatteryDisplay_StartBattery_Charged" 0 "StartBatteryDisplay_StartBattery_Charging" ;
VAL_ 868 DeicingBulb_Stat_ISig_5 7 "DeicingBulb_Stat_NotAvailable" 6 "DeicingBulb_Stat_Error" 5 "DeicingBulb_Stat_Spare2" 4 "DeicingBulb_Stat_Spare1" 3 "DeicingBulb_Stat_BothLampsNOK" 2 "DeicingBulb_Stat_AtleastOneLampOK" 1 "DeicingBulb_Stat_BothLampsOK" 0 "DeicingBulb_Stat_NotTested" ;
VAL_ 868 LivBatDisconnectDetectStat_ISig_ 3 "LivBatDisconnectDetectStat_Not_Available" 2 "LivBatDisconnectDetectStat_Error" 1 "LivBatDisconnectDetectStat_Battery_Disconnected" 0 "LivBatDisconnectDetectStat_Battery_NotDisconnected" ;
VAL_ 868 FrontConspicLamp_stat_LoLeft_ISi 7 "LampCheck_stat_NotAvailable" 6 "LampCheck_stat_Error" 5 "LampCheck_stat_Spare_02" 4 "LampCheck_stat_Spare_01" 3 "LampCheck_stat_Spare" 2 "LampCheck_stat_TestedLampNOK" 1 "LampCheck_stat_TestedLampOK" 0 "LampCheck_stat_NotTested" ;
VAL_ 868 FuelFilterClogged_ISig_5 7 "LevelLow3bit_NotAvailable" 6 "LevelLow3bit_Error" 5 "LevelLow3bit_LowLevel5" 4 "LevelLow3bit_LowLevel4" 3 "LevelLow3bit_LowLevel3" 2 "LevelLow3bit_LowLevel2" 1 "LevelLow3bit_LowLevel1" 0 "LevelLow3bit_OK" ;
VAL_ 868 EngineFanOverspeed_ISig_5 3 "NoYes_NotAvailable" 2 "NoYes_Error" 1 "NoYes_Yes" 0 "NoYes_No" ;
VAL_ 868 JumpChargeInterface_stat_ISig_5 3 "Connection_Status_NotAvailable" 2 "Connection_Status_Error" 1 "Connection_Status_Connected" 0 "Connection_Status_NotConnected" ;
VAL_ 868 OilPressureLow_ISig_5 7 "LevelLow3bit_NotAvailable" 6 "LevelLow3bit_Error" 5 "LevelLow3bit_LowLevel5" 4 "LevelLow3bit_LowLevel4" 3 "LevelLow3bit_LowLevel3" 2 "LevelLow3bit_LowLevel2" 1 "LevelLow3bit_LowLevel1" 0 "LevelLow3bit_OK" ;
VAL_ 868 FrontConspicLamp_stat_HiLeft_ISi 7 "LampCheck_stat_NotAvailable" 6 "LampCheck_stat_Error" 5 "LampCheck_stat_Spare_02" 4 "LampCheck_stat_Spare_01" 3 "LampCheck_stat_Spare" 2 "LampCheck_stat_TestedLampNOK" 1 "LampCheck_stat_TestedLampOK" 0 "LampCheck_stat_NotTested" ;
VAL_ 868 GChargerStatus_ISig_5 7 "GridCharger_stat_NotAvailable" 6 "GridCharger_stat_Error" 5 "GridCharger_stat_GridchargerTemperatureIssue" 4 "GridCharger_stat_Reversepolarityissue" 3 "GridCharger_stat_MaintenanceCharging" 2 "GridCharger_stat_Charging" 1 "GridCharger_stat_Connected" 0 "GridCharger_stat_NotConnected" ;
VAL_ 868 TrailerRevAndFogOutput_stat_ISig 3 "TrailerRevAndFogOutput_stat_NotAvailable" 2 "TrailerRevAndFogOutput_stat_AtLeastOneLampNotOK" 1 "TrailerRevAndFogOutput_stat_AllLampsOK" 0 "TrailerRevAndFogOutput_stat_NotTested" ;
VAL_ 867 DirIndSideLamp_stat 7 "LampCheckLeftRight_stat_NotAvailable" 6 "LampCheckLeftRight_stat_Error" 5 "LampCheckLeftRight_stat_Spare" 4 "LampCheckLeftRight_stat_TestedLeftAndRightLampNOK" 3 "LampCheckLeftRight_stat_TestedRightLampNOK" 2 "LampCheckLeftRight_stat_TestedLeftLampNOK" 1 "LampCheckLeftRight_stat_TestedLampOK" 0 "LampCheckLeftRight_stat_NotTested" ;
VAL_ 867 DirInd_Front_Status_ISig_5 7 "DirIndFaultStatus_NotAvailable" 6 "DirIndFaultStatus_Error" 5 "DirIndFaultStatus_SpareValue_01" 4 "DirIndFaultStatus_SpareValue" 3 "DirIndFaultStatus_BothLeftAndRightDirectionIndicatorsFault" 2 "DirIndFaultStatus_RightDirectionIndicatorLampFault" 1 "DirIndFaultStatus_LeftDirectionIndicatorLampFault" 0 "DirIndFaultStatus_NoError" ;
VAL_ 867 FogLightFrontLamp_stat_ISig_5 7 "LampCheck_stat_NotAvailable" 6 "LampCheck_stat_Error" 5 "LampCheck_stat_Spare_02" 4 "LampCheck_stat_Spare_01" 3 "LampCheck_stat_Spare" 2 "LampCheck_stat_TestedLampNOK" 1 "LampCheck_stat_TestedLampOK" 0 "LampCheck_stat_NotTested" ;
VAL_ 867 MainBeamLEDStatusRight_ISig_5 7 "LampCheck_stat_NotAvailable" 6 "LampCheck_stat_Error" 5 "LampCheck_stat_Spare_02" 4 "LampCheck_stat_Spare_01" 3 "LampCheck_stat_Spare" 2 "LampCheck_stat_TestedLampNOK" 1 "LampCheck_stat_TestedLampOK" 0 "LampCheck_stat_NotTested" ;
VAL_ 867 RevLightLamp_stat_ISig_5 7 "LampCheckLeftRight_stat_NotAvailable" 6 "LampCheckLeftRight_stat_Error" 5 "LampCheckLeftRight_stat_Spare" 4 "LampCheckLeftRight_stat_TestedLeftAndRightLampNOK" 3 "LampCheckLeftRight_stat_TestedRightLampNOK" 2 "LampCheckLeftRight_stat_TestedLeftLampNOK" 1 "LampCheckLeftRight_stat_TestedLampOK" 0 "LampCheckLeftRight_stat_NotTested" ;
VAL_ 867 ExtraMainBeamLamp_stat_ISig_5 7 "LampCheckLeftRight_stat_NotAvailable" 6 "LampCheckLeftRight_stat_Error" 5 "LampCheckLeftRight_stat_Spare" 4 "LampCheckLeftRight_stat_TestedLeftAndRightLampNOK" 3 "LampCheckLeftRight_stat_TestedRightLampNOK" 2 "LampCheckLeftRight_stat_TestedLeftLampNOK" 1 "LampCheckLeftRight_stat_TestedLampOK" 0 "LampCheckLeftRight_stat_NotTested" ;
VAL_ 867 MainBeamLEDStatusLeft_ISig_5 7 "LampCheck_stat_NotAvailable" 6 "LampCheck_stat_Error" 5 "LampCheck_stat_Spare_02" 4 "LampCheck_stat_Spare_01" 3 "LampCheck_stat_Spare" 2 "LampCheck_stat_TestedLampNOK" 1 "LampCheck_stat_TestedLampOK" 0 "LampCheck_stat_NotTested" ;
VAL_ 867 PositionLightRearLamp_stat_ISig_ 7 "LampCheckLeftRight_stat_NotAvailable" 6 "LampCheckLeftRight_stat_Error" 5 "LampCheckLeftRight_stat_Spare" 4 "LampCheckLeftRight_stat_TestedLeftAndRightLampNOK" 3 "LampCheckLeftRight_stat_TestedRightLampNOK" 2 "LampCheckLeftRight_stat_TestedLeftLampNOK" 1 "LampCheckLeftRight_stat_TestedLampOK" 0 "LampCheckLeftRight_stat_NotTested" ;
VAL_ 867 TrailerPosLightRightOutputStat_I 7 "TrailerLightOutputStat_NotAvailable" 6 "TrailerLightOutputStat_Error" 5 "TrailerLightOutputStat_OutputActiveStatusUncertain" 4 "TrailerLightOutputStat_OutputActiveLightDetectedOnActivation" 3 "TrailerLightOutputStat_OutputActiveLightDetected" 2 "TrailerLightOutputStat_OutputActiveNoLightDetected" 1 "TrailerLightOutputStat_OutputActiveDetectionOngoing" 0 "TrailerLightOutputStat_OutputInactive" ;
VAL_ 867 DirIndRearLamp_Stat_ISig_5 7 "LampCheckLeftRight_stat_NotAvailable" 6 "LampCheckLeftRight_stat_Error" 5 "LampCheckLeftRight_stat_Spare" 4 "LampCheckLeftRight_stat_TestedLeftAndRightLampNOK" 3 "LampCheckLeftRight_stat_TestedRightLampNOK" 2 "LampCheckLeftRight_stat_TestedLeftLampNOK" 1 "LampCheckLeftRight_stat_TestedLampOK" 0 "LampCheckLeftRight_stat_NotTested" ;
VAL_ 867 FogLightRearLamp_stat_ISig_5 7 "LampCheck_stat_NotAvailable" 6 "LampCheck_stat_Error" 5 "LampCheck_stat_Spare_02" 4 "LampCheck_stat_Spare_01" 3 "LampCheck_stat_Spare" 2 "LampCheck_stat_TestedLampNOK" 1 "LampCheck_stat_TestedLampOK" 0 "LampCheck_stat_NotTested" ;
VAL_ 867 BrakeLightLamp_stat_ISig_5 7 "LampCheckLeftRight_stat_NotAvailable" 6 "LampCheckLeftRight_stat_Error" 5 "LampCheckLeftRight_stat_Spare" 4 "LampCheckLeftRight_stat_TestedLeftAndRightLampNOK" 3 "LampCheckLeftRight_stat_TestedRightLampNOK" 2 "LampCheckLeftRight_stat_TestedLeftLampNOK" 1 "LampCheckLeftRight_stat_TestedLampOK" 0 "LampCheckLeftRight_stat_NotTested" ;
VAL_ 867 DippedBeamLamp_stat_ISig_5 7 "LampCheckLeftRight_stat_NotAvailable" 6 "LampCheckLeftRight_stat_Error" 5 "LampCheckLeftRight_stat_Spare" 4 "LampCheckLeftRight_stat_TestedLeftAndRightLampNOK" 3 "LampCheckLeftRight_stat_TestedRightLampNOK" 2 "LampCheckLeftRight_stat_TestedLeftLampNOK" 1 "LampCheckLeftRight_stat_TestedLampOK" 0 "LampCheckLeftRight_stat_NotTested" ;
VAL_ 867 ChassiInstepLightsLamp_stat_ISig 7 "LampCheck_stat_NotAvailable" 6 "LampCheck_stat_Error" 5 "LampCheck_stat_Spare_02" 4 "LampCheck_stat_Spare_01" 3 "LampCheck_stat_Spare" 2 "LampCheck_stat_TestedLampNOK" 1 "LampCheck_stat_TestedLampOK" 0 "LampCheck_stat_NotTested" ;
VAL_ 867 DRLLamp_stat_ISig_5 7 "LampCheckLeftRight_stat_NotAvailable" 6 "LampCheckLeftRight_stat_Error" 5 "LampCheckLeftRight_stat_Spare" 4 "LampCheckLeftRight_stat_TestedLeftAndRightLampNOK" 3 "LampCheckLeftRight_stat_TestedRightLampNOK" 2 "LampCheckLeftRight_stat_TestedLeftLampNOK" 1 "LampCheckLeftRight_stat_TestedLampOK" 0 "LampCheckLeftRight_stat_NotTested" ;
VAL_ 867 TrailerDirIndRightOutputStat_ISi 7 "TrailerLightOutputStat_NotAvailable" 6 "TrailerLightOutputStat_Error" 5 "TrailerLightOutputStat_OutputActiveStatusUncertain" 4 "TrailerLightOutputStat_OutputActiveLightDetectedOnActivation" 3 "TrailerLightOutputStat_OutputActiveLightDetected" 2 "TrailerLightOutputStat_OutputActiveNoLightDetected" 1 "TrailerLightOutputStat_OutputActiveDetectionOngoing" 0 "TrailerLightOutputStat_OutputInactive" ;
VAL_ 867 HeadlampFan_stat_ISig_5 7 "LampFanTestStat_NotAvailable" 6 "LampFanTestStat_Error" 5 "LampFanTestStat_Spare3" 4 "LampFanTestStat_Spare2" 3 "LampFanTestStat_Spare1" 2 "LampFanTestStat_FanTestedNOK" 1 "LampFanTestStat_FanTestedOK" 0 "LampFanTestStat_NotTested" ;
VAL_ 867 MainBeamLamp_stat_ISig_5 7 "LampCheckLeftRight_stat_NotAvailable" 6 "LampCheckLeftRight_stat_Error" 5 "LampCheckLeftRight_stat_Spare" 4 "LampCheckLeftRight_stat_TestedLeftAndRightLampNOK" 3 "LampCheckLeftRight_stat_TestedRightLampNOK" 2 "LampCheckLeftRight_stat_TestedLeftLampNOK" 1 "LampCheckLeftRight_stat_TestedLampOK" 0 "LampCheckLeftRight_stat_NotTested" ;
VAL_ 867 StaticCornerLightLamp_stat_ISig_ 7 "LampCheckLeftRight_stat_NotAvailable" 6 "LampCheckLeftRight_stat_Error" 5 "LampCheckLeftRight_stat_Spare" 4 "LampCheckLeftRight_stat_TestedLeftAndRightLampNOK" 3 "LampCheckLeftRight_stat_TestedRightLampNOK" 2 "LampCheckLeftRight_stat_TestedLeftLampNOK" 1 "LampCheckLeftRight_stat_TestedLampOK" 0 "LampCheckLeftRight_stat_NotTested" ;
VAL_ 867 AuxFogLightLamp_stat_ISig_5 7 "LampCheckLeftRight_stat_NotAvailable" 6 "LampCheckLeftRight_stat_Error" 5 "LampCheckLeftRight_stat_Spare" 4 "LampCheckLeftRight_stat_TestedLeftAndRightLampNOK" 3 "LampCheckLeftRight_stat_TestedRightLampNOK" 2 "LampCheckLeftRight_stat_TestedLeftLampNOK" 1 "LampCheckLeftRight_stat_TestedLampOK" 0 "LampCheckLeftRight_stat_NotTested" ;
VAL_ 867 PositionLightLamp_stat_ISig_5 7 "LampCheckLeftRight_stat_NotAvailable" 6 "LampCheckLeftRight_stat_Error" 5 "LampCheckLeftRight_stat_Spare" 4 "LampCheckLeftRight_stat_TestedLeftAndRightLampNOK" 3 "LampCheckLeftRight_stat_TestedRightLampNOK" 2 "LampCheckLeftRight_stat_TestedLeftLampNOK" 1 "LampCheckLeftRight_stat_TestedLampOK" 0 "LampCheckLeftRight_stat_NotTested" ;
VAL_ 866 LoadDistributionSelected2_ISig_5 15 "LoadDistributionSelected2_NotAvailable" 14 "LoadDistributionSelected2_Error" 13 "LoadDistributionSelected2_Reserved_01" 12 "LoadDistributionSelected2_TractionHelp2InterDiff" 11 "LoadDistributionSelected2_StartingHelp2InterDiff" 10 "LoadDistributionSelected2_TractionHelp2" 9 "LoadDistributionSelected2_StartingHelp2" 8 "LoadDistributionSelected2_VariableAxleLoad" 7 "LoadDistributionSelected2_NoLoadDistribution" 6 "LoadDistributionSelected2_TractionHelpInterDiff" 5 "LoadDistributionSelected2_StartingHelpInterDiff" 4 "LoadDistributionSelected2_AlternativeLoad" 3 "LoadDistributionSelected2_TractionHelp" 2 "LoadDistributionSelected2_StartingHelp" 1 "LoadDistributionSelected2_OptimisedTraction" 0 "LoadDistributionSelected2_NormalLoad" ;
VAL_ 865 DayOfWeek_stat 15 "DayOfWeek_NotAvailable" 14 "DayOfWeek_Error" 13 "DayOfWeek_Spare_7" 12 "DayOfWeek_Spare_6" 11 "DayOfWeek_Spare_5" 10 "DayOfWeek_Spare_4" 9 "DayOfWeek_Spare_3" 8 "DayOfWeek_Spare_2" 7 "DayOfWeek_Spare_1" 6 "DayOfWeek_Sunday" 5 "DayOfWeek_Saturday" 4 "DayOfWeek_Friday" 3 "DayOfWeek_Thursday" 2 "DayOfWeek_Wednesday" 1 "DayOfWeek_Tuesday" 0 "DayOfWeek_Monday" ;
VAL_ 696 TrailerStatus_IntegrityLvl_ISig_ 3 "IntegrityLvl_HighIntegrity" 2 "IntegrityLvl_Spare" 1 "IntegrityLvl_LowIntegrity" 0 "IntegrityLvl_Downgraded" ;
VAL_ 696 RedGladHand_ConfidenceLvl_ISig_5 3 "LowHigh_NotAvailable" 2 "LowHigh_Error" 1 "LowHigh_High" 0 "LowHigh_Low" ;
VAL_ 696 TrailerStatus_Actuation_ISig_5 7 "TrailerStatusActuation_NotAvailable" 6 "TrailerStatusActuation_Error" 5 "TrailerStatusActuation_Spare3" 4 "TrailerStatusActuation_Spare2" 3 "TrailerStatusActuation_Spare1" 2 "TrailerStatusActuation_Deflated" 1 "TrailerStatusActuation_Intermediate" 0 "TrailerStatusActuation_Inflated" ;
VAL_ 696 RedGladHand_ConnectStatus_ISig_5 3 "TLConnectStatus_NotAvailable" 2 "TLConnectStatus_Unknown" 1 "TLConnectStatus_Attached" 0 "TLConnectStatus_Detached" ;
VAL_ 695 TrafficSitPathEvent2_Type 255 "TrafficSitEventType_NotAvailable" 254 "TrafficSitEventType_Error" 253 "TrafficSitEventType_NotUsed3" 252 "TrafficSitEventType_NotUsed2" 251 "TrafficSitEventType_NotUsed1" 250 "TrafficSitEventType_GeneralEvent" 249 "TrafficSitEventType_spare242" 248 "TrafficSitEventType_spare241" 247 "TrafficSitEventType_spare240" 246 "TrafficSitEventType_spare239" 245 "TrafficSitEventType_spare238" 244 "TrafficSitEventType_spare237" 243 "TrafficSitEventType_spare236" 242 "TrafficSitEventType_spare235" 241 "TrafficSitEventType_spare234" 240 "TrafficSitEventType_spare233" 239 "TrafficSitEventType_spare232" 238 "TrafficSitEventType_spare231" 237 "TrafficSitEventType_spare230" 236 "TrafficSitEventType_spare229" 235 "TrafficSitEventType_spare228" 234 "TrafficSitEventType_spare227" 233 "TrafficSitEventType_spare226" 232 "TrafficSitEventType_spare225" 231 "TrafficSitEventType_spare224" 230 "TrafficSitEventType_spare223" 229 "TrafficSitEventType_spare222" 228 "TrafficSitEventType_spare221" 227 "TrafficSitEventType_spare220" 226 "TrafficSitEventType_spare219" 225 "TrafficSitEventType_spare218" 224 "TrafficSitEventType_spare217" 223 "TrafficSitEventType_spare216" 222 "TrafficSitEventType_spare215" 221 "TrafficSitEventType_spare214" 220 "TrafficSitEventType_spare213" 219 "TrafficSitEventType_spare212" 218 "TrafficSitEventType_spare211" 217 "TrafficSitEventType_spare210" 216 "TrafficSitEventType_spare209" 215 "TrafficSitEventType_spare208" 214 "TrafficSitEventType_spare207" 213 "TrafficSitEventType_spare206" 212 "TrafficSitEventType_spare205" 211 "TrafficSitEventType_spare204" 210 "TrafficSitEventType_spare203" 209 "TrafficSitEventType_spare202" 208 "TrafficSitEventType_spare201" 207 "TrafficSitEventType_spare200" 206 "TrafficSitEventType_spare199" 205 "TrafficSitEventType_spare198" 204 "TrafficSitEventType_spare197" 203 "TrafficSitEventType_spare196" 202 "TrafficSitEventType_spare195" 201 "TrafficSitEventType_spare194" 200 "TrafficSitEventType_spare193" 199 "TrafficSitEventType_spare192" 198 "TrafficSitEventType_spare191" 197 "TrafficSitEventType_spare190" 196 "TrafficSitEventType_spare189" 195 "TrafficSitEventType_spare188" 194 "TrafficSitEventType_spare187" 193 "TrafficSitEventType_spare186" 192 "TrafficSitEventType_spare185" 191 "TrafficSitEventType_spare184" 190 "TrafficSitEventType_spare183" 189 "TrafficSitEventType_spare182" 188 "TrafficSitEventType_spare181" 187 "TrafficSitEventType_spare180" 186 "TrafficSitEventType_spare179" 185 "TrafficSitEventType_spare178" 184 "TrafficSitEventType_spare177" 183 "TrafficSitEventType_spare176" 182 "TrafficSitEventType_spare175" 181 "TrafficSitEventType_spare174" 180 "TrafficSitEventType_spare173" 179 "TrafficSitEventType_spare172" 178 "TrafficSitEventType_spare171" 177 "TrafficSitEventType_spare170" 176 "TrafficSitEventType_spare169" 175 "TrafficSitEventType_spare168" 174 "TrafficSitEventType_spare167" 173 "TrafficSitEventType_spare166" 172 "TrafficSitEventType_spare165" 171 "TrafficSitEventType_spare164" 170 "TrafficSitEventType_spare163" 169 "TrafficSitEventType_spare162" 168 "TrafficSitEventType_spare161" 167 "TrafficSitEventType_spare160" 166 "TrafficSitEventType_spare159" 165 "TrafficSitEventType_spare158" 164 "TrafficSitEventType_spare157" 163 "TrafficSitEventType_spare156" 162 "TrafficSitEventType_spare155" 161 "TrafficSitEventType_spare154" 160 "TrafficSitEventType_spare153" 159 "TrafficSitEventType_spare152" 158 "TrafficSitEventType_spare151" 157 "TrafficSitEventType_spare150" 156 "TrafficSitEventType_spare149" 155 "TrafficSitEventType_spare148" 154 "TrafficSitEventType_spare147" 153 "TrafficSitEventType_spare146" 152 "TrafficSitEventType_spare145" 151 "TrafficSitEventType_spare144" 150 "TrafficSitEventType_spare143" 149 "TrafficSitEventType_spare142" 148 "TrafficSitEventType_spare141" 147 "TrafficSitEventType_spare140" 146 "TrafficSitEventType_spare139" 145 "TrafficSitEventType_spare138" 144 "TrafficSitEventType_spare137" 143 "TrafficSitEventType_spare136" 142 "TrafficSitEventType_spare135" 141 "TrafficSitEventType_spare134" 140 "TrafficSitEventType_spare133" 139 "TrafficSitEventType_spare132" 138 "TrafficSitEventType_spare131" 137 "TrafficSitEventType_spare130" 136 "TrafficSitEventType_spare129" 135 "TrafficSitEventType_spare128" 134 "TrafficSitEventType_spare127" 133 "TrafficSitEventType_spare126" 132 "TrafficSitEventType_spare125" 131 "TrafficSitEventType_spare124" 130 "TrafficSitEventType_spare123" 129 "TrafficSitEventType_spare122" 128 "TrafficSitEventType_spare121" 127 "TrafficSitEventType_spare120" 126 "TrafficSitEventType_spare119" 125 "TrafficSitEventType_spare118" 124 "TrafficSitEventType_spare117" 123 "TrafficSitEventType_spare116" 122 "TrafficSitEventType_spare115" 121 "TrafficSitEventType_spare114" 120 "TrafficSitEventType_spare113" 119 "TrafficSitEventType_spare112" 118 "TrafficSitEventType_spare111" 117 "TrafficSitEventType_spare110" 116 "TrafficSitEventType_spare109" 115 "TrafficSitEventType_spare108" 114 "TrafficSitEventType_spare107" 113 "TrafficSitEventType_spare106" 112 "TrafficSitEventType_spare105" 111 "TrafficSitEventType_spare104" 110 "TrafficSitEventType_spare103" 109 "TrafficSitEventType_spare102" 108 "TrafficSitEventType_spare101" 107 "TrafficSitEventType_spare100" 106 "TrafficSitEventType_spare99" 105 "TrafficSitEventType_spare98" 104 "TrafficSitEventType_spare97" 103 "TrafficSitEventType_spare96" 102 "TrafficSitEventType_spare95" 101 "TrafficSitEventType_spare94" 100 "TrafficSitEventType_spare93" 99 "TrafficSitEventType_spare92" 98 "TrafficSitEventType_spare91" 97 "TrafficSitEventType_spare90" 96 "TrafficSitEventType_spare89" 95 "TrafficSitEventType_spare88" 94 "TrafficSitEventType_spare87" 93 "TrafficSitEventType_spare86" 92 "TrafficSitEventType_spare85" 91 "TrafficSitEventType_spare84" 90 "TrafficSitEventType_spare83" 89 "TrafficSitEventType_spare82" 88 "TrafficSitEventType_spare81" 87 "TrafficSitEventType_spare80" 86 "TrafficSitEventType_spare79" 85 "TrafficSitEventType_spare78" 84 "TrafficSitEventType_spare77" 83 "TrafficSitEventType_spare76" 82 "TrafficSitEventType_spare75" 81 "TrafficSitEventType_spare74" 80 "TrafficSitEventType_spare73" 79 "TrafficSitEventType_spare72" 78 "TrafficSitEventType_spare71" 77 "TrafficSitEventType_spare70" 76 "TrafficSitEventType_spare69" 75 "TrafficSitEventType_spare68" 74 "TrafficSitEventType_spare67" 73 "TrafficSitEventType_spare66" 72 "TrafficSitEventType_spare65" 71 "TrafficSitEventType_spare64" 70 "TrafficSitEventType_spare63" 69 "TrafficSitEventType_spare62" 68 "TrafficSitEventType_spare61" 67 "TrafficSitEventType_spare60" 66 "TrafficSitEventType_spare59" 65 "TrafficSitEventType_spare58" 64 "TrafficSitEventType_spare57" 63 "TrafficSitEventType_spare56" 62 "TrafficSitEventType_spare55" 61 "TrafficSitEventType_spare54" 60 "TrafficSitEventType_spare53" 59 "TrafficSitEventType_spare52" 58 "TrafficSitEventType_spare51" 57 "TrafficSitEventType_spare50" 56 "TrafficSitEventType_spare49" 55 "TrafficSitEventType_spare48" 54 "TrafficSitEventType_spare47" 53 "TrafficSitEventType_spare46" 52 "TrafficSitEventType_spare45" 51 "TrafficSitEventType_spare44" 50 "TrafficSitEventType_spare43" 49 "TrafficSitEventType_spare42" 48 "TrafficSitEventType_spare41" 47 "TrafficSitEventType_spare40" 46 "TrafficSitEventType_spare39" 45 "TrafficSitEventType_spare38" 44 "TrafficSitEventType_spare37" 43 "TrafficSitEventType_spare36" 42 "TrafficSitEventType_spare35" 41 "TrafficSitEventType_spare34" 40 "TrafficSitEventType_spare33" 39 "TrafficSitEventType_spare32" 38 "TrafficSitEventType_spare31" 37 "TrafficSitEventType_spare30" 36 "TrafficSitEventType_spare29" 35 "TrafficSitEventType_spare28" 34 "TrafficSitEventType_spare27" 33 "TrafficSitEventType_spare26" 32 "TrafficSitEventType_spare25" 31 "TrafficSitEventType_spare24" 30 "TrafficSitEventType_spare23" 29 "TrafficSitEventType_spare22" 28 "TrafficSitEventType_spare21" 27 "TrafficSitEventType_spare20" 26 "TrafficSitEventType_spare19" 25 "TrafficSitEventType_spare18" 24 "TrafficSitEventType_spare17" 23 "TrafficSitEventType_spare16" 22 "TrafficSitEventType_spare15" 21 "TrafficSitEventType_spare14" 20 "TrafficSitEventType_spare13" 19 "TrafficSitEventType_spare12" 18 "TrafficSitEventType_spare11" 17 "TrafficSitEventType_spare10" 16 "TrafficSitEventType_spare9" 15 "TrafficSitEventType_spare8" 14 "TrafficSitEventType_spare7" 13 "TrafficSitEventType_spare6" 12 "TrafficSitEventType_spare5" 11 "TrafficSitEventType_spare4" 10 "TrafficSitEventType_spare3" 9 "TrafficSitEventType_spare2" 8 "TrafficSitEventType_spare1" 7 "TrafficSitEventType_NarrowRoad" 6 "TrafficSitEventType_TrafficJam_OR_SlowTraffic" 5 "TrafficSitEventType_Crossing" 4 "TrafficSitEventType_Roundabout" 3 "TrafficSitEventType_CurveRight" 2 "TrafficSitEventType_CurveLeft" 1 "TrafficSitEventType_SpeedLimit" 0 "TrafficSitEventType_NoEvent" ;
VAL_ 695 TrafficSitPathEvent1_Type 255 "TrafficSitEventType_NotAvailable" 254 "TrafficSitEventType_Error" 253 "TrafficSitEventType_NotUsed3" 252 "TrafficSitEventType_NotUsed2" 251 "TrafficSitEventType_NotUsed1" 250 "TrafficSitEventType_GeneralEvent" 249 "TrafficSitEventType_spare242" 248 "TrafficSitEventType_spare241" 247 "TrafficSitEventType_spare240" 246 "TrafficSitEventType_spare239" 245 "TrafficSitEventType_spare238" 244 "TrafficSitEventType_spare237" 243 "TrafficSitEventType_spare236" 242 "TrafficSitEventType_spare235" 241 "TrafficSitEventType_spare234" 240 "TrafficSitEventType_spare233" 239 "TrafficSitEventType_spare232" 238 "TrafficSitEventType_spare231" 237 "TrafficSitEventType_spare230" 236 "TrafficSitEventType_spare229" 235 "TrafficSitEventType_spare228" 234 "TrafficSitEventType_spare227" 233 "TrafficSitEventType_spare226" 232 "TrafficSitEventType_spare225" 231 "TrafficSitEventType_spare224" 230 "TrafficSitEventType_spare223" 229 "TrafficSitEventType_spare222" 228 "TrafficSitEventType_spare221" 227 "TrafficSitEventType_spare220" 226 "TrafficSitEventType_spare219" 225 "TrafficSitEventType_spare218" 224 "TrafficSitEventType_spare217" 223 "TrafficSitEventType_spare216" 222 "TrafficSitEventType_spare215" 221 "TrafficSitEventType_spare214" 220 "TrafficSitEventType_spare213" 219 "TrafficSitEventType_spare212" 218 "TrafficSitEventType_spare211" 217 "TrafficSitEventType_spare210" 216 "TrafficSitEventType_spare209" 215 "TrafficSitEventType_spare208" 214 "TrafficSitEventType_spare207" 213 "TrafficSitEventType_spare206" 212 "TrafficSitEventType_spare205" 211 "TrafficSitEventType_spare204" 210 "TrafficSitEventType_spare203" 209 "TrafficSitEventType_spare202" 208 "TrafficSitEventType_spare201" 207 "TrafficSitEventType_spare200" 206 "TrafficSitEventType_spare199" 205 "TrafficSitEventType_spare198" 204 "TrafficSitEventType_spare197" 203 "TrafficSitEventType_spare196" 202 "TrafficSitEventType_spare195" 201 "TrafficSitEventType_spare194" 200 "TrafficSitEventType_spare193" 199 "TrafficSitEventType_spare192" 198 "TrafficSitEventType_spare191" 197 "TrafficSitEventType_spare190" 196 "TrafficSitEventType_spare189" 195 "TrafficSitEventType_spare188" 194 "TrafficSitEventType_spare187" 193 "TrafficSitEventType_spare186" 192 "TrafficSitEventType_spare185" 191 "TrafficSitEventType_spare184" 190 "TrafficSitEventType_spare183" 189 "TrafficSitEventType_spare182" 188 "TrafficSitEventType_spare181" 187 "TrafficSitEventType_spare180" 186 "TrafficSitEventType_spare179" 185 "TrafficSitEventType_spare178" 184 "TrafficSitEventType_spare177" 183 "TrafficSitEventType_spare176" 182 "TrafficSitEventType_spare175" 181 "TrafficSitEventType_spare174" 180 "TrafficSitEventType_spare173" 179 "TrafficSitEventType_spare172" 178 "TrafficSitEventType_spare171" 177 "TrafficSitEventType_spare170" 176 "TrafficSitEventType_spare169" 175 "TrafficSitEventType_spare168" 174 "TrafficSitEventType_spare167" 173 "TrafficSitEventType_spare166" 172 "TrafficSitEventType_spare165" 171 "TrafficSitEventType_spare164" 170 "TrafficSitEventType_spare163" 169 "TrafficSitEventType_spare162" 168 "TrafficSitEventType_spare161" 167 "TrafficSitEventType_spare160" 166 "TrafficSitEventType_spare159" 165 "TrafficSitEventType_spare158" 164 "TrafficSitEventType_spare157" 163 "TrafficSitEventType_spare156" 162 "TrafficSitEventType_spare155" 161 "TrafficSitEventType_spare154" 160 "TrafficSitEventType_spare153" 159 "TrafficSitEventType_spare152" 158 "TrafficSitEventType_spare151" 157 "TrafficSitEventType_spare150" 156 "TrafficSitEventType_spare149" 155 "TrafficSitEventType_spare148" 154 "TrafficSitEventType_spare147" 153 "TrafficSitEventType_spare146" 152 "TrafficSitEventType_spare145" 151 "TrafficSitEventType_spare144" 150 "TrafficSitEventType_spare143" 149 "TrafficSitEventType_spare142" 148 "TrafficSitEventType_spare141" 147 "TrafficSitEventType_spare140" 146 "TrafficSitEventType_spare139" 145 "TrafficSitEventType_spare138" 144 "TrafficSitEventType_spare137" 143 "TrafficSitEventType_spare136" 142 "TrafficSitEventType_spare135" 141 "TrafficSitEventType_spare134" 140 "TrafficSitEventType_spare133" 139 "TrafficSitEventType_spare132" 138 "TrafficSitEventType_spare131" 137 "TrafficSitEventType_spare130" 136 "TrafficSitEventType_spare129" 135 "TrafficSitEventType_spare128" 134 "TrafficSitEventType_spare127" 133 "TrafficSitEventType_spare126" 132 "TrafficSitEventType_spare125" 131 "TrafficSitEventType_spare124" 130 "TrafficSitEventType_spare123" 129 "TrafficSitEventType_spare122" 128 "TrafficSitEventType_spare121" 127 "TrafficSitEventType_spare120" 126 "TrafficSitEventType_spare119" 125 "TrafficSitEventType_spare118" 124 "TrafficSitEventType_spare117" 123 "TrafficSitEventType_spare116" 122 "TrafficSitEventType_spare115" 121 "TrafficSitEventType_spare114" 120 "TrafficSitEventType_spare113" 119 "TrafficSitEventType_spare112" 118 "TrafficSitEventType_spare111" 117 "TrafficSitEventType_spare110" 116 "TrafficSitEventType_spare109" 115 "TrafficSitEventType_spare108" 114 "TrafficSitEventType_spare107" 113 "TrafficSitEventType_spare106" 112 "TrafficSitEventType_spare105" 111 "TrafficSitEventType_spare104" 110 "TrafficSitEventType_spare103" 109 "TrafficSitEventType_spare102" 108 "TrafficSitEventType_spare101" 107 "TrafficSitEventType_spare100" 106 "TrafficSitEventType_spare99" 105 "TrafficSitEventType_spare98" 104 "TrafficSitEventType_spare97" 103 "TrafficSitEventType_spare96" 102 "TrafficSitEventType_spare95" 101 "TrafficSitEventType_spare94" 100 "TrafficSitEventType_spare93" 99 "TrafficSitEventType_spare92" 98 "TrafficSitEventType_spare91" 97 "TrafficSitEventType_spare90" 96 "TrafficSitEventType_spare89" 95 "TrafficSitEventType_spare88" 94 "TrafficSitEventType_spare87" 93 "TrafficSitEventType_spare86" 92 "TrafficSitEventType_spare85" 91 "TrafficSitEventType_spare84" 90 "TrafficSitEventType_spare83" 89 "TrafficSitEventType_spare82" 88 "TrafficSitEventType_spare81" 87 "TrafficSitEventType_spare80" 86 "TrafficSitEventType_spare79" 85 "TrafficSitEventType_spare78" 84 "TrafficSitEventType_spare77" 83 "TrafficSitEventType_spare76" 82 "TrafficSitEventType_spare75" 81 "TrafficSitEventType_spare74" 80 "TrafficSitEventType_spare73" 79 "TrafficSitEventType_spare72" 78 "TrafficSitEventType_spare71" 77 "TrafficSitEventType_spare70" 76 "TrafficSitEventType_spare69" 75 "TrafficSitEventType_spare68" 74 "TrafficSitEventType_spare67" 73 "TrafficSitEventType_spare66" 72 "TrafficSitEventType_spare65" 71 "TrafficSitEventType_spare64" 70 "TrafficSitEventType_spare63" 69 "TrafficSitEventType_spare62" 68 "TrafficSitEventType_spare61" 67 "TrafficSitEventType_spare60" 66 "TrafficSitEventType_spare59" 65 "TrafficSitEventType_spare58" 64 "TrafficSitEventType_spare57" 63 "TrafficSitEventType_spare56" 62 "TrafficSitEventType_spare55" 61 "TrafficSitEventType_spare54" 60 "TrafficSitEventType_spare53" 59 "TrafficSitEventType_spare52" 58 "TrafficSitEventType_spare51" 57 "TrafficSitEventType_spare50" 56 "TrafficSitEventType_spare49" 55 "TrafficSitEventType_spare48" 54 "TrafficSitEventType_spare47" 53 "TrafficSitEventType_spare46" 52 "TrafficSitEventType_spare45" 51 "TrafficSitEventType_spare44" 50 "TrafficSitEventType_spare43" 49 "TrafficSitEventType_spare42" 48 "TrafficSitEventType_spare41" 47 "TrafficSitEventType_spare40" 46 "TrafficSitEventType_spare39" 45 "TrafficSitEventType_spare38" 44 "TrafficSitEventType_spare37" 43 "TrafficSitEventType_spare36" 42 "TrafficSitEventType_spare35" 41 "TrafficSitEventType_spare34" 40 "TrafficSitEventType_spare33" 39 "TrafficSitEventType_spare32" 38 "TrafficSitEventType_spare31" 37 "TrafficSitEventType_spare30" 36 "TrafficSitEventType_spare29" 35 "TrafficSitEventType_spare28" 34 "TrafficSitEventType_spare27" 33 "TrafficSitEventType_spare26" 32 "TrafficSitEventType_spare25" 31 "TrafficSitEventType_spare24" 30 "TrafficSitEventType_spare23" 29 "TrafficSitEventType_spare22" 28 "TrafficSitEventType_spare21" 27 "TrafficSitEventType_spare20" 26 "TrafficSitEventType_spare19" 25 "TrafficSitEventType_spare18" 24 "TrafficSitEventType_spare17" 23 "TrafficSitEventType_spare16" 22 "TrafficSitEventType_spare15" 21 "TrafficSitEventType_spare14" 20 "TrafficSitEventType_spare13" 19 "TrafficSitEventType_spare12" 18 "TrafficSitEventType_spare11" 17 "TrafficSitEventType_spare10" 16 "TrafficSitEventType_spare9" 15 "TrafficSitEventType_spare8" 14 "TrafficSitEventType_spare7" 13 "TrafficSitEventType_spare6" 12 "TrafficSitEventType_spare5" 11 "TrafficSitEventType_spare4" 10 "TrafficSitEventType_spare3" 9 "TrafficSitEventType_spare2" 8 "TrafficSitEventType_spare1" 7 "TrafficSitEventType_NarrowRoad" 6 "TrafficSitEventType_TrafficJam_OR_SlowTraffic" 5 "TrafficSitEventType_Crossing" 4 "TrafficSitEventType_Roundabout" 3 "TrafficSitEventType_CurveRight" 2 "TrafficSitEventType_CurveLeft" 1 "TrafficSitEventType_SpeedLimit" 0 "TrafficSitEventType_NoEvent" ;
VAL_ 694 BatteryCapacity_ISig_5 15 "BatteryType_NotAvailable" 14 "BatteryType_Error" 13 "BatteryType_NoSelectionMade" 12 "BatteryType_OtherBatteryType" 11 "BatteryType_BatteryType11" 10 "BatteryType_BatteryType10" 9 "BatteryType_BatteryType9" 8 "BatteryType_BatteryType8" 7 "BatteryType_BatteryType7" 6 "BatteryType_BatteryType6" 5 "BatteryType_BatteryType5" 4 "BatteryType_BatteryType4" 3 "BatteryType_BatteryType3" 2 "BatteryType_BatteryType2" 1 "BatteryType_BatteryType1" 0 "BatteryType_BatteryType0" ;
VAL_ 694 LivBatteryCharging_stat_ISig_5 3 "NotConfirmedConfirmed_NotAvailable" 2 "NotConfirmedConfirmed_Error" 1 "NotConfirmedConfirmed_Confirmed" 0 "NotConfirmedConfirmed_NotConfirmed" ;
VAL_ 691 DirectionIndicatorLightsStatus_I 15 "DirectionIndicatorLightsStatus_NotAvailable" 14 "DirectionIndicatorLightsStatus_Error" 13 "DirectionIndicatorLightsStatus_Spare7" 12 "DirectionIndicatorLightsStatus_Spare6" 11 "DirectionIndicatorLightsStatus_Spare5" 10 "DirectionIndicatorLightsStatus_Spare4" 9 "DirectionIndicatorLightsStatus_Spare3" 8 "DirectionIndicatorLightsStatus_Spare2" 7 "DirectionIndicatorLightsStatus_Spare1" 6 "DirectionIndicatorLightsStatus_ActiveOtherIndication" 5 "DirectionIndicatorLightsStatus_ActiveHazard" 4 "DirectionIndicatorLightsStatus_ActiveRightAndHazard" 3 "DirectionIndicatorLightsStatus_ActiveLeftAndHazard" 2 "DirectionIndicatorLightsStatus_ActiveRight" 1 "DirectionIndicatorLightsStatus_ActiveLeft" 0 "DirectionIndicatorLightsStatus_NotActive" ;
VAL_ 691 ACC_SGO_Status_ISig_5 15 "ACC_SGO_Status_NotAvailable" 14 "ACC_SGO_Status_Error" 13 "ACC_SGO_Status_Spare7" 12 "ACC_SGO_Status_Spare6" 11 "ACC_SGO_Status_Spare5" 10 "ACC_SGO_Status_Spare4" 9 "ACC_SGO_Status_Spare3" 8 "ACC_SGO_Status_Spare2" 7 "ACC_SGO_Status_Spare1" 6 "ACC_SGO_Status_ACC_SGO_Active_TakeOffRequest" 5 "ACC_SGO_Status_ACC_SGO_Active_Hold" 4 "ACC_SGO_Status_ACC_SGO_Active_Stationary" 3 "ACC_SGO_Status_ACC_SGO_Stopping" 2 "ACC_SGO_Status_ACC_SGO_Active_Driving" 1 "ACC_SGO_Status_ACC_SGO_Inactive" 0 "ACC_SGO_Status_ACC_SGO_OFF" ;
VAL_ 691 BatteryEndOfChargeLSB_ISig_5 3 "FalseTrue_NotAvaiable" 2 "FalseTrue_Error" 1 "FalseTrue_True" 0 "FalseTrue_False" ;
VAL_ 691 BatteryEndOfChargeHSB_ISig_5 3 "FalseTrue_NotAvaiable" 2 "FalseTrue_Error" 1 "FalseTrue_True" 0 "FalseTrue_False" ;
VAL_ 691 SensorCleaningFluidLevelStatus_I 7 "FluidLevel_NotAvailable" 6 "FluidLevel_Error" 5 "FluidLevel_Spare3" 4 "FluidLevel_Spare2" 3 "FluidLevel_Spare1" 2 "FluidLevel_CriticallyLow" 1 "FluidLevel_Low" 0 "FluidLevel_LevelOK" ;
VAL_ 690 SetHSAOperation_ISig_5 7 "SetHSAOperation_NotAvailable" 6 "SetHSAOperation_Error" 5 "SetHSAOperation_Spare2" 4 "SetHSAOperation_Spare1" 3 "SetHSAOperation_Forbid_HSA_WithCaution" 2 "SetHSAOperation_Forbid_HSA_Activation" 1 "SetHSAOperation_Allow_HSA_WithCaution" 0 "SetHSAOperation_Allow_HSA_Activation" ;
VAL_ 690 PS_FogLightFront 3 "InactiveActiveSpare_NotAvailable" 2 "InactiveActiveSpare_Spare" 1 "InactiveActiveSpare_Active" 0 "InactiveActiveSpare_Inactive" ;
VAL_ 690 CACCStatus_ISig_5 7 "CACCStatus_NotAvailable" 6 "CACCStatus_Error" 5 "CACCStatus_Spare3" 4 "CACCStatus_Spare2" 3 "CACCStatus_Spare1" 2 "CACCStatus_Active" 1 "CACCStatus_Available" 0 "CACCStatus_Unavailable" ;
VAL_ 690 Cab12VSupplyStatus_ISig_5 3 "Cab12VSupplyStatus_NotAvailable" 2 "Cab12VSupplyStatus_Error" 1 "Cab12VSupplyStatus_CabSupplyError" 0 "Cab12VSupplyStatus_OK" ;
VAL_ 690 TransmissionDrivingMode_ISig_5 7 "TransmissionDrivingMode_NotAvailable" 6 "TransmissionDrivingMode_KickDown" 5 "TransmissionDrivingMode_Dynamometer" 4 "TransmissionDrivingMode_HeavyDuty" 3 "TransmissionDrivingMode_OffRoad" 2 "TransmissionDrivingMode_Performance" 1 "TransmissionDrivingMode_Balanced_Standard" 0 "TransmissionDrivingMode_EconomyExtra_Range" ;
VAL_ 690 LowAirPressureAlert_ISig_5 3 "LowAirPressureAlert_NotAvailable" 2 "LowAirPressureAlert_Error" 1 "LowAirPressureAlert_LowPressure" 0 "LowAirPressureAlert_NormalPressure" ;
VAL_ 690 TemporaryRSLSwitchStatus 3 "A2PosSwitchStatus_NotAvailable" 2 "A2PosSwitchStatus_Error" 1 "A2PosSwitchStatus_On" 0 "A2PosSwitchStatus_Off" ;
VAL_ 690 BatterySOCAlertRawData_rqst_ISig 7 "BatterySOCAlert_rqst_NotAvailable" 6 "BatterySOCAlert_rqst_ErrorIndicator" 5 "BatterySOCAlert_rqst_SpareValue_02" 4 "BatterySOCAlert_rqst_SpareValue_01" 3 "BatterySOCAlert_rqst_SpareValue" 2 "BatterySOCAlert_rqst_CriticalAlert" 1 "BatterySOCAlert_rqst_PreAlert" 0 "BatterySOCAlert_rqst_NoAlertRequested" ;
VAL_ 690 BatteryTempAlertRawData_rqst_ISi 7 "BatteryTempAlert_rqst_NotAvailable" 6 "BatteryTempAlert_rqst_Error" 5 "BatteryTempAlert_rqst_Spare3" 4 "BatteryTempAlert_rqst_Spare2" 3 "BatteryTempAlert_rqst_Spare1" 2 "BatteryTempAlert_rqst_CriticalAlertLowTemp" 1 "BatteryTempAlert_rqst_PreAlertLowTemp" 0 "BatteryTempAlert_rqst_NoAlertRequested" ;
VAL_ 690 BrakeTemperatureWarning_ISig_5 3 "Warning_NotAvailable" 2 "Warning_Error" 1 "Warning_Warning" 0 "Warning_NoWarning" ;
VAL_ 690 WheelSlipControllerMode_ISig_5 7 "WheelSlipCntrlMode_NotAvailable" 6 "WheelSlipCntrlMode_Error" 5 "WheelSlipCntrlMode_Spare2" 4 "WheelSlipCntrlMode_Spare1" 3 "WheelSlipCntrlMode_Disabled" 2 "WheelSlipCntrlMode_EnabledActiveBrakingSlipCntrl" 1 "WheelSlipCntrlMode_EnabledActiveTractionSlipCntrl" 0 "WheelSlipCntrlMode_EnabledPassive" ;
VAL_ 690 Rainsensor_Indication_ISig_5 3 "DeviceIndication_SpareValue" 2 "DeviceIndication_Blink" 1 "DeviceIndication_On" 0 "DeviceIndication_Off" ;
VAL_ 690 ESCHealthStatus_ISig_5 3 "OffOnSpare_NotAvailable" 2 "OffOnSpare_Spare" 1 "OffOnSpare_On" 0 "OffOnSpare_Off" ;
VAL_ 690 TLInflationAcceptance_stat_ISig_ 7 "TLInflationAccept_stat_NotAvailable" 6 "TLInflationAccept_stat_Error" 5 "TLInflationAccept_stat_Spare4" 4 "TLInflationAccept_stat_Spare3" 3 "TLInflationAccept_stat_Spare2" 2 "TLInflationAccept_stat_TrailerInflationAccepted" 1 "TLInflationAccept_stat_BrakePedalRequested" 0 "TLInflationAccept_stat_NoRequestDetectedOrRequestAborted" ;
VAL_ 690 AutoLoadCutOffState_ISig_5 7 "AutoLoadCutOffState_NotAvailable" 6 "AutoLoadCutOffState_Error" 5 "AutoLoadCutOffState_Spare4" 4 "AutoLoadCutOffState_Spare3" 3 "AutoLoadCutOffState_Spare2" 2 "AutoLoadCutOffState_Spare1" 1 "AutoLoadCutOffState_RequestON" 0 "AutoLoadCutOffState_NoRequest" ;
VAL_ 690 TransmissionOilTempHigh_ISig_5 7 "TransmissionOilTempHigh_NotAvailable" 6 "TransmissionOilTempHigh_ErrorIndicator" 5 "TransmissionOilTempHigh_SpareValue_02" 4 "TransmissionOilTempHigh_SpareValue_01" 3 "TransmissionOilTempHigh_SpareValue" 2 "TransmissionOilTempHigh_ActiveVeryHighTemp" 1 "TransmissionOilTempHigh_ActiveHighTemp" 0 "TransmissionOilTempHigh_Inactive" ;
VAL_ 690 ECSLimpHomeNotification_ISig_5 7 "ECSLimpHomeNotification_NotAvailable" 6 "ECSLimpHomeNotification_Error" 5 "ECSLimpHomeNotification_LimpHomeMode5" 4 "ECSLimpHomeNotification_LimpHomeMode4" 3 "ECSLimpHomeNotification_LimpHomeMode3" 2 "ECSLimpHomeNotification_LimpHomeMode2" 1 "ECSLimpHomeNotification_LimpHomeMode1" 0 "ECSLimpHomeNotification_NoLimpHomeMode" ;
VAL_ 690 EqualizerUnbalance_ISig_5 7 "NoWarning3bit_NotAvailable" 6 "NoWarning3bit_Error" 5 "NoWarning3bit_Spare4" 4 "NoWarning3bit_Spare3" 3 "NoWarning3bit_Spare2" 2 "NoWarning3bit_Spare1" 1 "NoWarning3bit_Warning" 0 "NoWarning3bit_NoWarning" ;
VAL_ 690 AutGearSplitPosition_ISig_5 7 "GearSplitPosition_NotAvailable" 6 "GearSplitPosition_Error" 5 "GearSplitPosition_Spare2" 4 "GearSplitPosition_Spare1" 3 "GearSplitPosition_Crawler" 2 "GearSplitPosition_NoSplit" 1 "GearSplitPosition_HighSplit" 0 "GearSplitPosition_LowSplit" ;
VAL_ 690 BatterySOCAlert_rqst_ISig_5 7 "BatterySOCAlert_rqst_NotAvailable" 6 "BatterySOCAlert_rqst_ErrorIndicator" 5 "BatterySOCAlert_rqst_SpareValue_02" 4 "BatterySOCAlert_rqst_SpareValue_01" 3 "BatterySOCAlert_rqst_SpareValue" 2 "BatterySOCAlert_rqst_CriticalAlert" 1 "BatterySOCAlert_rqst_PreAlert" 0 "BatterySOCAlert_rqst_NoAlertRequested" ;
VAL_ 690 DriveModeSwitchUserOverride_ISig 7 "DriveModeSwitchUserOverride_NotAvailable" 6 "DriveModeSwitchUserOverride_Error" 5 "DriveModeSwitchUserOverride_Spare" 4 "DriveModeSwitchUserOverride_OverrideStandard" 3 "DriveModeSwitchUserOverride_RequestRange" 2 "DriveModeSwitchUserOverride_OverridePerformance" 1 "DriveModeSwitchUserOverride_AutoSwitch" 0 "DriveModeSwitchUserOverride_None" ;
VAL_ 690 BatteryTempAlert_rqst_ISig_5 7 "BatteryTempAlert_rqst_NotAvailable" 6 "BatteryTempAlert_rqst_Error" 5 "BatteryTempAlert_rqst_Spare3" 4 "BatteryTempAlert_rqst_Spare2" 3 "BatteryTempAlert_rqst_Spare1" 2 "BatteryTempAlert_rqst_CriticalAlertLowTemp" 1 "BatteryTempAlert_rqst_PreAlertLowTemp" 0 "BatteryTempAlert_rqst_NoAlertRequested" ;
VAL_ 690 TrailerEBSFault_ISig_5 3 "OkNok_NotAvailable" 2 "OkNok_Error" 1 "OkNok_NotOK" 0 "OkNok_OK" ;
SIG_GROUP_ 1201 DiagFaultStat_BBIOM_sg 1 : DiagFaultStat_BBIOM_DtcIdB DiagFaultStat_BBIOM_DtcIdA DiagFaultStat_BBIOM_FailTB DiagFaultStat_BBIOM_FailTA DiagFaultStat_BBIOM_EcuAdr;
SIG_GROUP_ 901 OilLevelDrvInstr_sg_ISig_5 1 : OilLevelDrvInstr_IncorrEngSpe_IS OilLevelDrvInstr_ChangeGearTxt_I OilLevelDrvInstr_Wait60SecTxt_IS OilLevelDrvInstr_OilTempTxt_ISig OilLevelDrvInstr_StopVehicle_ISi OilLevelDrvInstr_NotHorizonTxt_I;
SIG_GROUP_ 868 FrontConspicLamp_stat_sg_ISig_5 1 : FrontConspicLamp_stat_HiRight_IS FrontConspicLamp_stat_LoRight_IS FrontConspicLamp_stat_LoLeft_ISi FrontConspicLamp_stat_HiLeft_ISi;
SIG_GROUP_ 696 RedGladHand_sg_ISig_5 1 : RedGladHand_SqC_ISig_5 RedGladHand_CRC_ISig_5 RedGladHand_ConfidenceLvl_ISig_5 RedGladHand_ConnectStatus_ISig_5;
SIG_GROUP_ 696 TrailerStatus_sg_ISig_5 1 : TrailerStatus_IntegrityLvl_ISig_ TrailerStatus_CRC_ISig_5 TrailerStatus_SqC_ISig_5 TrailerStatus_Actuation_ISig_5;
SIG_GROUP_ 695 TrafficSitPathEvent2_sg 1 : TrafficSitPathEvent2_Type TrafficSitPathEvent2_Speed TrafficSitPathEvent2_Distance;
SIG_GROUP_ 695 TrafficSitPathEvent1_sg 1 : TrafficSitPathEvent1_Distance TrafficSitPathEvent1_Speed TrafficSitPathEvent1_Type;
